VERSION ""

NS_ :

BS_:

BU_: ADAS ADASBUS_Virtual_ECU FCM GW PKC

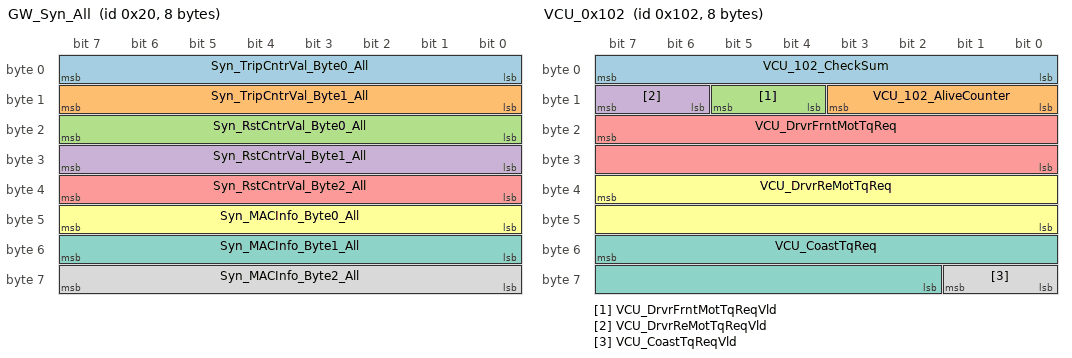
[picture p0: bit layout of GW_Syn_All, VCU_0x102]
BO_ 32 GW_Syn_All: 8 GW
 SG_ Syn_TripCntrVal_Byte0_All : 7|8@0+ (1,0) [0|255] ""  ADAS,PKC
 SG_ Syn_TripCntrVal_Byte1_All : 15|8@0+ (1,0) [0|255] ""  ADAS,PKC
 SG_ Syn_RstCntrVal_Byte0_All : 23|8@0+ (1,0) [0|255] ""  ADAS,PKC
 SG_ Syn_RstCntrVal_Byte1_All : 31|8@0+ (1,0) [0|255] ""  ADAS,PKC
 SG_ Syn_RstCntrVal_Byte2_All : 39|8@0+ (1,0) [0|255] ""  ADAS,PKC
 SG_ Syn_MACInfo_Byte0_All : 47|8@0+ (1,0) [0|255] ""  ADAS,PKC
 SG_ Syn_MACInfo_Byte1_All : 55|8@0+ (1,0) [0|255] ""  ADAS,PKC
 SG_ Syn_MACInfo_Byte2_All : 63|8@0+ (1,0) [0|255] ""  ADAS,PKC

BO_ 258 VCU_0x102: 8 GW
 SG_ VCU_102_CheckSum : 7|8@0+ (1,0) [0|255] ""  FCM
 SG_ VCU_102_AliveCounter : 11|4@0+ (1,0) [0|14] ""  FCM
 SG_ VCU_DrvrFrntMotTqReqVld : 13|2@0+ (1,0) [0|3] ""  ADASBUS_Virtual_ECU
 SG_ VCU_DrvrReMotTqReqVld : 15|2@0+ (1,0) [0|3] ""  ADASBUS_Virtual_ECU
 SG_ VCU_DrvrFrntMotTqReq : 23|16@0+ (1,-32768) [-32768|32767] "Nm"  ADASBUS_Virtual_ECU
 SG_ VCU_DrvrReMotTqReq : 39|16@0+ (1,-32768) [-32768|32767] "Nm"  ADASBUS_Virtual_ECU
 SG_ VCU_CoastTqReq : 55|14@0+ (1,-16383) [-16383|0] "Nm"  FCM
 SG_ VCU_CoastTqReqVld : 57|2@0+ (1,0) [0|3] ""  FCM

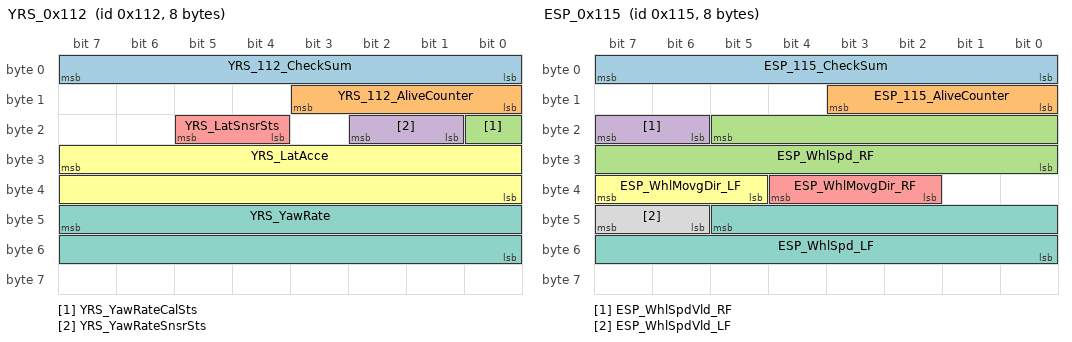
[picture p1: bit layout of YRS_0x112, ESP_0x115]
BO_ 274 YRS_0x112: 8 GW
 SG_ YRS_112_CheckSum : 7|8@0+ (1,0) [0|255] ""  ADAS,FCM
 SG_ YRS_112_AliveCounter : 11|4@0+ (1,0) [0|14] ""  ADAS,FCM
 SG_ YRS_YawRateCalSts : 16|1@0+ (1,0) [0|1] ""  ADAS,FCM
 SG_ YRS_YawRateSnsrSts : 18|2@0+ (1,0) [0|3] ""  ADAS,FCM
 SG_ YRS_LatSnsrSts : 21|2@0+ (1,0) [0|3] ""  ADAS,FCM
 SG_ YRS_LatAcce : 31|16@0+ (0.001,-2) [-2|2] "g"  ADAS,FCM
 SG_ YRS_YawRate : 47|16@0+ (0.01,-180) [-180|180] "deg/s"  ADAS,FCM

BO_ 275 YRS_0x113: 8 GW
 SG_ YRS_113_CheckSum : 7|8@0+ (1,0) [0|255] ""  ADAS,FCM
 SG_ YRS_113_AliveCounter : 11|4@0+ (1,0) [0|14] ""  ADAS,FCM
 SG_ YRS_LgtSnsrSts : 17|2@0+ (1,0) [0|3] ""  ADAS,FCM
 SG_ YRS_LgtAcce : 31|16@0+ (0.001,-2) [-2|2] "g"  ADAS,FCM

BO_ 276 ESP_0x114: 8 GW
 SG_ ESP_114_CheckSum : 7|8@0+ (1,0) [0|255] ""  ADAS,FCM
 SG_ ESP_114_AliveCounter : 11|4@0+ (1,0) [0|14] ""  ADAS,FCM
 SG_ ESP_OTARdy_Fb : 13|2@0+ (1,0) [0|3] ""  ADASBUS_Virtual_ECU
 SG_ ESP_FltIndcn_DTC : 15|1@0+ (1,0) [0|1] ""  ADAS
 SG_ ESP_ActvSig_VDC : 16|1@0+ (1,0) [0|1] ""  ADAS,FCM
 SG_ ESP_ActvSig_TCS : 17|1@0+ (1,0) [0|1] ""  ADAS
 SG_ ESP_ActvSig_EBD : 19|1@0+ (1,0) [0|1] ""  ADAS
 SG_ ESP_ActvSig_DTC : 20|1@0+ (1,0) [0|1] ""  ADAS
 SG_ ESP_WarningOn : 22|2@0+ (1,0) [0|3] ""  ADAS
 SG_ ESP_Actvndcn_CDD : 24|1@0+ (1,0) [0|1] ""  ADAS
 SG_ ESP_FltIndcn_CDD : 25|1@0+ (1,0) [0|1] ""  ADAS
 SG_ ESP_ActvIndcn_ABA : 26|1@0+ (1,0) [0|1] ""  ADAS
 SG_ ESP_FltIndcn_ABA : 27|1@0+ (1,0) [0|1] ""  ADAS
 SG_ ESP_ActvIndcn_ABP : 28|1@0+ (1,0) [0|1] ""  ADAS
 SG_ ESP_FltIndcn_ABP : 29|1@0+ (1,0) [0|1] ""  ADAS
 SG_ ESP_ActvIndcn_AEB : 30|1@0+ (1,0) [0|1] ""  ADAS,FCM
 SG_ ESP_FltIndcn_AEB : 31|1@0+ (1,0) [0|1] ""  ADAS,FCM
 SG_ ESP_ActvIndcn_AWB : 32|1@0+ (1,0) [0|1] ""  ADAS
 SG_ ESP_FltIndcn_AWB : 33|1@0+ (1,0) [0|1] ""  ADAS
 SG_ ESP_VehStandstillIndcn : 35|2@0+ (1,0) [0|3] ""  ADAS,FCM
 SG_ ESP_BrkOverTIndcn : 36|1@0+ (1,0) [0|1] ""  ADAS
 SG_ ESP_FltIndcn_VDC : 37|1@0+ (1,0) [0|1] ""  ADAS
 SG_ ESP_ActvIndcn_CDD_AP : 42|1@0+ (1,0) [0|1] ""  ADAS
 SG_ ESP_FltIndcn_CDD_AP : 43|1@0+ (1,0) [0|1] ""  ADAS

BO_ 277 ESP_0x115: 8 GW
 SG_ ESP_115_CheckSum : 7|8@0+ (1,0) [0|255] ""  ADAS,FCM,PKC
 SG_ ESP_115_AliveCounter : 11|4@0+ (1,0) [0|14] ""  ADAS,FCM,PKC
 SG_ ESP_WhlSpd_RF : 21|14@0+ (0.0625,0) [0|300] "km/h"  ADAS,FCM,PKC
 SG_ ESP_WhlSpdVld_RF : 23|2@0+ (1,0) [0|3] ""  ADAS,FCM,PKC
 SG_ ESP_WhlMovgDir_RF : 36|3@0+ (1,0) [0|7] ""  ADAS,FCM
 SG_ ESP_WhlMovgDir_LF : 39|3@0+ (1,0) [0|7] ""  ADAS,FCM
 SG_ ESP_WhlSpd_LF : 45|14@0+ (0.0625,0) [0|300] "km/h"  ADAS,FCM,PKC
 SG_ ESP_WhlSpdVld_LF : 47|2@0+ (1,0) [0|3] ""  ADAS,FCM,PKC

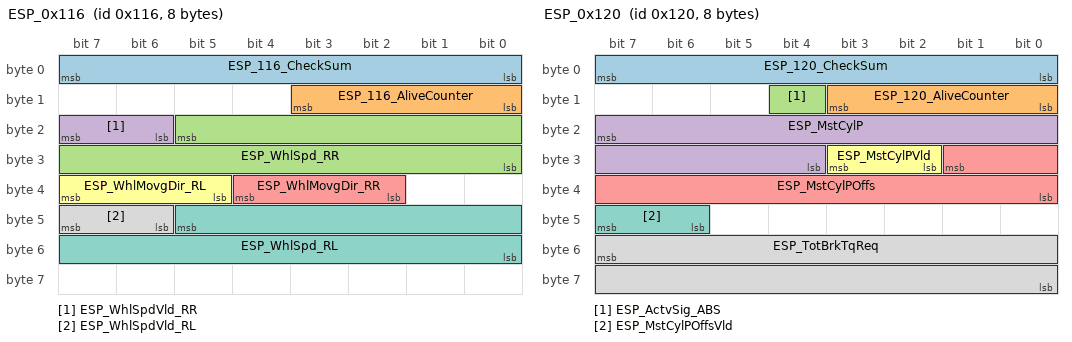
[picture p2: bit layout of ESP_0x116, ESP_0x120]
BO_ 278 ESP_0x116: 8 GW
 SG_ ESP_116_CheckSum : 7|8@0+ (1,0) [0|255] ""  ADAS,FCM,PKC
 SG_ ESP_116_AliveCounter : 11|4@0+ (1,0) [0|14] ""  ADAS,FCM,PKC
 SG_ ESP_WhlSpd_RR : 21|14@0+ (0.0625,0) [0|300] "km/h"  ADAS,FCM,PKC
 SG_ ESP_WhlSpdVld_RR : 23|2@0+ (1,0) [0|3] ""  ADAS,FCM,PKC
 SG_ ESP_WhlMovgDir_RR : 36|3@0+ (1,0) [0|7] ""  ADAS,FCM
 SG_ ESP_WhlMovgDir_RL : 39|3@0+ (1,0) [0|7] ""  ADAS,FCM
 SG_ ESP_WhlSpd_RL : 45|14@0+ (0.0625,0) [0|300] "km/h"  ADAS,FCM,PKC
 SG_ ESP_WhlSpdVld_RL : 47|2@0+ (1,0) [0|3] ""  ADAS,FCM,PKC

BO_ 279 ADAS_0x117: 8 ADAS
 SG_ ADAS_117_CheckSum : 7|8@0+ (1,0) [0|255] ""  GW
 SG_ ADAS_117_AliveCounter : 11|4@0+ (1,0) [0|14] ""  GW
 SG_ ADAS_OTARdy_Fb : 13|2@0+ (1,0) [0|3] ""  GW
 SG_ ADAS_OTAInhbRdy : 15|2@0+ (1,0) [0|3] ""  GW
 SG_ ADAS_LgtCtrl_Sts : 18|3@0+ (1,0) [0|7] ""  GW
 SG_ ADAS_LgtCtrl_StsVld : 20|2@0+ (1,0) [0|3] ""  GW
 SG_ ADAS_LgtCtrl_DrvrOvrdSts : 21|1@0+ (1,0) [0|1] ""  GW
 SG_ ADAS_LgtCtrl_DrvrOvrdVld : 23|2@0+ (1,0) [0|3] ""  GW
 SG_ ADAS_HAP_EmgyStandstillVld : 25|2@0+ (1,0) [0|3] ""  GW
 SG_ ADAS_HAP_EmgyEPBVld : 27|2@0+ (1,0) [0|3] ""  GW
 SG_ ADAS_HAP_EmgyStandstillReq : 28|1@0+ (1,0) [0|1] ""  GW
 SG_ ADAS_ParkStandstillReq : 29|1@0+ (1,0) [0|1] ""  GW
 SG_ ADAS_ParkStandstillVld : 31|2@0+ (1,0) [0|3] ""  GW
 SG_ ADAS_ParkGearReq : 35|4@0+ (1,0) [0|15] ""  GW
 SG_ ADAS_ParkGearReqVld : 37|2@0+ (1,0) [0|3] ""  GW
 SG_ ADAS_ISA_CutOffReqVld : 39|2@0+ (1,0) [0|3] ""  GW
 SG_ ADAS_LgtCtrl_Typ : 43|4@0+ (1,0) [0|15] ""  GW
 SG_ ADAS_HAP_EmgyEPBReq : 44|1@0+ (1,0) [0|1] ""  GW
 SG_ ADAS_ISA_CutOffReq : 46|1@0+ (1,0) [0|1] ""  GW
 SG_ ADAS_ISA_SpdLmt_VCU : 63|8@0+ (1,0) [0|255] "kph"  GW

BO_ 280 ADAS_0x118: 8 ADAS
 SG_ ADAS_118_CheckSum : 7|8@0+ (1,0) [0|255] ""  GW
 SG_ ADAS_118_AliveCounter : 11|4@0+ (1,0) [0|14] ""  GW
 SG_ ADAS_LgtCtrl_ESP_Sts : 18|3@0+ (1,0) [0|7] ""  GW
 SG_ ADAS_LgtCtrl_ESP_Vld : 20|2@0+ (1,0) [0|3] ""  GW
 SG_ ADAS_ESP_DrvrOvrdSts : 21|1@0+ (1,0) [0|1] ""  GW
 SG_ ADAS_ESP_DrvrOvrdVld : 23|2@0+ (1,0) [0|3] ""  GW
 SG_ ADAS_HBAReq : 26|3@0+ (1,0) [0|7] ""  GW
 SG_ ADAS_HBAVld : 28|2@0+ (1,0) [0|3] ""  GW
 SG_ ADAS_ESP_StandstillReq : 29|1@0+ (1,0) [0|1] ""  GW
 SG_ ADAS_ESP_StandstillVld : 31|2@0+ (1,0) [0|3] ""  GW
 SG_ ADAS_JerkReq : 33|2@0+ (1,0) [0|3] ""  GW
 SG_ ADAS_JerkReqVld : 35|2@0+ (1,0) [0|3] ""  GW
 SG_ ADAS_BrkPrefillReq : 37|2@0+ (1,0) [0|3] ""  GW
 SG_ ADAS_BrkPrefillVld : 39|2@0+ (1,0) [0|3] ""  GW
 SG_ ADAS_AEB_ActvTyp : 43|4@0+ (1,0) [0|15] ""  GW
 SG_ ADAS_AEB_DecelVld : 45|2@0+ (1,0) [0|3] ""  GW
 SG_ ADAS_AEB_DecelReq : 55|16@0+ (0.0004882,-16) [-16|15.994187] "m/s2"  GW

BO_ 288 ESP_0x120: 8 GW
 SG_ ESP_120_CheckSum : 7|8@0+ (1,0) [0|255] ""  ADAS,FCM
 SG_ ESP_120_AliveCounter : 11|4@0+ (1,0) [0|14] ""  ADAS,FCM
 SG_ ESP_ActvSig_ABS : 12|1@0+ (1,0) [0|1] ""  ADAS,FCM
 SG_ ESP_MstCylP : 23|12@0+ (0.1,-30) [-30|276.6] "bar"  ADAS,FCM
 SG_ ESP_MstCylPOffs : 25|10@0+ (0.1,-15) [-15|15] "bar"  ADAS,FCM
 SG_ ESP_MstCylPVld : 27|2@0+ (1,0) [0|3] ""  ADAS,FCM
 SG_ ESP_MstCylPOffsVld : 47|2@0+ (1,0) [0|3] ""  ADAS,FCM
 SG_ ESP_TotBrkTqReq : 55|16@0+ (1,-30000) [-30000|30000] "Nm"  ADAS

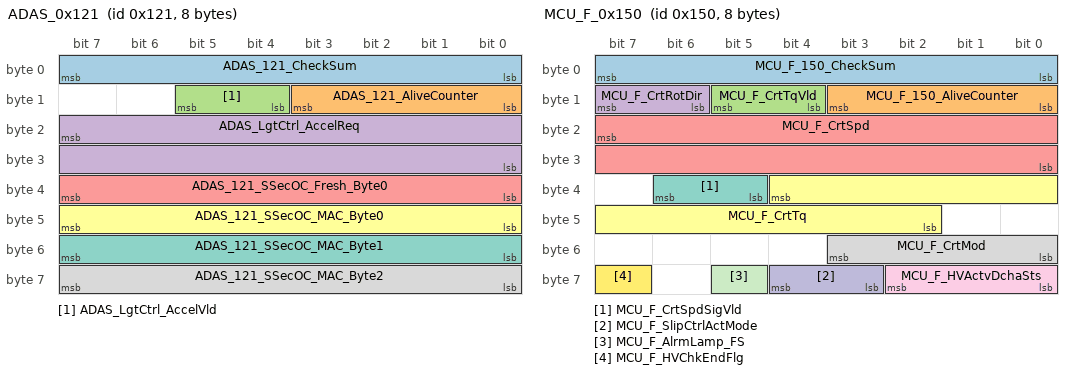
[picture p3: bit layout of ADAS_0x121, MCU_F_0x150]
BO_ 289 ADAS_0x121: 8 ADAS
 SG_ ADAS_121_CheckSum : 7|8@0+ (1,0) [0|255] ""  GW
 SG_ ADAS_121_AliveCounter : 11|4@0+ (1,0) [0|14] ""  GW
 SG_ ADAS_LgtCtrl_AccelVld : 13|2@0+ (1,0) [0|3] ""  GW
 SG_ ADAS_LgtCtrl_AccelReq : 23|16@0+ (0.0004882,-16) [-16|15.994187] "m/s2"  GW
 SG_ ADAS_121_SSecOC_Fresh_Byte0 : 39|8@0+ (1,0) [0|255] ""  GW
 SG_ ADAS_121_SSecOC_MAC_Byte0 : 47|8@0+ (1,0) [0|255] ""  GW
 SG_ ADAS_121_SSecOC_MAC_Byte1 : 55|8@0+ (1,0) [0|255] ""  GW
 SG_ ADAS_121_SSecOC_MAC_Byte2 : 63|8@0+ (1,0) [0|255] ""  GW

BO_ 336 MCU_F_0x150: 8 GW
 SG_ MCU_F_150_CheckSum : 7|8@0+ (1,0) [0|255] ""  ADAS
 SG_ MCU_F_150_AliveCounter : 11|4@0+ (1,0) [0|14] ""  ADAS
 SG_ MCU_F_CrtTqVld : 13|2@0+ (1,0) [0|3] ""  ADAS
 SG_ MCU_F_CrtRotDir : 15|2@0+ (1,0) [0|3] ""  ADAS
 SG_ MCU_F_CrtSpd : 23|16@0+ (1,-32768) [-32768|32767] "rpm"  ADAS,FCM,PKC
 SG_ MCU_F_CrtTq : 36|11@0+ (0.5,-511) [-511|512] "Nm"  ADAS
 SG_ MCU_F_CrtSpdSigVld : 38|2@0+ (1,0) [0|3] ""  ADAS,FCM,PKC
 SG_ MCU_F_CrtMod : 51|4@0+ (1,0) [0|15] ""  ADASBUS_Virtual_ECU
 SG_ MCU_F_HVActvDchaSts : 58|3@0+ (1,0) [0|7] ""  ADASBUS_Virtual_ECU
 SG_ MCU_F_SlipCtrlActMode : 60|2@0+ (1,0) [0|3] ""  ADAS
 SG_ MCU_F_AlrmLamp_FS : 61|1@0+ (1,0) [0|1] ""  ADASBUS_Virtual_ECU
 SG_ MCU_F_HVChkEndFlg : 63|1@0+ (1,0) [0|1] ""  ADASBUS_Virtual_ECU

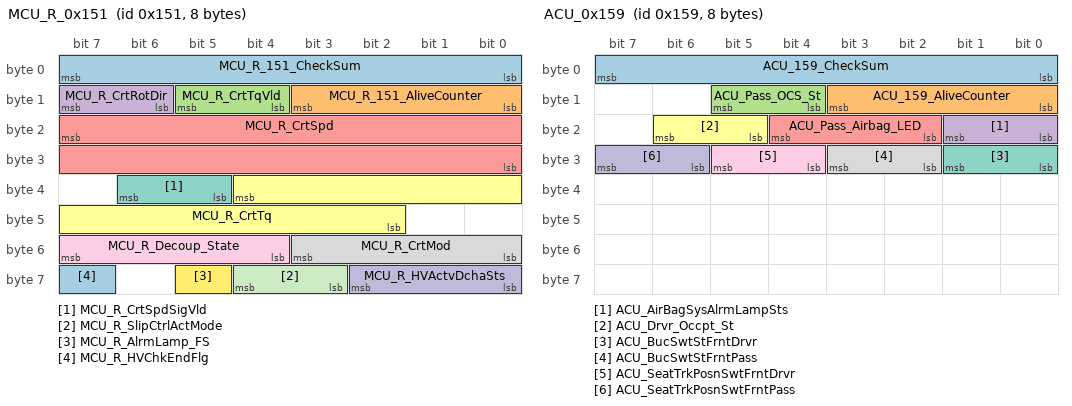
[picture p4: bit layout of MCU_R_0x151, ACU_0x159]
BO_ 337 MCU_R_0x151: 8 GW
 SG_ MCU_R_151_CheckSum : 7|8@0+ (1,0) [0|255] ""  ADAS,ADASBUS_Virtual_ECU
 SG_ MCU_R_151_AliveCounter : 11|4@0+ (1,0) [0|14] ""  ADAS,ADASBUS_Virtual_ECU
 SG_ MCU_R_CrtTqVld : 13|2@0+ (1,0) [0|3] ""  ADAS
 SG_ MCU_R_CrtRotDir : 15|2@0+ (1,0) [0|3] ""  ADAS
 SG_ MCU_R_CrtSpd : 23|16@0+ (1,-32768) [-32768|32767] "rpm"  ADAS,FCM,PKC
 SG_ MCU_R_CrtTq : 36|11@0+ (0.5,-511) [-511|512] "Nm"  ADAS
 SG_ MCU_R_CrtSpdSigVld : 38|2@0+ (1,0) [0|3] ""  ADAS,FCM,PKC
 SG_ MCU_R_CrtMod : 51|4@0+ (1,0) [0|15] ""  ADASBUS_Virtual_ECU
 SG_ MCU_R_Decoup_State : 55|4@0+ (1,0) [0|15] ""  ADASBUS_Virtual_ECU
 SG_ MCU_R_HVActvDchaSts : 58|3@0+ (1,0) [0|7] ""  ADASBUS_Virtual_ECU
 SG_ MCU_R_SlipCtrlActMode : 60|2@0+ (1,0) [0|3] ""  ADAS
 SG_ MCU_R_AlrmLamp_FS : 61|1@0+ (1,0) [0|1] ""  ADASBUS_Virtual_ECU
 SG_ MCU_R_HVChkEndFlg : 63|1@0+ (1,0) [0|1] ""  ADASBUS_Virtual_ECU

BO_ 345 ACU_0x159: 8 GW
 SG_ ACU_159_CheckSum : 7|8@0+ (1,0) [0|255] ""  ADAS,FCM
 SG_ ACU_159_AliveCounter : 11|4@0+ (1,0) [0|14] ""  ADAS,FCM
 SG_ ACU_Pass_OCS_St : 13|2@0+ (1,0) [0|3] ""  PKC
 SG_ ACU_AirBagSysAlrmLampSts : 17|2@0+ (1,0) [0|3] ""  ADAS
 SG_ ACU_Pass_Airbag_LED : 20|3@0+ (1,0) [0|7] ""  ADAS
 SG_ ACU_Drvr_Occpt_St : 22|2@0+ (1,0) [0|3] ""  ADAS,FCM,PKC
 SG_ ACU_BucSwtStFrntDrvr : 25|2@0+ (1,0) [0|3] ""  ADAS,FCM
 SG_ ACU_BucSwtStFrntPass : 27|2@0+ (1,0) [0|3] ""  ADAS
 SG_ ACU_SeatTrkPosnSwtFrntDrvr : 29|2@0+ (1,0) [0|3] ""  ADASBUS_Virtual_ECU
 SG_ ACU_SeatTrkPosnSwtFrntPass : 31|2@0+ (1,0) [0|3] ""  ADASBUS_Virtual_ECU

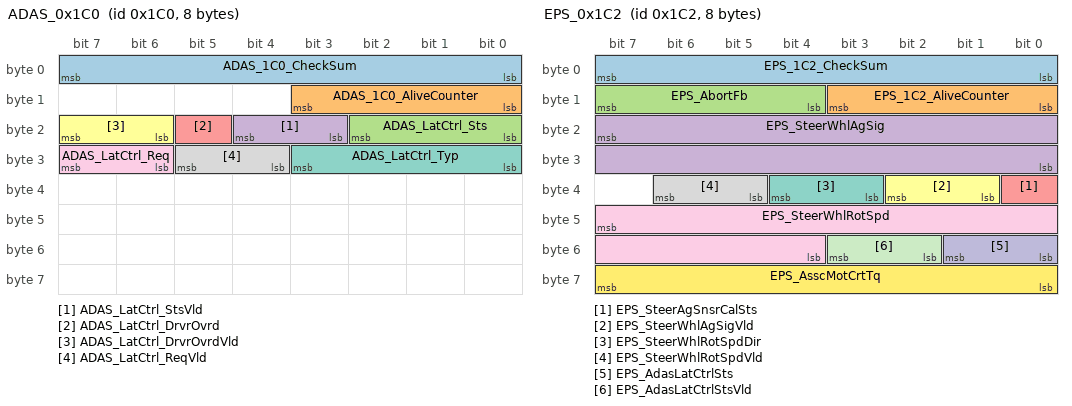
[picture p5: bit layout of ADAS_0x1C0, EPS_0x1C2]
BO_ 448 ADAS_0x1C0: 8 ADAS
 SG_ ADAS_1C0_CheckSum : 7|8@0+ (1,0) [0|255] ""  GW
 SG_ ADAS_1C0_AliveCounter : 11|4@0+ (1,0) [0|14] ""  GW
 SG_ ADAS_LatCtrl_Sts : 18|3@0+ (1,0) [0|7] ""  GW
 SG_ ADAS_LatCtrl_StsVld : 20|2@0+ (1,0) [0|3] ""  GW
 SG_ ADAS_LatCtrl_DrvrOvrd : 21|1@0+ (1,0) [0|1] ""  GW
 SG_ ADAS_LatCtrl_DrvrOvrdVld : 23|2@0+ (1,0) [0|3] ""  GW
 SG_ ADAS_LatCtrl_Typ : 27|4@0+ (1,0) [0|15] ""  GW
 SG_ ADAS_LatCtrl_ReqVld : 29|2@0+ (1,0) [0|3] ""  GW
 SG_ ADAS_LatCtrl_Req : 31|2@0+ (1,0) [0|3] ""  GW

BO_ 450 EPS_0x1C2: 8 GW
 SG_ EPS_1C2_CheckSum : 7|8@0+ (1,0) [0|255] ""  ADAS,FCM,PKC
 SG_ EPS_1C2_AliveCounter : 11|4@0+ (1,0) [0|14] ""  ADAS,FCM,PKC
 SG_ EPS_AbortFb : 15|4@0+ (1,0) [0|15] ""  ADAS
 SG_ EPS_SteerWhlAgSig : 23|16@0+ (0.0625,-780) [-780|780] "deg"  ADAS,FCM,PKC
 SG_ EPS_SteerAgSnsrCalSts : 32|1@0+ (1,0) [0|1] ""  ADAS,FCM
 SG_ EPS_SteerWhlAgSigVld : 34|2@0+ (1,0) [0|3] ""  ADAS,FCM
 SG_ EPS_SteerWhlRotSpdDir : 36|2@0+ (1,0) [0|3] ""  ADAS
 SG_ EPS_SteerWhlRotSpdVld : 38|2@0+ (1,0) [0|3] ""  ADAS,FCM
 SG_ EPS_SteerWhlRotSpd : 47|12@0+ (0.5,-1016) [-1016|1016] "deg/s"  ADAS,FCM
 SG_ EPS_AdasLatCtrlSts : 49|2@0+ (1,0) [0|3] ""  ADAS
 SG_ EPS_AdasLatCtrlStsVld : 51|2@0+ (1,0) [0|3] ""  ADAS
 SG_ EPS_AsscMotCrtTq : 63|8@0+ (0.1,0) [0|10] "Nm"  ADASBUS_Virtual_ECU

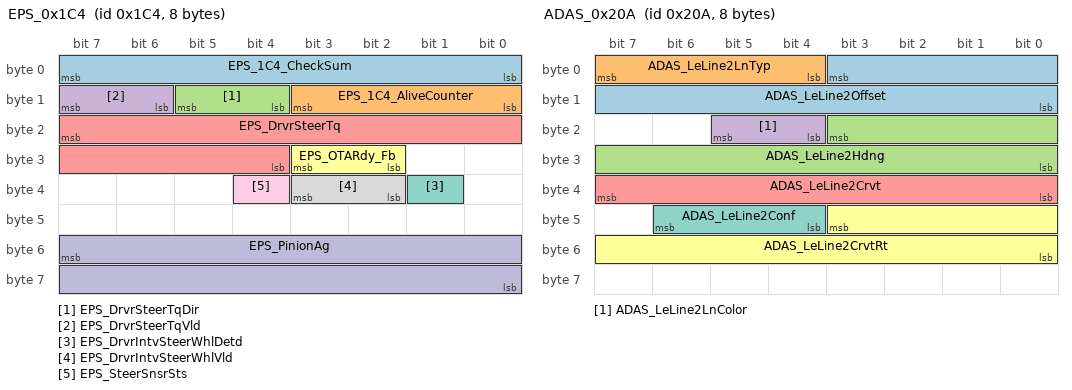
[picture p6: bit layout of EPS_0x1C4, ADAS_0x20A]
BO_ 452 EPS_0x1C4: 8 GW
 SG_ EPS_1C4_CheckSum : 7|8@0+ (1,0) [0|255] ""  ADAS,FCM
 SG_ EPS_1C4_AliveCounter : 11|4@0+ (1,0) [0|14] ""  ADAS,FCM
 SG_ EPS_DrvrSteerTqDir : 13|2@0+ (1,0) [0|3] ""  ADAS
 SG_ EPS_DrvrSteerTqVld : 15|2@0+ (1,0) [0|3] ""  ADAS
 SG_ EPS_DrvrSteerTq : 23|12@0+ (0.01,0) [0|8] "Nm"  ADAS
 SG_ EPS_OTARdy_Fb : 27|2@0+ (1,0) [0|3] ""  ADASBUS_Virtual_ECU
 SG_ EPS_DrvrIntvSteerWhlDetd : 33|1@0+ (1,0) [0|1] ""  ADAS
 SG_ EPS_DrvrIntvSteerWhlVld : 35|2@0+ (1,0) [0|3] ""  ADAS
 SG_ EPS_SteerSnsrSts : 36|1@0+ (1,0) [0|1] ""  ADAS,FCM
 SG_ EPS_PinionAg : 55|16@0+ (0.0625,-780) [-780|780] "deg"  ADAS

BO_ 464 ADAS_0x1D0: 8 ADAS
 SG_ ADAS_1D0_CheckSum : 7|8@0+ (1,0) [0|255] ""  GW
 SG_ ADAS_1D0_AliveCounter : 11|4@0+ (1,0) [0|14] ""  GW
 SG_ ADAS_LatCtrl_SteerAnReq : 23|16@0+ (0.0625,-780) [-780|780] "deg"  GW
 SG_ ADAS_1D0_SSecOC_Fresh_Byte0 : 39|8@0+ (1,0) [0|255] ""  GW
 SG_ ADAS_1D0_SSecOC_MAC_Byte0 : 47|8@0+ (1,0) [0|255] ""  GW
 SG_ ADAS_1D0_SSecOC_MAC_Byte1 : 55|8@0+ (1,0) [0|255] ""  GW
 SG_ ADAS_1D0_SSecOC_MAC_Byte2 : 63|8@0+ (1,0) [0|255] ""  GW

BO_ 522 ADAS_0x20A: 8 ADAS
 SG_ ADAS_LeLine2Offset : 3|12@0+ (0.0125,0) [0|50] "m"  GW
 SG_ ADAS_LeLine2LnTyp : 7|4@0+ (1,0) [0|15] ""  GW
 SG_ ADAS_LeLine2Hdng : 19|12@0+ (0.05,0) [0|180] "deg"  GW
 SG_ ADAS_LeLine2LnColor : 21|2@0+ (1,0) [0|3] ""  GW
 SG_ ADAS_LeLine2Crvt : 39|8@0+ (50,-3150) [-3150|3200] "m"  GW
 SG_ ADAS_LeLine2CrvtRt : 43|12@0+ (0.05,0) [0|180] "xx"  GW
 SG_ ADAS_LeLine2Conf : 46|3@0+ (1,0) [0|7] ""  GW

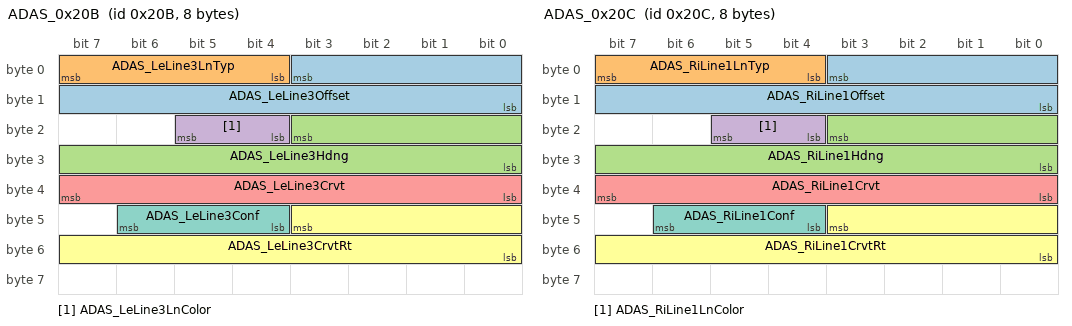
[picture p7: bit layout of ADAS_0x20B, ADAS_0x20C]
BO_ 523 ADAS_0x20B: 8 ADAS
 SG_ ADAS_LeLine3Offset : 3|12@0+ (0.0125,0) [0|50] "m"  GW
 SG_ ADAS_LeLine3LnTyp : 7|4@0+ (1,0) [0|15] ""  GW
 SG_ ADAS_LeLine3Hdng : 19|12@0+ (0.05,0) [0|180] "deg"  GW
 SG_ ADAS_LeLine3LnColor : 21|2@0+ (1,0) [0|3] ""  GW
 SG_ ADAS_LeLine3Crvt : 39|8@0+ (50,-3150) [-3150|3200] "m"  GW
 SG_ ADAS_LeLine3CrvtRt : 43|12@0+ (0.0125,0) [0|50] "xx"  GW
 SG_ ADAS_LeLine3Conf : 46|3@0+ (1,0) [0|7] ""  GW

BO_ 524 ADAS_0x20C: 8 ADAS
 SG_ ADAS_RiLine1Offset : 3|12@0+ (0.0125,0) [0|50] "m"  GW
 SG_ ADAS_RiLine1LnTyp : 7|4@0+ (1,0) [0|15] ""  GW
 SG_ ADAS_RiLine1Hdng : 19|12@0+ (0.05,0) [0|180] "deg"  GW
 SG_ ADAS_RiLine1LnColor : 21|2@0+ (1,0) [0|3] ""  GW
 SG_ ADAS_RiLine1Crvt : 39|8@0+ (50,-3150) [-3150|3200] "m"  GW
 SG_ ADAS_RiLine1CrvtRt : 43|12@0+ (0.0125,0) [0|50] "xx"  GW
 SG_ ADAS_RiLine1Conf : 46|3@0+ (1,0) [0|7] ""  GW

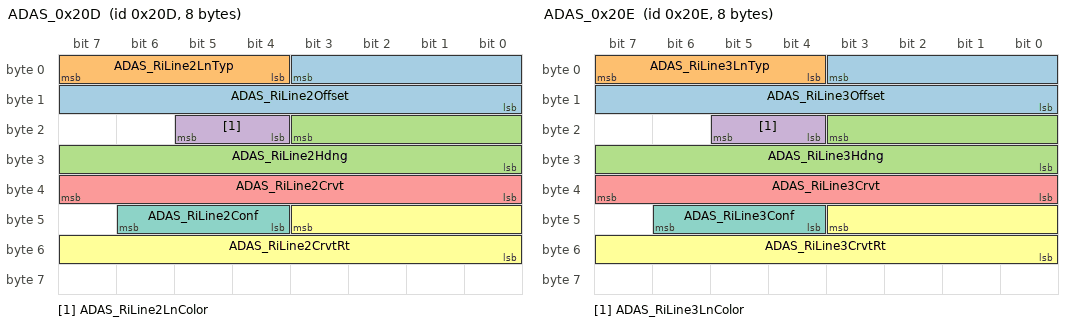
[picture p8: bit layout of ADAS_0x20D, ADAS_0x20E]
BO_ 525 ADAS_0x20D: 8 ADAS
 SG_ ADAS_RiLine2Offset : 3|12@0+ (0.0125,0) [0|50] "m"  GW
 SG_ ADAS_RiLine2LnTyp : 7|4@0+ (1,0) [0|15] ""  GW
 SG_ ADAS_RiLine2Hdng : 19|12@0+ (0.05,0) [0|180] "deg"  GW
 SG_ ADAS_RiLine2LnColor : 21|2@0+ (1,0) [0|3] ""  GW
 SG_ ADAS_RiLine2Crvt : 39|8@0+ (50,-3150) [-3150|3200] "m"  GW
 SG_ ADAS_RiLine2CrvtRt : 43|12@0+ (0.0125,0) [0|50] "xx"  GW
 SG_ ADAS_RiLine2Conf : 46|3@0+ (1,0) [0|7] ""  GW

BO_ 526 ADAS_0x20E: 8 ADAS
 SG_ ADAS_RiLine3Offset : 3|12@0+ (0.0125,0) [0|50] "m"  GW
 SG_ ADAS_RiLine3LnTyp : 7|4@0+ (1,0) [0|15] ""  GW
 SG_ ADAS_RiLine3Hdng : 19|12@0+ (0.05,0) [0|180] "deg"  GW
 SG_ ADAS_RiLine3LnColor : 21|2@0+ (1,0) [0|3] ""  GW
 SG_ ADAS_RiLine3Crvt : 39|8@0+ (50,-3150) [-3150|3200] "m"  GW
 SG_ ADAS_RiLine3CrvtRt : 43|12@0+ (0.0125,0) [0|50] "xx"  GW
 SG_ ADAS_RiLine3Conf : 46|3@0+ (1,0) [0|7] ""  GW

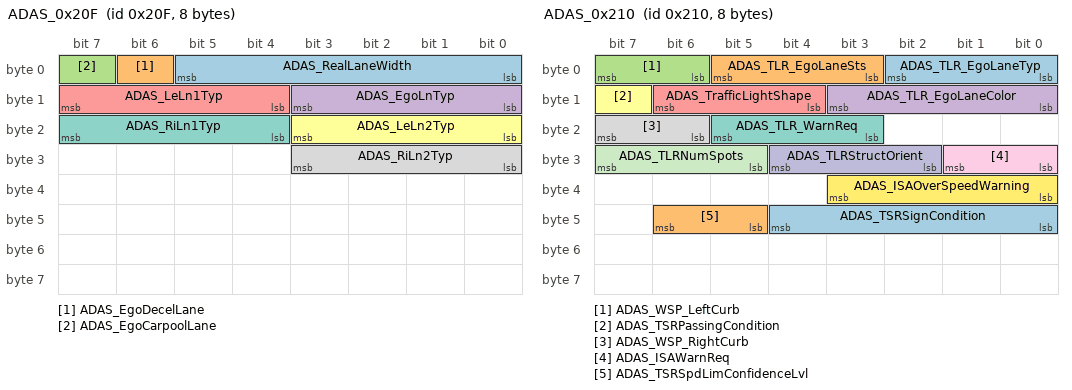
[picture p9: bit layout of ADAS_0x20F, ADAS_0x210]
BO_ 527 ADAS_0x20F: 8 ADAS
 SG_ ADAS_RealLaneWidth : 5|6@0+ (0.1,0) [0|6.3] "m"  GW
 SG_ ADAS_EgoDecelLane : 6|1@0+ (1,0) [0|1] ""  GW
 SG_ ADAS_EgoCarpoolLane : 7|1@0+ (1,0) [0|1] ""  GW
 SG_ ADAS_EgoLnTyp : 11|4@0+ (1,0) [0|15] ""  GW
 SG_ ADAS_LeLn1Typ : 15|4@0+ (1,0) [0|15] ""  GW
 SG_ ADAS_LeLn2Typ : 19|4@0+ (1,0) [0|15] ""  GW
 SG_ ADAS_RiLn1Typ : 23|4@0+ (1,0) [0|15] ""  GW
 SG_ ADAS_RiLn2Typ : 27|4@0+ (1,0) [0|15] ""  GW

BO_ 528 ADAS_0x210: 8 ADAS
 SG_ ADAS_TLR_EgoLaneTyp : 2|3@0+ (1,0) [0|7] ""  GW
 SG_ ADAS_TLR_EgoLaneSts : 5|3@0+ (1,0) [0|7] ""  GW
 SG_ ADAS_WSP_LeftCurb : 7|2@0+ (1,0) [0|3] ""  GW
 SG_ ADAS_TLR_EgoLaneColor : 11|4@0+ (1,0) [0|15] ""  GW
 SG_ ADAS_TrafficLightShape : 14|3@0+ (1,0) [0|7] ""  GW
 SG_ ADAS_TSRPassingCondition : 15|1@0+ (1,0) [0|1] ""  GW
 SG_ ADAS_TLR_WarnReq : 21|3@0+ (1,0) [0|7] ""  GW
 SG_ ADAS_WSP_RightCurb : 23|2@0+ (1,0) [0|3] ""  GW
 SG_ ADAS_ISAWarnReq : 25|2@0+ (1,0) [0|3] ""  GW
 SG_ ADAS_TLRStructOrient : 28|3@0+ (1,0) [0|7] ""  GW
 SG_ ADAS_TLRNumSpots : 31|3@0+ (1,0) [0|7] ""  GW
 SG_ ADAS_ISAOverSpeedWarning : 35|4@0+ (1,0) [0|15] ""  GW
 SG_ ADAS_TSRSignCondition : 44|5@0+ (1,0) [0|31] ""  GW
 SG_ ADAS_TSRSpdLimConfidenceLvl : 46|2@0+ (1,0) [0|3] ""  GW

BO_ 532 VCU_0x214: 16 GW
 SG_ VCU_214_234_CheckSum : 7|8@0+ (1,0) [0|255] ""  ADAS,FCM,PKC
 SG_ VCU_214_234_AliveCounter : 11|4@0+ (1,0) [0|14] ""  ADAS,FCM,PKC
 SG_ VCU_RdyLamp : 12|1@0+ (1,0) [0|1] ""  ADAS,PKC
 SG_ VCU_BrkLampCtrlSts : 14|1@0+ (1,0) [0|1] ""  ADASBUS_Virtual_ECU
 SG_ VCU_RemWakeUpEndFlg : 15|1@0+ (1,0) [0|1] ""  ADASBUS_Virtual_ECU
 SG_ VCU_StgyGearSig : 19|4@0+ (1,0) [0|15] ""  ADAS
 SG_ VCU_ShiftMisoper : 21|1@0+ (1,0) [0|1] ""  ADAS
 SG_ VCU_GearSigVld : 23|2@0+ (1,0) [0|3] ""  ADAS,FCM,PKC
 SG_ VCU_GearSig : 27|4@0+ (1,0) [0|15] ""  ADAS,FCM,PKC
 SG_ VCU_ACCRdy : 28|1@0+ (1,0) [0|1] ""  ADAS
 SG_ VCU_ParkRdy : 29|1@0+ (1,0) [0|1] ""  ADAS
 SG_ VCU_APSPercVld : 31|2@0+ (1,0) [0|3] ""  ADAS,FCM
 SG_ VCU_VehSt : 39|16@0+ (1,0) [0|65535] ""  ADAS
 SG_ VCU_APSPerc : 55|8@0+ (0.4,0) [0|100] "%"  ADAS,FCM
 SG_ VCU_BrkSig : 56|1@0+ (1,0) [0|1] ""  ADAS,FCM,PKC
 SG_ VCU_BrkSigVld : 58|2@0+ (1,0) [0|3] ""  ADAS,FCM,PKC
 SG_ VCU_DrvModSigFb : 61|3@0+ (1,0) [0|7] ""  ADAS
 SG_ VCU_DrvModShiftMisoper : 62|1@0+ (1,0) [0|1] ""  ADASBUS_Virtual_ECU
 SG_ VCU_SpclTerrainModEnaSig : 63|1@0+ (1,0) [0|1] ""  ADASBUS_Virtual_ECU
 SG_ VCU_214_SSecOC_Fresh_Byte0 : 71|8@0+ (1,0) [0|255] ""  ADASBUS_Virtual_ECU
 SG_ VCU_214_SSecOC_MAC_Byte0 : 79|8@0+ (1,0) [0|255] ""  ADASBUS_Virtual_ECU
 SG_ VCU_214_SSecOC_MAC_Byte1 : 87|8@0+ (1,0) [0|255] ""  ADASBUS_Virtual_ECU
 SG_ VCU_214_SSecOC_MAC_Byte2 : 95|8@0+ (1,0) [0|255] ""  ADASBUS_Virtual_ECU

BO_ 537 VCU_0x219: 8 GW
 SG_ VCU_219_CheckSum : 7|8@0+ (1,0) [0|255] ""  ADAS,PKC
 SG_ VCU_219_AliveCounter : 11|4@0+ (1,0) [0|14] ""  ADAS,PKC
 SG_ VCU_PreCdtFB : 13|2@0+ (1,0) [0|3] ""  ADASBUS_Virtual_ECU
 SG_ VCU_IMMO_Sts : 15|2@0+ (1,0) [0|3] ""  PKC
 SG_ VCU_RemCtrlDrvgSts : 23|3@0+ (1,0) [0|7] ""  PKC
 SG_ VCU_TioutPwrOffReq : 24|1@0+ (1,0) [0|1] ""  PKC
 SG_ VCU_RemCtrlDrvgEnaFlg : 25|1@0+ (1,0) [0|1] ""  ADAS,PKC
 SG_ VCU_RemCtrlDrvgEnaFlgVld : 27|2@0+ (1,0) [0|3] ""  ADAS
 SG_ VCU_RemCtrlDrvgPwrOnReq : 29|2@0+ (1,0) [0|3] ""  ADASBUS_Virtual_ECU
 SG_ VCU_RemCtrlDrvgExitFlg : 34|1@0+ (1,0) [0|1] ""  ADASBUS_Virtual_ECU
 SG_ VCU_RemCtrlDrvgRelsReq : 35|1@0+ (1,0) [0|1] ""  ADASBUS_Virtual_ECU
 SG_ VCU_RemCtrlDrvgExitDisp : 39|4@0+ (1,0) [0|15] ""  PKC
 SG_ VCU_RemCtrlDrvgBrkReq : 40|1@0+ (1,0) [0|1] ""  ADASBUS_Virtual_ECU
 SG_ VCU_RemCtrlDrvgEmgyBrkReq : 41|1@0+ (1,0) [0|1] ""  ADASBUS_Virtual_ECU
 SG_ VCU_RemCtrlDrvgModClsReq_VLC : 43|2@0+ (1,0) [0|3] ""  ADASBUS_Virtual_ECU
 SG_ VCU_DrvrIntvGearSigVld : 47|2@0+ (1,0) [0|3] ""  ADAS
 SG_ VCU_DrvrIntvGearSig : 48|1@0+ (1,0) [0|1] ""  ADAS
 SG_ VCU_GearUnderCtrlSts : 54|3@0+ (1,0) [0|7] ""  ADAS
 SG_ VCU_PrefillReq : 55|1@0+ (1,0) [0|1] ""  ADASBUS_Virtual_ECU
 SG_ VCU_VehSecureHold : 56|1@0+ (1,0) [0|1] ""  ADASBUS_Virtual_ECU
 SG_ VCU_VehSecureRels : 57|1@0+ (1,0) [0|1] ""  ADASBUS_Virtual_ECU
 SG_ VCU_AxReqActv : 59|2@0+ (1,0) [0|3] ""  ADAS
 SG_ VCU_SpclTerrainModReq : 62|3@0+ (1,0) [0|7] ""  ADASBUS_Virtual_ECU

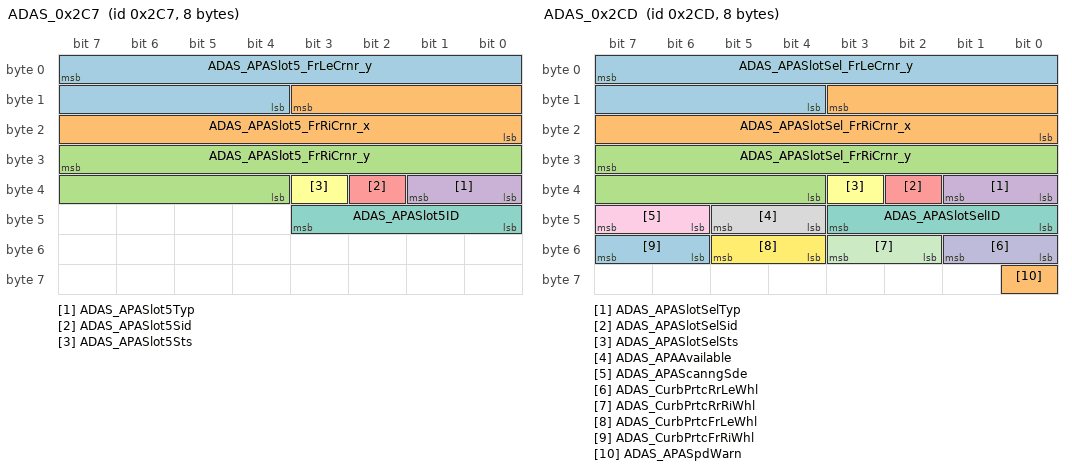
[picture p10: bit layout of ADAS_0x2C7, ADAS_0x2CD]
BO_ 711 ADAS_0x2C7: 8 ADAS
 SG_ ADAS_APASlot5_FrLeCrnr_y : 7|12@0+ (0.05,-100) [-100|100] "m"  GW
 SG_ ADAS_APASlot5_FrRiCrnr_x : 11|12@0+ (0.05,-100) [-100|100] "m"  GW
 SG_ ADAS_APASlot5_FrRiCrnr_y : 31|12@0+ (0.05,-100) [-100|100] "m"  GW
 SG_ ADAS_APASlot5Typ : 33|2@0+ (1,0) [0|3] ""  GW
 SG_ ADAS_APASlot5Sid : 34|1@0+ (1,0) [0|1] ""  GW
 SG_ ADAS_APASlot5Sts : 35|1@0+ (1,0) [0|1] ""  GW
 SG_ ADAS_APASlot5ID : 43|4@0+ (1,0) [0|15] ""  GW

BO_ 714 ADAS_0x2CA: 8 ADAS
 SG_ ADAS_APASlotSel_ReLeCrnr_x : 7|12@0+ (0.05,-100) [-100|100] "m"  GW
 SG_ ADAS_APASlotSel_ReLeCrnr_y : 11|12@0+ (0.05,-100) [-100|100] "m"  GW
 SG_ ADAS_APASlotSel_ReRiCrnr_x : 31|12@0+ (0.05,-100) [-100|100] "m"  GW
 SG_ ADAS_APASlotSel_ReRiCrnr_y : 35|12@0+ (0.05,-100) [-100|100] "m"  GW
 SG_ ADAS_APASlotSel_FrLeCrnr_x : 55|12@0+ (0.05,-100) [-100|100] "m"  GW

BO_ 717 ADAS_0x2CD: 8 ADAS
 SG_ ADAS_APASlotSel_FrLeCrnr_y : 7|12@0+ (0.05,-100) [-100|100] "m"  GW
 SG_ ADAS_APASlotSel_FrRiCrnr_x : 11|12@0+ (0.05,-100) [-100|100] "m"  GW
 SG_ ADAS_APASlotSel_FrRiCrnr_y : 31|12@0+ (0.05,-100) [-100|100] "m"  GW
 SG_ ADAS_APASlotSelTyp : 33|2@0+ (1,0) [0|3] ""  GW
 SG_ ADAS_APASlotSelSid : 34|1@0+ (1,0) [0|1] ""  GW
 SG_ ADAS_APASlotSelSts : 35|1@0+ (1,0) [0|1] ""  GW
 SG_ ADAS_APASlotSelID : 43|4@0+ (1,0) [0|15] ""  GW
 SG_ ADAS_APAAvailable : 45|2@0+ (1,0) [0|3] ""  GW
 SG_ ADAS_APAScanngSde : 47|2@0+ (1,0) [0|3] ""  GW
 SG_ ADAS_CurbPrtcRrLeWhl : 49|2@0+ (1,0) [0|3] ""  GW
 SG_ ADAS_CurbPrtcRrRiWhl : 51|2@0+ (1,0) [0|3] ""  GW
 SG_ ADAS_CurbPrtcFrLeWhl : 53|2@0+ (1,0) [0|3] ""  GW
 SG_ ADAS_CurbPrtcFrRiWhl : 55|2@0+ (1,0) [0|3] ""  GW
 SG_ ADAS_APASpdWarn : 56|1@0+ (1,0) [0|1] ""  GW

BO_ 720 ADAS_0x2D0: 8 ADAS
 SG_ ADAS_APASlot1_ReLeCrnr_x : 7|12@0+ (0.05,-100) [-100|100] "m"  GW
 SG_ ADAS_APASlot1_ReLeCrnr_y : 11|12@0+ (0.05,-100) [-100|100] "m"  GW
 SG_ ADAS_APASlot1_ReRiCrnr_x : 31|12@0+ (0.05,-100) [-100|100] "m"  GW
 SG_ ADAS_APASlot1_ReRiCrnr_y : 35|12@0+ (0.05,-100) [-100|100] "m"  GW
 SG_ ADAS_APASlot1_FrLeCrnr_x : 55|12@0+ (0.05,-100) [-100|100] "m"  GW

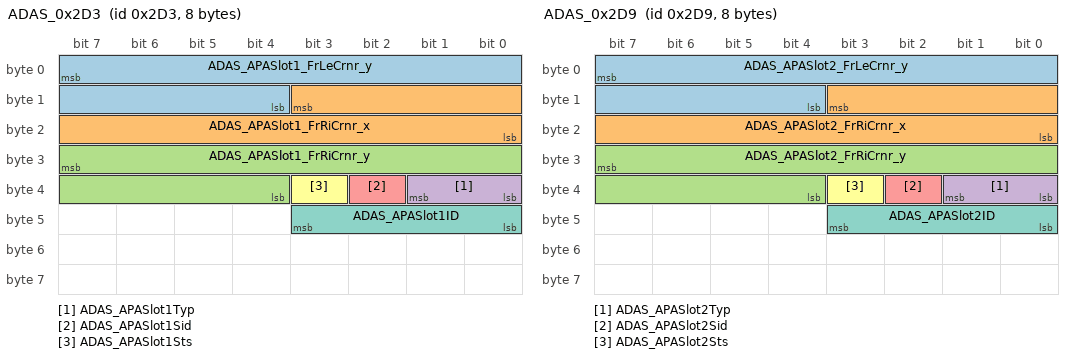
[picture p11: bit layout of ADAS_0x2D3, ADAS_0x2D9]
BO_ 723 ADAS_0x2D3: 8 ADAS
 SG_ ADAS_APASlot1_FrLeCrnr_y : 7|12@0+ (0.05,-100) [-100|100] "m"  GW
 SG_ ADAS_APASlot1_FrRiCrnr_x : 11|12@0+ (0.05,-100) [-100|100] "m"  GW
 SG_ ADAS_APASlot1_FrRiCrnr_y : 31|12@0+ (0.05,-100) [-100|100] "m"  GW
 SG_ ADAS_APASlot1Typ : 33|2@0+ (1,0) [0|3] ""  GW
 SG_ ADAS_APASlot1Sid : 34|1@0+ (1,0) [0|1] ""  GW
 SG_ ADAS_APASlot1Sts : 35|1@0+ (1,0) [0|1] ""  GW
 SG_ ADAS_APASlot1ID : 43|4@0+ (1,0) [0|15] ""  GW

BO_ 726 ADAS_0x2D6: 8 ADAS
 SG_ ADAS_APASlot2_ReLeCrnr_x : 7|12@0+ (0.05,-100) [-100|100] "m"  GW
 SG_ ADAS_APASlot2_ReLeCrnr_y : 11|12@0+ (0.05,-100) [-100|100] "m"  GW
 SG_ ADAS_APASlot2_ReRiCrnr_x : 31|12@0+ (0.05,-100) [-100|100] "m"  GW
 SG_ ADAS_APASlot2_ReRiCrnr_y : 35|12@0+ (0.05,-100) [-100|100] "m"  GW
 SG_ ADAS_APASlot2_FrLeCrnr_x : 55|12@0+ (0.05,-100) [-100|100] "m"  GW

BO_ 729 ADAS_0x2D9: 8 ADAS
 SG_ ADAS_APASlot2_FrLeCrnr_y : 7|12@0+ (0.05,-100) [-100|100] "m"  GW
 SG_ ADAS_APASlot2_FrRiCrnr_x : 11|12@0+ (0.05,-100) [-100|100] "m"  GW
 SG_ ADAS_APASlot2_FrRiCrnr_y : 31|12@0+ (0.05,-100) [-100|100] "m"  GW
 SG_ ADAS_APASlot2Typ : 33|2@0+ (1,0) [0|3] ""  GW
 SG_ ADAS_APASlot2Sid : 34|1@0+ (1,0) [0|1] ""  GW
 SG_ ADAS_APASlot2Sts : 35|1@0+ (1,0) [0|1] ""  GW
 SG_ ADAS_APASlot2ID : 43|4@0+ (1,0) [0|15] ""  GW

BO_ 732 ADAS_0x2DC: 8 ADAS
 SG_ ADAS_APASlot3_ReLeCrnr_x : 7|12@0+ (0.05,-100) [-100|100] "m"  GW
 SG_ ADAS_APASlot3_ReLeCrnr_y : 11|12@0+ (0.05,-100) [-100|100] "m"  GW
 SG_ ADAS_APASlot3_ReRiCrnr_x : 31|12@0+ (0.05,-100) [-100|100] "m"  GW
 SG_ ADAS_APASlot3_ReRiCrnr_y : 35|12@0+ (0.05,-100) [-100|100] "m"  GW
 SG_ ADAS_APASlot3_FrLeCrnr_x : 55|12@0+ (0.05,-100) [-100|100] "m"  GW

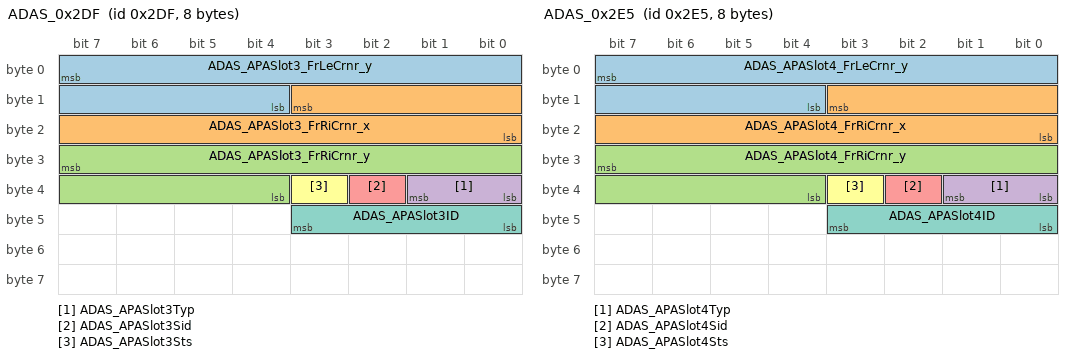
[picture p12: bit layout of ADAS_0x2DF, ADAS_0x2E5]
BO_ 735 ADAS_0x2DF: 8 ADAS
 SG_ ADAS_APASlot3_FrLeCrnr_y : 7|12@0+ (0.05,-100) [-100|100] "m"  GW
 SG_ ADAS_APASlot3_FrRiCrnr_x : 11|12@0+ (0.05,-100) [-100|100] "m"  GW
 SG_ ADAS_APASlot3_FrRiCrnr_y : 31|12@0+ (0.05,-100) [-100|100] "m"  GW
 SG_ ADAS_APASlot3Typ : 33|2@0+ (1,0) [0|3] ""  GW
 SG_ ADAS_APASlot3Sid : 34|1@0+ (1,0) [0|1] ""  GW
 SG_ ADAS_APASlot3Sts : 35|1@0+ (1,0) [0|1] ""  GW
 SG_ ADAS_APASlot3ID : 43|4@0+ (1,0) [0|15] ""  GW

BO_ 738 ADAS_0x2E2: 8 ADAS
 SG_ ADAS_APASlot4_ReLeCrnr_x : 7|12@0+ (0.05,-100) [-100|100] "m"  GW
 SG_ ADAS_APASlot4_ReLeCrnr_y : 11|12@0+ (0.05,-100) [-100|100] "m"  GW
 SG_ ADAS_APASlot4_ReRiCrnr_x : 31|12@0+ (0.05,-100) [-100|100] "m"  GW
 SG_ ADAS_APASlot4_ReRiCrnr_y : 35|12@0+ (0.05,-100) [-100|100] "m"  GW
 SG_ ADAS_APASlot4_FrLeCrnr_x : 55|12@0+ (0.05,-100) [-100|100] "m"  GW

BO_ 741 ADAS_0x2E5: 8 ADAS
 SG_ ADAS_APASlot4_FrLeCrnr_y : 7|12@0+ (0.05,-100) [-100|100] "m"  GW
 SG_ ADAS_APASlot4_FrRiCrnr_x : 11|12@0+ (0.05,-100) [-100|100] "m"  GW
 SG_ ADAS_APASlot4_FrRiCrnr_y : 31|12@0+ (0.05,-100) [-100|100] "m"  GW
 SG_ ADAS_APASlot4Typ : 33|2@0+ (1,0) [0|3] ""  GW
 SG_ ADAS_APASlot4Sid : 34|1@0+ (1,0) [0|1] ""  GW
 SG_ ADAS_APASlot4Sts : 35|1@0+ (1,0) [0|1] ""  GW
 SG_ ADAS_APASlot4ID : 43|4@0+ (1,0) [0|15] ""  GW

BO_ 744 ADAS_0x2E8: 8 ADAS
 SG_ ADAS_APASlot5_ReLeCrnr_x : 7|12@0+ (0.05,-100) [-100|100] "m"  GW
 SG_ ADAS_APASlot5_ReLeCrnr_y : 11|12@0+ (0.05,-100) [-100|100] "m"  GW
 SG_ ADAS_APASlot5_ReRiCrnr_x : 31|12@0+ (0.05,-100) [-100|100] "m"  GW
 SG_ ADAS_APASlot5_ReRiCrnr_y : 35|12@0+ (0.05,-100) [-100|100] "m"  GW
 SG_ ADAS_APASlot5_FrLeCrnr_x : 55|12@0+ (0.05,-100) [-100|100] "m"  GW

BO_ 745 ADAS_0x2E9: 8 ADAS
 SG_ ADAS_APASlot6_ReLeCrnr_x : 7|12@0+ (0.05,-100) [-100|100] "m"  GW
 SG_ ADAS_APASlot6_ReLeCrnr_y : 11|12@0+ (0.05,-100) [-100|100] "m"  GW
 SG_ ADAS_APASlot6_ReRiCrnr_x : 31|12@0+ (0.05,-100) [-100|100] "m"  GW
 SG_ ADAS_APASlot6_ReRiCrnr_y : 35|12@0+ (0.05,-100) [-100|100] "m"  GW
 SG_ ADAS_APASlot6_FrLeCrnr_x : 55|12@0+ (0.05,-100) [-100|100] "m"  GW

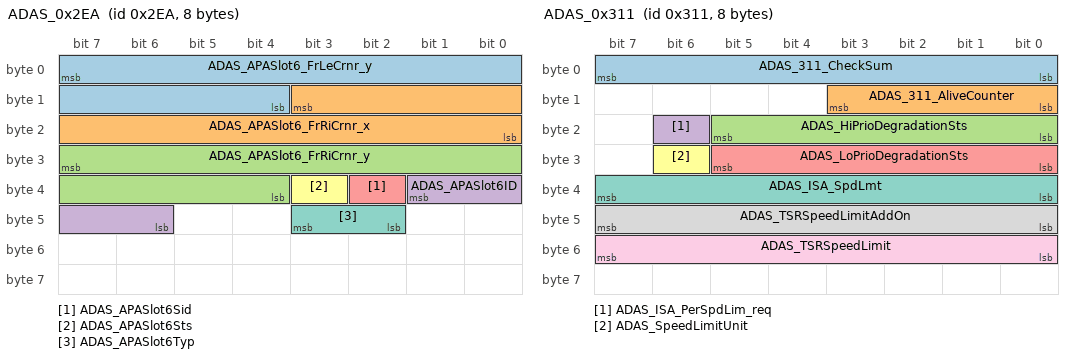
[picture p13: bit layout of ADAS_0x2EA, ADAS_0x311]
BO_ 746 ADAS_0x2EA: 8 ADAS
 SG_ ADAS_APASlot6_FrLeCrnr_y : 7|12@0+ (0.05,-100) [-100|100] "m"  GW
 SG_ ADAS_APASlot6_FrRiCrnr_x : 11|12@0+ (0.05,-100) [-100|100] "m"  GW
 SG_ ADAS_APASlot6_FrRiCrnr_y : 31|12@0+ (0.05,-100) [-100|100] "m"  GW
 SG_ ADAS_APASlot6ID : 33|4@0+ (1,0) [0|15] ""  GW
 SG_ ADAS_APASlot6Sid : 34|1@0+ (1,0) [0|1] ""  GW
 SG_ ADAS_APASlot6Sts : 35|1@0+ (1,0) [0|1] ""  GW
 SG_ ADAS_APASlot6Typ : 43|2@0+ (1,0) [0|3] ""  GW

BO_ 785 ADAS_0x311: 8 ADAS
 SG_ ADAS_311_CheckSum : 7|8@0+ (1,0) [0|255] ""  GW
 SG_ ADAS_311_AliveCounter : 11|4@0+ (1,0) [0|14] ""  GW
 SG_ ADAS_HiPrioDegradationSts : 21|6@0+ (1,0) [0|63] ""  GW
 SG_ ADAS_ISA_PerSpdLim_req : 22|1@0+ (1,0) [0|1] ""  GW
 SG_ ADAS_LoPrioDegradationSts : 29|6@0+ (1,0) [0|63] ""  GW
 SG_ ADAS_SpeedLimitUnit : 30|1@0+ (1,0) [0|1] ""  GW
 SG_ ADAS_ISA_SpdLmt : 39|8@0+ (1,0) [0|255] "kph"  GW
 SG_ ADAS_TSRSpeedLimitAddOn : 47|8@0+ (1,0) [0|255] ""  GW
 SG_ ADAS_TSRSpeedLimit : 55|8@0+ (1,0) [0|255] ""  GW

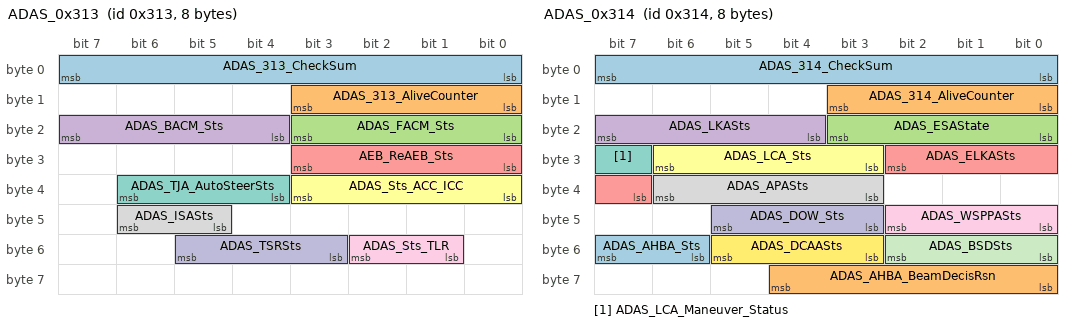
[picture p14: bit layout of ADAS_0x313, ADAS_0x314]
BO_ 787 ADAS_0x313: 8 ADAS
 SG_ ADAS_313_CheckSum : 7|8@0+ (1,0) [0|255] ""  FCM,GW
 SG_ ADAS_313_AliveCounter : 11|4@0+ (1,0) [0|14] ""  FCM,GW
 SG_ ADAS_FACM_Sts : 19|4@0+ (1,0) [0|15] ""  GW
 SG_ ADAS_BACM_Sts : 23|4@0+ (1,0) [0|15] ""  GW
 SG_ AEB_ReAEB_Sts : 27|4@0+ (1,0) [0|15] ""  GW
 SG_ ADAS_Sts_ACC_ICC : 35|4@0+ (1,0) [0|15] ""  FCM,GW
 SG_ ADAS_TJA_AutoSteerSts : 38|3@0+ (1,0) [0|7] ""  GW
 SG_ ADAS_ISASts : 46|2@0+ (1,0) [0|3] ""  GW
 SG_ ADAS_Sts_TLR : 50|2@0+ (1,0) [0|3] ""  GW
 SG_ ADAS_TSRSts : 53|3@0+ (1,0) [0|7] ""  GW

BO_ 788 ADAS_0x314: 8 ADAS
 SG_ ADAS_314_CheckSum : 7|8@0+ (1,0) [0|255] ""  FCM,GW
 SG_ ADAS_314_AliveCounter : 11|4@0+ (1,0) [0|14] ""  FCM,GW
 SG_ ADAS_ESAState : 19|4@0+ (1,0) [0|15] ""  GW
 SG_ ADAS_LKASts : 23|4@0+ (1,0) [0|15] ""  GW
 SG_ ADAS_ELKASts : 26|4@0+ (1,0) [0|7] ""  GW
 SG_ ADAS_LCA_Sts : 30|4@0+ (1,0) [0|15] ""  GW
 SG_ ADAS_LCA_Maneuver_Status : 31|1@0+ (1,0) [0|1] ""  GW
 SG_ ADAS_APASts : 38|4@0+ (1,0) [0|15] ""  GW
 SG_ ADAS_WSPPASts : 42|3@0+ (1,0) [0|7] ""  GW
 SG_ ADAS_DOW_Sts : 45|3@0+ (1,0) [0|7] ""  GW
 SG_ ADAS_BSDSts : 50|3@0+ (1,0) [0|7] ""  GW
 SG_ ADAS_DCAASts : 53|3@0+ (1,0) [0|7] ""  FCM,GW
 SG_ ADAS_AHBA_Sts : 55|2@0+ (1,0) [0|3] ""  GW
 SG_ ADAS_AHBA_BeamDecisRsn : 60|5@0+ (1,0) [0|15] ""  GW

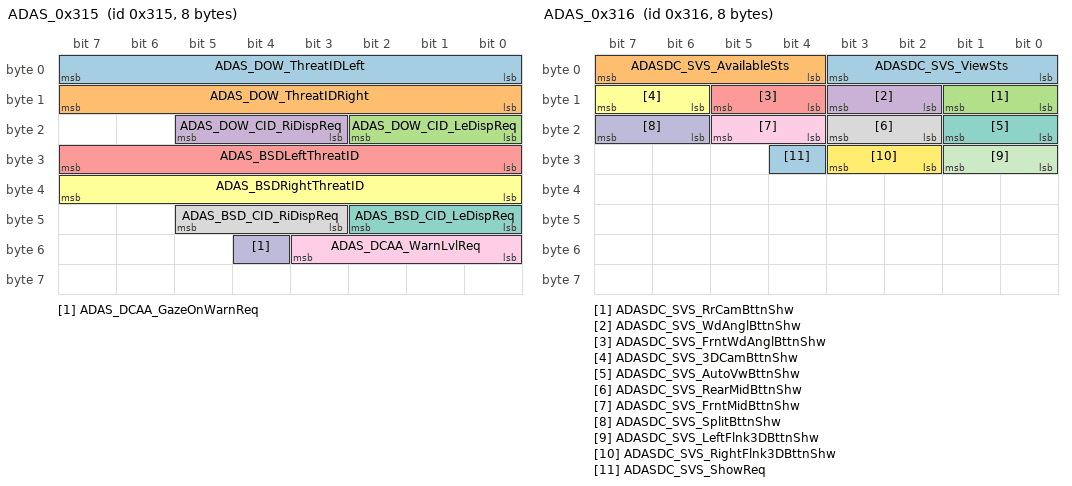
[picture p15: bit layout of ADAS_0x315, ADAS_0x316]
BO_ 789 ADAS_0x315: 8 ADAS
 SG_ ADAS_DOW_ThreatIDLeft : 7|8@0+ (1,0) [0|255] ""  GW
 SG_ ADAS_DOW_ThreatIDRight : 15|8@0+ (1,0) [0|255] ""  GW
 SG_ ADAS_DOW_CID_LeDispReq : 18|3@0+ (1,0) [0|7] ""  GW
 SG_ ADAS_DOW_CID_RiDispReq : 21|3@0+ (1,0) [0|7] ""  GW
 SG_ ADAS_BSDLeftThreatID : 31|8@0+ (1,0) [0|255] ""  GW
 SG_ ADAS_BSDRightThreatID : 39|8@0+ (1,0) [0|255] ""  GW
 SG_ ADAS_BSD_CID_LeDispReq : 42|3@0+ (1,0) [0|7] ""  GW
 SG_ ADAS_BSD_CID_RiDispReq : 45|3@0+ (1,0) [0|7] ""  GW
 SG_ ADAS_DCAA_WarnLvlReq : 51|4@0+ (1,0) [0|15] ""  GW
 SG_ ADAS_DCAA_GazeOnWarnReq : 52|1@0+ (1,0) [0|1] ""  GW

BO_ 790 ADAS_0x316: 8 ADAS
 SG_ ADASDC_SVS_ViewSts : 3|4@0+ (1,0) [0|15] ""  GW
 SG_ ADASDC_SVS_AvailableSts : 7|4@0+ (1,0) [0|15] ""  GW
 SG_ ADASDC_SVS_RrCamBttnShw : 9|2@0+ (1,0) [0|1] ""  GW
 SG_ ADASDC_SVS_WdAnglBttnShw : 11|2@0+ (1,0) [0|1] ""  GW
 SG_ ADASDC_SVS_FrntWdAnglBttnShw : 13|2@0+ (1,0) [0|1] ""  GW
 SG_ ADASDC_SVS_3DCamBttnShw : 15|2@0+ (1,0) [0|1] ""  GW
 SG_ ADASDC_SVS_AutoVwBttnShw : 17|2@0+ (1,0) [0|1] ""  GW
 SG_ ADASDC_SVS_RearMidBttnShw : 19|2@0+ (1,0) [0|1] ""  GW
 SG_ ADASDC_SVS_FrntMidBttnShw : 21|2@0+ (1,0) [0|1] ""  GW
 SG_ ADASDC_SVS_SplitBttnShw : 23|2@0+ (1,0) [0|1] ""  GW
 SG_ ADASDC_SVS_LeftFlnk3DBttnShw : 25|2@0+ (1,0) [0|1] ""  GW
 SG_ ADASDC_SVS_RightFlnk3DBttnShw : 27|2@0+ (1,0) [0|1] ""  GW
 SG_ ADASDC_SVS_ShowReq : 28|1@0+ (1,0) [0|1] ""  GW

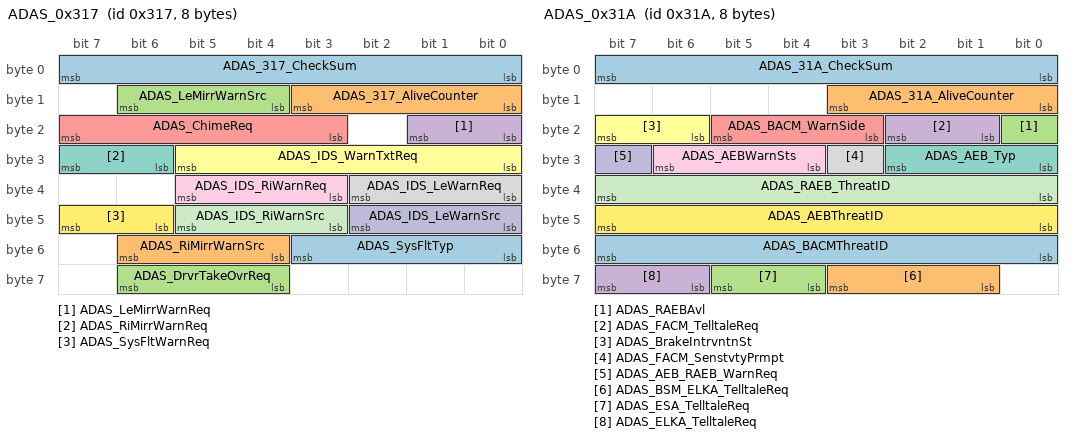
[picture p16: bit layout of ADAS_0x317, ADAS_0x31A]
BO_ 791 ADAS_0x317: 8 ADAS
 SG_ ADAS_317_CheckSum : 7|8@0+ (1,0) [0|255] ""  GW
 SG_ ADAS_317_AliveCounter : 11|4@0+ (1,0) [0|14] ""  GW
 SG_ ADAS_LeMirrWarnSrc : 14|3@0+ (1,0) [0|7] ""  GW
 SG_ ADAS_LeMirrWarnReq : 17|2@0+ (1,0) [0|3] ""  GW
 SG_ ADAS_ChimeReq : 23|5@0+ (1,0) [0|15] ""  GW
 SG_ ADAS_IDS_WarnTxtReq : 29|6@0+ (1,0) [0|63] ""  GW
 SG_ ADAS_RiMirrWarnReq : 31|2@0+ (1,0) [0|3] ""  GW
 SG_ ADAS_IDS_LeWarnReq : 34|3@0+ (1,0) [0|7] ""  GW
 SG_ ADAS_IDS_RiWarnReq : 37|3@0+ (1,0) [0|7] ""  GW
 SG_ ADAS_IDS_LeWarnSrc : 42|3@0+ (1,0) [0|7] ""  GW
 SG_ ADAS_IDS_RiWarnSrc : 45|3@0+ (1,0) [0|7] ""  GW
 SG_ ADAS_SysFltWarnReq : 47|2@0+ (1,0) [0|3] ""  GW
 SG_ ADAS_SysFltTyp : 51|4@0+ (1,0) [0|15] ""  GW
 SG_ ADAS_RiMirrWarnSrc : 54|3@0+ (1,0) [0|7] ""  GW
 SG_ ADAS_DrvrTakeOvrReq : 62|3@0+ (1,0) [0|7] ""  GW

BO_ 792 ESP_0x318: 8 GW
 SG_ ESP_318_CheckSum : 7|8@0+ (1,0) [0|255] ""  ADAS,FCM,PKC
 SG_ ESP_318_AliveCounter : 11|4@0+ (1,0) [0|14] ""  ADAS,FCM,PKC
 SG_ ESP_BrkPedlStsVld : 13|2@0+ (1,0) [0|3] ""  ADAS,FCM
 SG_ ESP_BrkPedlSts : 14|1@0+ (1,0) [0|1] ""  ADAS,FCM
 SG_ ESP_VehSpdVld : 17|2@0+ (1,0) [0|3] ""  ADAS,FCM,PKC
 SG_ ESP_SysActv : 20|1@0+ (1,0) [0|1] ""  ADAS
 SG_ ESP_LampSwtOffIndcn : 21|1@0+ (1,0) [0|1] ""  ADAS
 SG_ ESP_FltIndcn_EBD : 22|1@0+ (1,0) [0|1] ""  ADAS
 SG_ ESP_FltIndcn_ABS : 23|1@0+ (1,0) [0|1] ""  ADAS,FCM
 SG_ ESP_MilgRollgCntr_ODO : 31|16@0+ (1,0) [0|65535] "pulses"  ADAS
 SG_ ESP_VehSpd : 47|16@0+ (0.1,0) [0|300] "km/h"  ADAS,FCM,PKC
 SG_ ESP_IninModSigIndcn : 56|1@0+ (1,0) [0|1] ""  ADAS
 SG_ ESP_FltIndcn_TCS : 57|1@0+ (1,0) [0|1] ""  ADAS,FCM
 SG_ ESP_CtrlSts_HDC : 59|2@0+ (1,0) [0|3] ""  ADAS
 SG_ ESP_AvlIndcn_HDC : 60|1@0+ (1,0) [0|1] ""  ADAS
 SG_ ESP_NoBrkP : 61|1@0+ (1,0) [0|1] ""  ADAS
 SG_ ESP_RDAEnaFlg : 62|1@0+ (1,0) [0|1] ""  ADAS

BO_ 794 ADAS_0x31A: 8 ADAS
 SG_ ADAS_31A_CheckSum : 7|8@0+ (1,0) [0|255] ""  GW
 SG_ ADAS_31A_AliveCounter : 11|4@0+ (1,0) [0|14] ""  GW
 SG_ ADAS_RAEBAvl : 16|1@0+ (1,0) [0|1] ""  GW
 SG_ ADAS_FACM_TelltaleReq : 18|2@0+ (1,0) [0|3] ""  GW
 SG_ ADAS_BACM_WarnSide : 21|3@0+ (1,0) [0|7] ""  GW
 SG_ ADAS_BrakeIntrvntnSt : 23|2@0+ (1,0) [0|3] ""  GW
 SG_ ADAS_AEB_Typ : 26|3@0+ (1,0) [0|7] ""  GW
 SG_ ADAS_FACM_SenstvtyPrmpt : 27|1@0+ (1,0) [0|1] ""  GW
 SG_ ADAS_AEBWarnSts : 30|3@0+ (1,0) [0|7] ""  GW
 SG_ ADAS_AEB_RAEB_WarnReq : 31|1@0+ (1,0) [0|1] ""  GW
 SG_ ADAS_RAEB_ThreatID : 39|8@0+ (1,0) [0|255] ""  GW
 SG_ ADAS_AEBThreatID : 47|8@0+ (1,0) [0|255] ""  GW
 SG_ ADAS_BACMThreatID : 55|8@0+ (1,0) [0|255] ""  GW
 SG_ ADAS_BSM_ELKA_TelltaleReq : 59|3@0+ (1,0) [0|4] ""  GW
 SG_ ADAS_ESA_TelltaleReq : 61|2@0+ (1,0) [0|3] ""  GW
 SG_ ADAS_ELKA_TelltaleReq : 63|2@0+ (1,0) [0|3] ""  GW

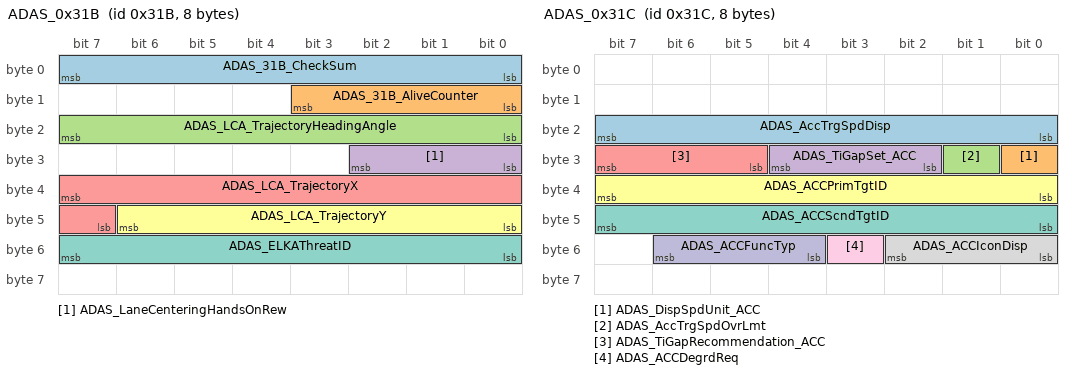
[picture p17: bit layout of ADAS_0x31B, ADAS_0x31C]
BO_ 795 ADAS_0x31B: 8 ADAS
 SG_ ADAS_31B_CheckSum : 7|8@0+ (1,0) [0|255] ""  GW
 SG_ ADAS_31B_AliveCounter : 11|4@0+ (1,0) [0|14] ""  GW
 SG_ ADAS_LCA_TrajectoryHeadingAngle : 23|8@0+ (1,-127) [-127|128] ""  GW
 SG_ ADAS_LaneCenteringHandsOnRew : 26|3@0+ (1,0) [0|7] ""  GW
 SG_ ADAS_LCA_TrajectoryX : 39|9@0+ (1,0) [0|511] ""  GW
 SG_ ADAS_LCA_TrajectoryY : 46|7@0+ (0.25,-63) [-63|-31.25] ""  GW
 SG_ ADAS_ELKAThreatID : 55|8@0+ (1,0) [0|255] ""  GW

BO_ 796 ADAS_0x31C: 8 ADAS
 SG_ ADAS_AccTrgSpdDisp : 23|8@0+ (1,0) [0|255] ""  GW
 SG_ ADAS_DispSpdUnit_ACC : 24|1@0+ (1,0) [0|1] ""  GW
 SG_ ADAS_AccTrgSpdOvrLmt : 25|1@0+ (1,0) [0|1] ""  GW
 SG_ ADAS_TiGapSet_ACC : 28|3@0+ (1,0) [0|7] ""  GW
 SG_ ADAS_TiGapRecommendation_ACC : 31|3@0+ (1,0) [0|7] ""  GW
 SG_ ADAS_ACCPrimTgtID : 39|8@0+ (1,0) [0|255] ""  GW
 SG_ ADAS_ACCScndTgtID : 47|8@0+ (1,0) [0|255] ""  GW
 SG_ ADAS_ACCIconDisp : 50|3@0+ (1,0) [0|7] ""  GW
 SG_ ADAS_ACCDegrdReq : 51|1@0+ (1,0) [0|1] ""  GW
 SG_ ADAS_ACCFuncTyp : 54|3@0+ (1,0) [0|7] ""  GW

BO_ 801 BCM_0x321: 8 GW
 SG_ BCM_AP_FL_LeFrntWinPosnInfo : 23|8@0+ (0.5,0) [0|100] "%"  FCM,PKC
 SG_ BCM_AP_FL_RiFrntWinPosnInfo : 31|8@0+ (0.5,0) [0|100] "%"  FCM,PKC
 SG_ BCM_AP_FL_LeReWinPosnInfo : 39|8@0+ (0.5,0) [0|100] "%"  FCM,PKC
 SG_ BCM_AP_FL_RiReWinPosnInfo : 47|8@0+ (0.5,0) [0|100] "%"  FCM,PKC
 SG_ BCM_ValueLightFrnt_RLS : 55|8@0+ (50,0) [0|12700] "w/m2"  FCM
 SG_ BCM_LightReqReason_RLS : 60|5@0+ (1,0) [0|31] ""  ADASBUS_Virtual_ECU

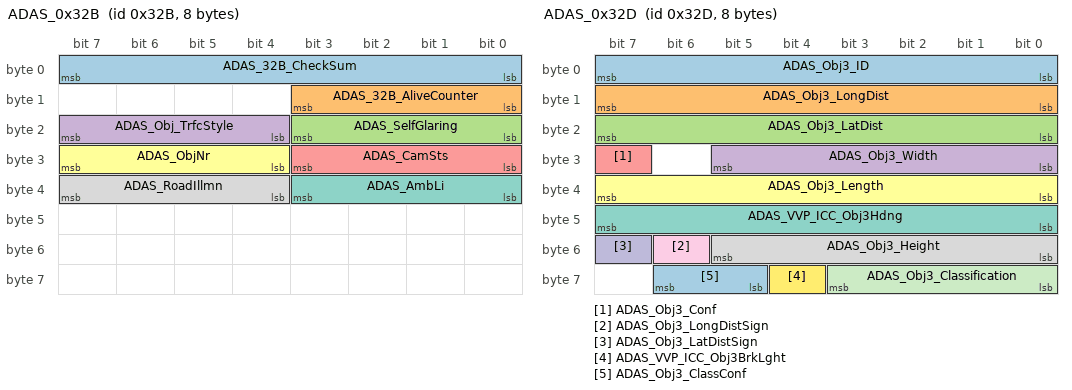
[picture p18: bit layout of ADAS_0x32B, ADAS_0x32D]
BO_ 811 ADAS_0x32B: 8 ADAS
 SG_ ADAS_32B_CheckSum : 7|8@0+ (1,0) [0|255] ""  GW
 SG_ ADAS_32B_AliveCounter : 11|4@0+ (1,0) [0|14] ""  GW
 SG_ ADAS_SelfGlaring : 19|4@0+ (1,0) [0|15] ""  GW
 SG_ ADAS_Obj_TrfcStyle : 23|4@0+ (1,0) [0|15] ""  GW
 SG_ ADAS_CamSts : 27|4@0+ (1,0) [0|15] ""  GW
 SG_ ADAS_ObjNr : 31|4@0+ (1,0) [0|15] ""  GW
 SG_ ADAS_AmbLi : 35|4@0+ (1,0) [0|15] ""  GW
 SG_ ADAS_RoadIllmn : 39|4@0+ (1,0) [0|15] ""  GW

BO_ 813 ADAS_0x32D: 8 ADAS
 SG_ ADAS_Obj3_ID : 7|8@0+ (1,0) [0|255] ""  GW
 SG_ ADAS_Obj3_LongDist : 15|8@0+ (0.2,0) [0|51] "m"  GW
 SG_ ADAS_Obj3_LatDist : 23|8@0+ (0.2,0) [0|51] "m"  GW
 SG_ ADAS_Obj3_Width : 29|6@0+ (0.1,0) [0|6.3] "m"  GW
 SG_ ADAS_Obj3_Conf : 31|1@0+ (1,0) [0|1] ""  GW
 SG_ ADAS_Obj3_Length : 39|8@0+ (0.2,0) [0|50] "m"  GW
 SG_ ADAS_VVP_ICC_Obj3Hdng : 47|8@0+ (1.5,0) [0|360] "deg"  GW
 SG_ ADAS_Obj3_Height : 53|6@0+ (0.1,0) [0|6.3] "m"  GW
 SG_ ADAS_Obj3_LongDistSign : 54|1@0+ (1,0) [0|1] ""  GW
 SG_ ADAS_Obj3_LatDistSign : 55|1@0+ (1,0) [0|1] ""  GW
 SG_ ADAS_Obj3_Classification : 59|4@0+ (1,0) [0|15] ""  GW
 SG_ ADAS_VVP_ICC_Obj3BrkLght : 60|1@0+ (1,0) [0|1] ""  GW
 SG_ ADAS_Obj3_ClassConf : 62|2@0+ (1,0) [0|3] ""  GW

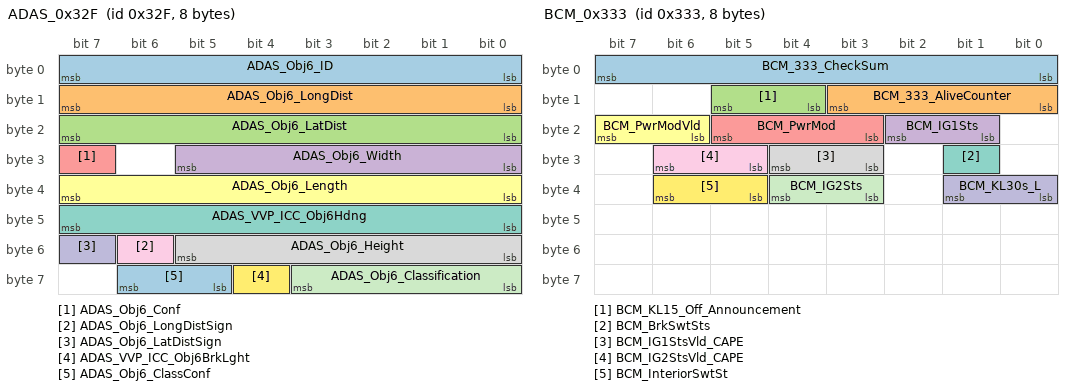
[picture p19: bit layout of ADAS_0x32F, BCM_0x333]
BO_ 815 ADAS_0x32F: 8 ADAS
 SG_ ADAS_Obj6_ID : 7|8@0+ (1,0) [0|255] ""  GW
 SG_ ADAS_Obj6_LongDist : 15|8@0+ (0.2,0) [0|51] "m"  GW
 SG_ ADAS_Obj6_LatDist : 23|8@0+ (0.2,0) [0|51] "m"  GW
 SG_ ADAS_Obj6_Width : 29|6@0+ (0.1,0) [0|6.3] "m"  GW
 SG_ ADAS_Obj6_Conf : 31|1@0+ (1,0) [0|1] ""  GW
 SG_ ADAS_Obj6_Length : 39|8@0+ (0.2,0) [0|50] "m"  GW
 SG_ ADAS_VVP_ICC_Obj6Hdng : 47|8@0+ (1.5,0) [0|360] "deg"  GW
 SG_ ADAS_Obj6_Height : 53|6@0+ (0.1,0) [0|6.3] "m"  GW
 SG_ ADAS_Obj6_LongDistSign : 54|1@0+ (1,0) [0|1] ""  GW
 SG_ ADAS_Obj6_LatDistSign : 55|1@0+ (1,0) [0|1] ""  GW
 SG_ ADAS_Obj6_Classification : 59|4@0+ (1,0) [0|15] ""  GW
 SG_ ADAS_VVP_ICC_Obj6BrkLght : 60|1@0+ (1,0) [0|1] ""  GW
 SG_ ADAS_Obj6_ClassConf : 62|2@0+ (1,0) [0|3] ""  GW

BO_ 819 BCM_0x333: 8 GW
 SG_ BCM_333_CheckSum : 7|8@0+ (1,0) [0|255] ""  ADAS,FCM,PKC
 SG_ BCM_333_AliveCounter : 11|4@0+ (1,0) [0|14] ""  ADAS,FCM,PKC
 SG_ BCM_KL15_Off_Announcement : 13|2@0+ (1,0) [0|3] ""  ADAS
 SG_ BCM_IG1Sts : 18|2@0+ (1,0) [0|3] ""  ADAS,FCM
 SG_ BCM_PwrMod : 21|3@0+ (1,0) [0|7] ""  ADAS,FCM,PKC
 SG_ BCM_PwrModVld : 23|2@0+ (1,0) [0|3] ""  ADAS,FCM,PKC
 SG_ BCM_BrkSwtSts : 25|1@0+ (1,0) [0|1] ""  ADAS
 SG_ BCM_IG1StsVld_CAPE : 28|2@0+ (1,0) [0|3] ""  ADAS
 SG_ BCM_IG2StsVld_CAPE : 30|2@0+ (1,0) [0|3] ""  ADAS
 SG_ BCM_KL30s_L : 33|2@0+ (1,0) [0|3] ""  ADASBUS_Virtual_ECU
 SG_ BCM_IG2Sts : 36|2@0+ (1,0) [0|3] ""  ADAS
 SG_ BCM_InteriorSwtSt : 38|2@0+ (1,0) [0|3] ""  ADASBUS_Virtual_ECU

BA_DEF_  "NmAsrWaitBusSleepTime" INT 0 65535;
BA_DEF_  "NmAsrTimeoutTime" INT 0 65535;
BA_DEF_  "NmAsrRepeatMessageTime" INT 0 65535;
BA_DEF_  "E2EP01ProfileName" STRING ;
BA_DEF_  "NmAsrMessageCount" INT 1 256;
BA_DEF_  "E2EP01ProfileBehavior" ENUM  "PRE_R4_2","R4_2";
BA_DEF_ BU_  "NmAsrCanMsgReducedTime" INT 320 640;
BA_DEF_  "NmAsrBaseAddress" HEX 0 2047;
BA_DEF_  "NmAsrCanMsgCycleTime" INT 0 0;
BA_DEF_  "BusBaudateData" INT 0 10000;
BA_DEF_  "E2EP01DataIdMode" ENUM  "all16Bit","alternating8Bit","lower8Bit","lower12Bit";
BA_DEF_ BO_  "GenMsgSendType" ENUM  "Cyclic","NotUsed","NotUsed","NotUsed","NotUsed","NotUsed","NotUsed","IfActive","NoMsgSendType";
BA_DEF_  "BusBaudateOther" INT 0 10000;
BA_DEF_ BO_  "GenMsgCycleTime" INT 0 0;
BA_DEF_ SG_  "GenSigSendType" ENUM  "Cyclic","OnWrite","OnWriteWithRepetition","OnChange","OnChangeWithRepetition","IfActive","IfActiveWithRepetition","NoSigSendType";
BA_DEF_  "BusBaudrate" INT 0 10000;
BA_DEF_ BU_  "NodeLayerModules" STRING ;
BA_DEF_ BU_  "ILUsed" ENUM  "No","Yes";
BA_DEF_  "NmType" STRING ;
BA_DEF_  "NmBaseAddress" HEX 1024 2047;
BA_DEF_  "NmMessageCount" INT 0 255;
BA_DEF_ BO_  "CANFD_BRS" ENUM  "0","1";
BA_DEF_ BO_  "VFrameFormat" ENUM  "StandardCAN","ExtendedCAN","reserved","reserved","reserved","reserved","reserved","reserved","reserved","reserved","reserved","reserved","reserved","reserved","StandardCAN_FD","ExtendedCAN_FD";
BA_DEF_ BO_  "GenMsgILSupport" ENUM  "No","Yes";
BA_DEF_  "BusType" STRING ;
BA_DEF_DEF_  "NmAsrWaitBusSleepTime" 1500;
BA_DEF_DEF_  "NmAsrTimeoutTime" 2000;
BA_DEF_DEF_  "NmAsrRepeatMessageTime" 3200;
BA_DEF_DEF_  "E2EP01ProfileName" "PROFILE_01";
BA_DEF_DEF_  "NmAsrMessageCount" 128;
BA_DEF_DEF_  "E2EP01ProfileBehavior" "R4_2";
BA_DEF_DEF_  "NmAsrCanMsgReducedTime" 320;
BA_DEF_DEF_  "NmAsrBaseAddress" 1024;
BA_DEF_DEF_  "NmAsrCanMsgCycleTime" 640;
BA_DEF_DEF_  "BusBaudateData" 2;
BA_DEF_DEF_  "E2EP01DataIdMode" "lower8Bit";
BA_DEF_DEF_  "GenMsgSendType" "Cyclic";
BA_DEF_DEF_  "BusBaudateOther" 500;
BA_DEF_DEF_  "GenMsgCycleTime" 0;
BA_DEF_DEF_  "GenSigSendType" "Cyclic";
BA_DEF_DEF_  "BusBaudrate" 500;
BA_DEF_DEF_  "NodeLayerModules" "CANoeILNLVector.dll";
BA_DEF_DEF_  "ILUsed" "Yes";
BA_DEF_DEF_  "NmType" "NmAsr";
BA_DEF_DEF_  "NmBaseAddress" 1024;
BA_DEF_DEF_  "NmMessageCount" 128;
BA_DEF_DEF_  "CANFD_BRS" "1";
BA_DEF_DEF_  "VFrameFormat" "StandardCAN";
BA_DEF_DEF_  "GenMsgILSupport" "Yes";
BA_DEF_DEF_  "BusType" "CAN";

CM_ BO_ 787 "Messages for ICC (IBUS 2) and Event Data Recorder (Chassis Bus)";
CM_ BO_ 788 "Messages for ICC (IBUS 2) and Event Data Recorder (Chassis Bus)";
CM_ SG_ 32 Syn_TripCntrVal_Byte0_All "Trip Counter Value";
CM_ SG_ 32 Syn_TripCntrVal_Byte1_All "Trip Counter Value";
CM_ SG_ 32 Syn_RstCntrVal_Byte0_All "Reset Counter Value";
CM_ SG_ 32 Syn_RstCntrVal_Byte1_All "Reset Counter Value";
CM_ SG_ 32 Syn_RstCntrVal_Byte2_All "Reset Counter Value";
CM_ SG_ 32 Syn_MACInfo_Byte0_All "Synchronization message Mac Info";
CM_ SG_ 32 Syn_MACInfo_Byte1_All "Synchronization message Mac Info";
CM_ SG_ 32 Syn_MACInfo_Byte2_All "Synchronization message Mac Info";
CM_ SG_ 258 VCU_102_CheckSum "VCU_102_message checksum ( E2E data ID: 0xBE )";
CM_ SG_ 258 VCU_102_AliveCounter "VCU_102 _Message counterVCU_102_AliveCounter";
CM_ SG_ 258 VCU_DrvrFrntMotTqReqVld "Effective position of driver's torque request for front drive motor (wheel end torque)";
CM_ SG_ 258 VCU_DrvrReMotTqReqVld "Effective position of the driver's torque request for the rear drive motor (wheel end torque)";
CM_ SG_ 258 VCU_DrvrFrntMotTqReq "Driver torque request for front drive motor (wheel end torque)";
CM_ SG_ 258 VCU_DrvrReMotTqReq "Driver torque request for rear drive motor (wheel end torque)";
CM_ SG_ 258 VCU_CoastTqReq "Coasting torque request";
CM_ SG_ 258 VCU_CoastTqReqVld "Coasting torque request validity";
CM_ SG_ 274 YRS_112_CheckSum "YRS_112_Message Checksum (E2E data ID: 0xA1)";
CM_ SG_ 274 YRS_112_AliveCounter "YRS_112_ AliveCounter";
CM_ SG_ 274 YRS_YawRateCalSts "Yaw rate sensor calibration state Indicates Yaw Rate Sensor Calibration State.";
CM_ SG_ 274 YRS_YawRateSnsrSts "Status of yaw rate sensor Indicates Yaw Rate Sensor State.";
CM_ SG_ 274 YRS_LatSnsrSts "Status of lateral sensor Indicates Lateral Sensor State.";
CM_ SG_ 274 YRS_LatAcce "Lateral acceleration (left positive, right negative, Real Value = raw value-offset)Indicates Lateral Acceleration.";
CM_ SG_ 274 YRS_YawRate "Indicates the yaw rate (counterclockwise positive, clockwise negative, Real Value = raw value-offset)Indicates Yaw Rate.";
CM_ SG_ 275 YRS_113_CheckSum "YRS_113_Message Checksum (E2E data ID: 0xB8)";
CM_ SG_ 275 YRS_113_AliveCounter "YRS_113_AliveCounter";
CM_ SG_ 275 YRS_LgtSnsrSts "Status of lateral sensorIndicates Lateral Sensor State.";
CM_ SG_ 275 YRS_LgtAcce "Longitudinal acceleration (Forward positive, Backward negative, Real Value = raw value-offset)Indicates Longitudinal Acceleration";
CM_ SG_ 276 ESP_114_CheckSum "ESP_114_Message checksum (E2E data ID: 0x72)";
CM_ SG_ 276 ESP_114_AliveCounter "EP_114 _Message counter";
CM_ SG_ 276 ESP_OTARdy_Fb "ESP OTA ready status feedback";
CM_ SG_ 276 ESP_FltIndcn_DTC "ESP/TCS fault indication Signal indicates failure monitoring of ESP function. Not used for ABS";
CM_ SG_ 276 ESP_ActvSig_VDC "ESP activation signal VDC operating When ESP is active shall the system send out a bus signal. Not used for ABS.";
CM_ SG_ 276 ESP_ActvSig_TCS "TCS activation signal TCS operating(including DTC operating)When TCS is active shall the system send out a bus signal. Not used for ABS.";
CM_ SG_ 276 ESP_ActvSig_EBD "EBD activation signal indicating EBD in active control or not.";
CM_ SG_ 276 ESP_ActvSig_DTC "DTC activation signal indicate DTC in active control or not.";
CM_ SG_ 276 ESP_WarningOn "ESP brake fault turning on request With this signal ESP requests the warning in the dashboard.";
CM_ SG_ 276 ESP_Actvndcn_CDD "CDD operation indication indicating CDD is working or not.";
CM_ SG_ 276 ESP_FltIndcn_CDD "CDD fault indication indicating CDD is available or not.";
CM_ SG_ 276 ESP_ActvIndcn_ABA "ABA working indication ABA is active.";
CM_ SG_ 276 ESP_FltIndcn_ABA "ABA fault indication the ABA function is available.";
CM_ SG_ 276 ESP_ActvIndcn_ABP "ABP operation indication Prefill (ABP) is active.";
CM_ SG_ 276 ESP_FltIndcn_ABP "ABP fault indication Prefill (ABP) is available.";
CM_ SG_ 276 ESP_ActvIndcn_AEB "AEB operation indication ESP is excuting AEB braking function.";
CM_ SG_ 276 ESP_FltIndcn_AEB "AEB fault indication AEB is available.";
CM_ SG_ 276 ESP_ActvIndcn_AWB "AWB operation indication AWB is active(brake jerk).";
CM_ SG_ 276 ESP_FltIndcn_AWB "AWB fault indication AWB is available. Feedback of AWB activation for ACC.";
CM_ SG_ 276 ESP_VehStandstillIndcn "Vehicle stop indication indicating whether the vehicle is standstill or not; must not be set until standstill is surely reached.";
CM_ SG_ 276 ESP_BrkOverTIndcn "Brake disc high temperature indication , set 1 to exit ACC function indicating brake temperature too high or not.";
CM_ SG_ 276 ESP_FltIndcn_VDC "ESP/TCS fault indication Signal indicates failure monitoring of ESP function. Not used for ABS";
CM_ SG_ 276 ESP_ActvIndcn_CDD_AP "ECS Active indication_CDD_APWhen VLC AP is active shall the system send out a bus signal.";
CM_ SG_ 276 ESP_FltIndcn_CDD_AP "Signal from ESC indicates whether CDD_AP is activated When VLC AP is active shall the system send out a bus signal.";
CM_ SG_ 277 ESP_115_CheckSum "ESP_115_Message checksum (E2E data ID: 0x8A)";
CM_ SG_ 277 ESP_115_AliveCounter "EP_115 _Message counter";
CM_ SG_ 277 ESP_WhlSpd_RF "Right front wheel speed Wheel speed of the front right wheel.";
CM_ SG_ 277 ESP_WhlSpdVld_RF "Effective right front wheel speed Validty of signal 'WHEEL_SPEED_FRONT_RIGHT_ACC '";
CM_ SG_ 277 ESP_WhlMovgDir_RF "Front right wheel movement direction (positive forward and negative backward)Front Right wheel Moving direction.";
CM_ SG_ 277 ESP_WhlMovgDir_LF "Front left wheel movement direction (positive forward and negative backward)Front left wheel Moving direction.";
CM_ SG_ 277 ESP_WhlSpd_LF "Left front wheel speed Wheel speed of the front left wheel.";
CM_ SG_ 277 ESP_WhlSpdVld_LF "Effective position of left front wheel speed Validty of signal 'WHEEL_SPEED_FRONT_LEFT_ACC'";
CM_ SG_ 278 ESP_116_CheckSum "ESP_116_Message checksum (E2E data ID: 0x9F)";
CM_ SG_ 278 ESP_116_AliveCounter "EP_116 _Message counter";
CM_ SG_ 278 ESP_WhlSpd_RR "Right rear wheel speed Wheel speed of the rear right wheel.";
CM_ SG_ 278 ESP_WhlSpdVld_RR "Right rear wheel speed effective position Validty of signal 'WHEEL_SPEED_REAR_RIGHT_ACC'.";
CM_ SG_ 278 ESP_WhlMovgDir_RR "Movement direction of right rear wheel (positive forward and negative backward)Rear Right wheel Moving direction.";
CM_ SG_ 278 ESP_WhlMovgDir_RL "Movement direction of left rear wheel (positive forward and negative backward)Rear left wheel Moving direction.";
CM_ SG_ 278 ESP_WhlSpd_RL "Left rear wheel speed Wheel speed of the rear left wheel.";
CM_ SG_ 278 ESP_WhlSpdVld_RL "Effective left rear wheel speed Validty of signal 'WHEEL_SPEED_REAR_LEFT_ACC'.";
CM_ SG_ 279 ADAS_117_CheckSum "ADAS_117_CheckSum (0x48)";
CM_ SG_ 279 ADAS_117_AliveCounter "ADAS_117_AliveCounter";
CM_ SG_ 279 ADAS_OTARdy_Fb "ADAS OTA ready status feedback";
CM_ SG_ 279 ADAS_LgtCtrl_Sts "Longitudinal controler status";
CM_ SG_ 279 ADAS_LgtCtrl_StsVld "Longitudinal controller validity (for initialization)";
CM_ SG_ 279 ADAS_LgtCtrl_DrvrOvrdSts "Longitudinal controler driver override status";
CM_ SG_ 279 ADAS_LgtCtrl_DrvrOvrdVld "Longitudinal controler driver roverride validity.";
CM_ SG_ 279 ADAS_HAP_EmgyStandstillVld "ADAS Highly Automated Parking Emergency Standstill request validity";
CM_ SG_ 279 ADAS_HAP_EmgyEPBVld "ADAS Highly Automated Parking Emergency EPB request validity";
CM_ SG_ 279 ADAS_HAP_EmgyStandstillReq "ADAS Highly Automated Parking Emergency Standstill request";
CM_ SG_ 279 ADAS_ParkStandstillReq "Longitudinal controler Standstill request";
CM_ SG_ 279 ADAS_ParkStandstillVld "Longitudinal controler Standstill request validity";
CM_ SG_ 279 ADAS_ParkGearReq "Park gear request";
CM_ SG_ 279 ADAS_ParkGearReqVld "Park gear request validity";
CM_ SG_ 279 ADAS_LgtCtrl_Typ "Longitudinal controler type of request";
CM_ SG_ 279 ADAS_HAP_EmgyEPBReq "ADAS Highly Automated Parking Emergency EPB request";
CM_ SG_ 279 ADAS_ISA_CutOffReq "ISA cutoff request ";
CM_ SG_ 279 ADAS_ISA_SpdLmt_VCU "ISA detected speed limit + user selected offset. Signal used for VCU";
CM_ SG_ 280 ADAS_118_CheckSum "ADAS_118_CheckSum (0x51)";
CM_ SG_ 280 ADAS_118_AliveCounter "ADAS_118_AliveCounter";
CM_ SG_ 280 ADAS_LgtCtrl_ESP_Sts "Longitudinal controler ADAS-ESP status";
CM_ SG_ 280 ADAS_LgtCtrl_ESP_Vld "Longitudinal controler ADAS-ESP validity";
CM_ SG_ 280 ADAS_ESP_DrvrOvrdSts "Driver override status to ESP?";
CM_ SG_ 280 ADAS_ESP_DrvrOvrdVld "Driver override validity to ESP";
CM_ SG_ 280 ADAS_HBAReq "Hydraulic Brake Assist (HBA) request";
CM_ SG_ 280 ADAS_HBAVld "Hydraulic brake assist (HBA) validity";
CM_ SG_ 280 ADAS_ESP_StandstillReq "Standstill request to ESP";
CM_ SG_ 280 ADAS_ESP_StandstillVld "Standstill request to ESP validity";
CM_ SG_ 280 ADAS_JerkReq "AEB jerk request";
CM_ SG_ 280 ADAS_JerkReqVld "Jerk validity. Do not use, keep as reserved";
CM_ SG_ 280 ADAS_BrkPrefillReq "Brake prefill request";
CM_ SG_ 280 ADAS_BrkPrefillVld "Brake prefill request validity";
CM_ SG_ 280 ADAS_AEB_ActvTyp "AEB type of request";
CM_ SG_ 280 ADAS_AEB_DecelVld "AEB deceleration request valid";
CM_ SG_ 280 ADAS_AEB_DecelReq "AEB deceleration request value";
CM_ SG_ 288 ESP_120_CheckSum "ESP_120_Message checksum (E2E data ID: 0xB1)";
CM_ SG_ 288 ESP_120_AliveCounter "EP_120_Message CounterESP_120_AliveCounter";
CM_ SG_ 288 ESP_ActvSig_ABS "ABS activation signal ABS operating When ABS is active shall the system send out a bus signal.";
CM_ SG_ 288 ESP_MstCylP "Master cylinder pressure (Real value = raw value-offset)Current pressure of the master cylinder pressure sensor in the ESP. Raw value without offset compensation.";
CM_ SG_ 288 ESP_MstCylPOffs "Master cylinder pressure offset Master cylinder pressure offset.(Real value = raw value ï¿½C offset)";
CM_ SG_ 288 ESP_MstCylPVld "Effective pressure of master cylinder Information about signal quality of pMC1.";
CM_ SG_ 288 ESP_MstCylPOffsVld "Effective position of master cylinder pressure offset Valid Information of the signal.";
CM_ SG_ 288 ESP_TotBrkTqReq "(Total driver braking torque requirement)This signal with driver general brake torque request.";
CM_ SG_ 289 ADAS_121_CheckSum "ADAS_121_CheckSum (0x17)Calculate from byte1~3";
CM_ SG_ 289 ADAS_121_AliveCounter "ADAS_121_AliveCounter";
CM_ SG_ 289 ADAS_LgtCtrl_AccelVld "Longitudinal controler acceleration request valid";
CM_ SG_ 289 ADAS_LgtCtrl_AccelReq "Longitudinal acceleration request value (Positive value acceleration, negative value deceleration) ";
CM_ SG_ 289 ADAS_121_SSecOC_Fresh_Byte0 "Short SecOC Fresh signal byte 0 on CAN";
CM_ SG_ 289 ADAS_121_SSecOC_MAC_Byte0 "Short SecOC MAC signal byte 0 on CAN";
CM_ SG_ 289 ADAS_121_SSecOC_MAC_Byte1 "Short SecOC MAC signal byte 1 on CAN";
CM_ SG_ 289 ADAS_121_SSecOC_MAC_Byte2 "Short SecOC MAC signal byte 2 on CAN";
CM_ SG_ 336 MCU_F_150_CheckSum "Front MCU_150_Message checksum(E2E data ID: 0x29)";
CM_ SG_ 336 MCU_F_150_AliveCounter "MCU_150_Message Counter FrontMCU_F_150_AliveCounter";
CM_ SG_ 336 MCU_F_CrtTqVld "Effective torque of front drive motorMotorFTorquevalidflag";
CM_ SG_ 336 MCU_F_CrtRotDir "Current rotation direction of front drive motorMotorFRotingdirection";
CM_ SG_ 336 MCU_F_CrtSpd "Current speed of front drive motorMotorFSpeed";
CM_ SG_ 336 MCU_F_CrtTq "Current torque of front drive motorMotorFTorque";
CM_ SG_ 336 MCU_F_CrtSpdSigVld "Effective position of front drive motor current speed signalMotorFSpeedsignalvalidflag";
CM_ SG_ 336 MCU_F_CrtMod "Current operating mode of front drive motorMotorFworkingmode";
CM_ SG_ 336 MCU_F_HVActvDchaSts "High-voltage active discharge state of front MCUHVActiveDischargeState";
CM_ SG_ 336 MCU_F_SlipCtrlActMode "the Anti-Slip Control (ASC or ASR on german) state";
CM_ SG_ 336 MCU_F_AlrmLamp_FS "Warning lamp_front drive motor (functional safety)";
CM_ SG_ 336 MCU_F_HVChkEndFlg "High voltage detection completion flag of front MCUMCUFHVCheckStates";
CM_ SG_ 337 MCU_R_151_CheckSum "Rear MCU_151_Message checksum (E2E data ID: 0x34)";
CM_ SG_ 337 MCU_R_151_AliveCounter "Rear MCU_151_Message counterMCU_R_151_AliveCounter";
CM_ SG_ 337 MCU_R_CrtTqVld "Effective torque of rear drive motorMotorRTorquevalidflag";
CM_ SG_ 337 MCU_R_CrtRotDir "Current rotation direction of rear drive motorMotorRRotingdirection";
CM_ SG_ 337 MCU_R_CrtSpd "Current speed of rear drive motorMotorRSpeed";
CM_ SG_ 337 MCU_R_CrtTq "Current torque of rear drive motorMotorRTorque";
CM_ SG_ 337 MCU_R_CrtSpdSigVld "Effective position of current speed signal of rear drive motorMotorRSpeedsignalvalidflag";
CM_ SG_ 337 MCU_R_CrtMod "Current working mode of rear drive motorMotorRworkingmode";
CM_ SG_ 337 MCU_R_Decoup_State "Disconnect status";
CM_ SG_ 337 MCU_R_HVActvDchaSts "High-voltage active discharge state of rear MCUHVActiveDischargeState";
CM_ SG_ 337 MCU_R_SlipCtrlActMode "the Anti-Slip Control (ASC or ASR on german) state";
CM_ SG_ 337 MCU_R_AlrmLamp_FS "Warning lamp_rear drive motor (functional safety)";
CM_ SG_ 337 MCU_R_HVChkEndFlg "High voltage detection completion flag of rear drive motor controllerMCURHVCheckStates";
CM_ SG_ 345 ACU_159_CheckSum "ACU_0x159_Message Checksum ( E2E data ID: 0x97)";
CM_ SG_ 345 ACU_159_AliveCounter "ACU_0x159_Message counterACU_159_AliveCounter";
CM_ SG_ 345 ACU_Pass_OCS_St "Passenger Occupant Status OCS (not for China)";
CM_ SG_ 345 ACU_AirBagSysAlrmLampSts "State of warning lamp of airbag system";
CM_ SG_ 345 ACU_Pass_Airbag_LED "Passenger LED Status";
CM_ SG_ 345 ACU_Drvr_Occpt_St "Driver Occupant Status";
CM_ SG_ 345 ACU_BucSwtStFrntDrvr "Buckle switch state front driver";
CM_ SG_ 345 ACU_BucSwtStFrntPass "Buckle switch state front passenger";
CM_ SG_ 345 ACU_SeatTrkPosnSwtFrntDrvr "Seat Track Position Sensor Front Driver";
CM_ SG_ 345 ACU_SeatTrkPosnSwtFrntPass "Seat Track Position Sensor Front Passenger";
CM_ SG_ 448 ADAS_1C0_CheckSum "ADAS_1C0_CheckSum (E2E data ID: 0xC3); Calculation E2E from byte 1~3";
CM_ SG_ 448 ADAS_1C0_AliveCounter "ADAS_1C0_AliveCounter";
CM_ SG_ 448 ADAS_LatCtrl_Sts "Lateral control function status";
CM_ SG_ 448 ADAS_LatCtrl_StsVld "Lateral control function status validity";
CM_ SG_ 448 ADAS_LatCtrl_DrvrOvrd "Lateral control driver overide";
CM_ SG_ 448 ADAS_LatCtrl_DrvrOvrdVld "Lateral control driver overide validity";
CM_ SG_ 448 ADAS_LatCtrl_Typ "Lateral control type of request";
CM_ SG_ 448 ADAS_LatCtrl_ReqVld "Lateral control request validity";
CM_ SG_ 448 ADAS_LatCtrl_Req "Lateral control command for activation of the request";
CM_ SG_ 450 EPS_1C2_CheckSum "EPS_1C2_Message check ( E2E data ID: 0x90)";
CM_ SG_ 450 EPS_1C2_AliveCounter "EP_1C2 _Message counterEPS_1C2_AliveCounter";
CM_ SG_ 450 EPS_AbortFb "EPS control interruption reason";
CM_ SG_ 450 EPS_SteerWhlAgSig "Steering wheel angle signal (counterclockwise as positive, clockwise as negative)Steering wheel angle left is positive, right is negative.";
CM_ SG_ 450 EPS_SteerAgSnsrCalSts "Calibration state of rotation angle sensor SAS Calibration status.";
CM_ SG_ 450 EPS_SteerWhlAgSigVld "Effective bit of steering wheel angle signal indicate Steer Wheel Angle signal valid or not.";
CM_ SG_ 450 EPS_SteerWhlRotSpdDir "Steering wheel speed direction Rotation speed direction of the steering wheel.";
CM_ SG_ 450 EPS_SteerWhlRotSpdVld "Effective Position of Steering Wheel Speed";
CM_ SG_ 450 EPS_SteerWhlRotSpd "Steering wheel speed (counterclockwise is positive, clockwise is negative)Rotation speed of the steering wheel.";
CM_ SG_ 450 EPS_AdasLatCtrlSts "EPS system available state Electrical Power Steering Available Status.";
CM_ SG_ 450 EPS_AdasLatCtrlStsVld "EPS system available state Electrical Power Steering Available valid Status.";
CM_ SG_ 450 EPS_AsscMotCrtTq "Current torque of EPS booster motor";
CM_ SG_ 452 EPS_1C4_CheckSum "EPS_1C4_Message check ( E2E data ID: 0x9C)";
CM_ SG_ 452 EPS_1C4_AliveCounter "EP_1C4EPS_1C4_AliveCounter";
CM_ SG_ 452 EPS_DrvrSteerTqDir "Driver steering torque direction (0 in counterclockwise and 1 in clockwise)";
CM_ SG_ 452 EPS_DrvrSteerTqVld "Effective Position of Driver Steering Torque";
CM_ SG_ 452 EPS_DrvrSteerTq "Driver steering torque";
CM_ SG_ 452 EPS_OTARdy_Fb "EPS OTA ready status feedback";
CM_ SG_ 452 EPS_DrvrIntvSteerWhlDetd "Detect driver intervention on steering wheel Driver Steering Interference Detected.";
CM_ SG_ 452 EPS_DrvrIntvSteerWhlVld "Effective position of driver intervention on steering wheel Driver Steering Interference Detected Validity.";
CM_ SG_ 452 EPS_SteerSnsrSts "Rotation angle sensor status SAS_Failure_Status.";
CM_ SG_ 452 EPS_PinionAg "Pinion rotation angle (positive counterclockwise, negative clockwise)";
CM_ SG_ 464 ADAS_1D0_CheckSum "ADAS_1D0_CheckSum (E2E data ID: 0x10),Calculate from byte1~3.";
CM_ SG_ 464 ADAS_1D0_AliveCounter "ADAS_1D0_AliveCounter";
CM_ SG_ 464 ADAS_LatCtrl_SteerAnReq "Lateral control steering angle request value";
CM_ SG_ 464 ADAS_1D0_SSecOC_Fresh_Byte0 "Short SecOC Fresh signal byte 0 on CAN";
CM_ SG_ 464 ADAS_1D0_SSecOC_MAC_Byte0 "Short SecOC MAC signal byte 0 on CAN";
CM_ SG_ 464 ADAS_1D0_SSecOC_MAC_Byte1 "Short SecOC MAC signal byte 1 on CAN";
CM_ SG_ 464 ADAS_1D0_SSecOC_MAC_Byte2 "Short SecOC MAC signal byte 2 on CAN";
CM_ SG_ 522 ADAS_LeLine2Offset "offset of the left lane line 2";
CM_ SG_ 522 ADAS_LeLine2LnTyp "True left lane line 2 type (observed)";
CM_ SG_ 522 ADAS_LeLine2Hdng "Heading of the left lane line 2";
CM_ SG_ 522 ADAS_LeLine2LnColor "Real right lane line 2 color (observation)";
CM_ SG_ 522 ADAS_LeLine2Crvt "Real left lane 2 curvature (observed)";
CM_ SG_ 522 ADAS_LeLine2CrvtRt "Rate of curvature of the left lane line 2";
CM_ SG_ 522 ADAS_LeLine2Conf "Left lane line 2 confidence";
CM_ SG_ 523 ADAS_LeLine3Offset "offset of the left lane line 3";
CM_ SG_ 523 ADAS_LeLine3LnTyp "True left lane line 3 type (observed)";
CM_ SG_ 523 ADAS_LeLine3Hdng "Heading of the left lane line 3";
CM_ SG_ 523 ADAS_LeLine3LnColor "Real right lane line 3 color (observation)";
CM_ SG_ 523 ADAS_LeLine3Crvt "Real left lane 3 curvature (observed)";
CM_ SG_ 523 ADAS_LeLine3CrvtRt "Rate of curvature of the left lane line 3";
CM_ SG_ 523 ADAS_LeLine3Conf "Left lane line 3 confidence";
CM_ SG_ 524 ADAS_RiLine1Offset "offset of the Right lane line 1";
CM_ SG_ 524 ADAS_RiLine1LnTyp "True right lane line 1 type (observation)";
CM_ SG_ 524 ADAS_RiLine1Hdng "Heading of the Right lane line 1";
CM_ SG_ 524 ADAS_RiLine1LnColor "Real right lane line 1 color (observation)";
CM_ SG_ 524 ADAS_RiLine1Crvt "Real Right lane 1 curvature (observed)";
CM_ SG_ 524 ADAS_RiLine1CrvtRt "Rate of curvature of the Right lane line 1";
CM_ SG_ 524 ADAS_RiLine1Conf "Right lane line 1 confidence";
CM_ SG_ 525 ADAS_RiLine2Offset "offset of the Right lane line 2";
CM_ SG_ 525 ADAS_RiLine2LnTyp "True right lane line 2 type (observation)";
CM_ SG_ 525 ADAS_RiLine2Hdng "Heading of the Right lane line 2";
CM_ SG_ 525 ADAS_RiLine2LnColor "Real right lane line 2 color (observation)";
CM_ SG_ 525 ADAS_RiLine2Crvt "Real Right lane 2 curvature (observed)";
CM_ SG_ 525 ADAS_RiLine2CrvtRt "Rate of curvature of the Right lane line 2";
CM_ SG_ 525 ADAS_RiLine2Conf "Right lane line 2 confidence";
CM_ SG_ 526 ADAS_RiLine3Offset "offset of the Right lane line 3";
CM_ SG_ 526 ADAS_RiLine3LnTyp "True right lane line 3 type (observation)";
CM_ SG_ 526 ADAS_RiLine3Hdng "Heading of the Right lane line 3";
CM_ SG_ 526 ADAS_RiLine3LnColor "Real right lane line 3 color (observation)";
CM_ SG_ 526 ADAS_RiLine3Crvt "Real Right lane 3 curvature (observed)";
CM_ SG_ 526 ADAS_RiLine3CrvtRt "Rate of curvature of the Right lane line 3";
CM_ SG_ 526 ADAS_RiLine3Conf "Right lane line 3 confidence";
CM_ SG_ 527 ADAS_RealLaneWidth "Real lane width (observed)";
CM_ SG_ 527 ADAS_EgoDecelLane "Ego deceleration lane";
CM_ SG_ 527 ADAS_EgoCarpoolLane "Ego carpool Lane";
CM_ SG_ 528 ADAS_TLR_EgoLaneTyp "ADAS TLR object 1";
CM_ SG_ 528 ADAS_TLR_EgoLaneSts "ADAS TLR object 1 status";
CM_ SG_ 528 ADAS_WSP_LeftCurb "Left Curb Detection";
CM_ SG_ 528 ADAS_TLR_EgoLaneColor "TLR Ego lane color";
CM_ SG_ 528 ADAS_TrafficLightShape "Status of the Detected Traffic light shpe ( Circle / Arrorw / Square) ";
CM_ SG_ 528 ADAS_TSRPassingCondition "Dispaly Overtaking Available or Not";
CM_ SG_ 528 ADAS_TLR_WarnReq "TLR warning request";
CM_ SG_ 528 ADAS_WSP_RightCurb "Right Curb Detection";
CM_ SG_ 528 ADAS_ISAOverSpeedWarning "ISA overspeed warning request";
CM_ SG_ 528 ADAS_TSRSignCondition "Stop, No Entry, School Zone, Caution, Construction Zone";
CM_ SG_ 528 ADAS_TSRSpdLimConfidenceLvl "signal shall be added to provide the Confidence of SLIF Percieved Speed Limit for ISA.";
CM_ SG_ 532 VCU_214_234_CheckSum "VCU_214_Message checksum (E2E data ID: 0x12)";
CM_ SG_ 532 VCU_214_234_AliveCounter "VCU_214_Packet counterVCU_214_AliveCounter";
CM_ SG_ 532 VCU_RdyLamp "READY lamp";
CM_ SG_ 532 VCU_BrkLampCtrlSts "Stop lamp control state";
CM_ SG_ 532 VCU_RemWakeUpEndFlg "Terminal wake-up end flag bit";
CM_ SG_ 532 VCU_StgyGearSig "Strategy gear signal";
CM_ SG_ 532 VCU_ShiftMisoper "Gear misoperation";
CM_ SG_ 532 VCU_GearSigVld "Effective bit of gear signal";
CM_ SG_ 532 VCU_GearSig "Gear signal";
CM_ SG_ 532 VCU_ACCRdy "ACC ready signal from VCU";
CM_ SG_ 532 VCU_ParkRdy "Park ready signal from VCU";
CM_ SG_ 532 VCU_APSPercVld "Effective position of accelerator pedal opening";
CM_ SG_ 532 VCU_VehSt "State of complete vehicle";
CM_ SG_ 532 VCU_APSPerc "Accelerator pedal opening";
CM_ SG_ 532 VCU_BrkSig "Brake signal";
CM_ SG_ 532 VCU_BrkSigVld "Effective bit of brake signal";
CM_ SG_ 532 VCU_DrvModSigFb "Driving mode signal feedback to ICC";
CM_ SG_ 532 VCU_DrvModShiftMisoper "Driving mode switching error operation";
CM_ SG_ 532 VCU_SpclTerrainModEnaSig "All-terrain driving mode enable signal";
CM_ SG_ 532 VCU_214_SSecOC_Fresh_Byte0 "Short SecOC Fresh signal byte 0 on CAN";
CM_ SG_ 532 VCU_214_SSecOC_MAC_Byte0 "Short SecOC MAC signal byte 0 on CAN";
CM_ SG_ 532 VCU_214_SSecOC_MAC_Byte1 "Short SecOC MAC signal byte 1 on CAN";
CM_ SG_ 532 VCU_214_SSecOC_MAC_Byte2 "Short SecOC MAC signal byte 2 on CAN";
CM_ SG_ 537 VCU_219_CheckSum "VCU_219_message checksum ( E2E data ID: 0xB9)";
CM_ SG_ 537 VCU_219_AliveCounter "VCU_219_Message counterVCU_219_AliveCounter";
CM_ SG_ 537 VCU_PreCdtFB "Communication between VCU-TBOX regarding feedback signal for pre-conditioning.";
CM_ SG_ 537 VCU_RemCtrlDrvgSts "Remote driving driving state";
CM_ SG_ 537 VCU_TioutPwrOffReq "timeout power-off request";
CM_ SG_ 537 VCU_RemCtrlDrvgEnaFlg "Remote driving enable flag position";
CM_ SG_ 537 VCU_RemCtrlDrvgEnaFlgVld "Effective bit of remote driving enable flag";
CM_ SG_ 537 VCU_RemCtrlDrvgPwrOnReq "Power-on demand of remote driving";
CM_ SG_ 537 VCU_RemCtrlDrvgExitFlg "Remote driving exit flag position";
CM_ SG_ 537 VCU_RemCtrlDrvgRelsReq "Remote driving release request";
CM_ SG_ 537 VCU_RemCtrlDrvgExitDisp "Remote driving exit display";
CM_ SG_ 537 VCU_RemCtrlDrvgBrkReq "Remote Driving Brake Request";
CM_ SG_ 537 VCU_RemCtrlDrvgEmgyBrkReq "Remote Driving Emergency Braking Request";
CM_ SG_ 537 VCU_RemCtrlDrvgModClsReq_VLC "Remote driving VLC off mode request";
CM_ SG_ 537 VCU_DrvrIntvGearSigVld "Effective bit of driver intervention gear signal";
CM_ SG_ 537 VCU_DrvrIntvGearSig "Driver intervention gear signal";
CM_ SG_ 537 VCU_GearUnderCtrlSts "Gear control state";
CM_ SG_ 537 VCU_PrefillReq "Pre-charge requestPrefill request for braking.";
CM_ SG_ 537 VCU_VehSecureHold "Safety condition requestVehicle secure condition.";
CM_ SG_ 537 VCU_VehSecureRels "Safety condition release requestVehicle secure condition released request.";
CM_ SG_ 537 VCU_AxReqActv "VCU longitudinal acceleration request activationAxrequest flag.";
CM_ SG_ 537 VCU_SpclTerrainModReq "VCU all terrain driving mode request";
CM_ SG_ 711 ADAS_APASlot5_FrLeCrnr_y "Front left corner y in body frame - slot 5";
CM_ SG_ 711 ADAS_APASlot5_FrRiCrnr_x "Front right corner x in body frame - slot 5";
CM_ SG_ 711 ADAS_APASlot5_FrRiCrnr_y "Front right corner y in body frame - slot 5";
CM_ SG_ 711 ADAS_APASlot5Typ "Slot 5 type";
CM_ SG_ 711 ADAS_APASlot5Sid "Slot 5 side";
CM_ SG_ 711 ADAS_APASlot5Sts "Slot 5 status";
CM_ SG_ 711 ADAS_APASlot5ID "Slot ID (1 - 15). Only tracks 6 parking slots. IDs shall rotate back to 1 after 6";
CM_ SG_ 714 ADAS_APASlotSel_ReLeCrnr_x "Rear left corner x in body frame - Selected slot";
CM_ SG_ 714 ADAS_APASlotSel_ReLeCrnr_y "Rear left corner y in body frame - Selected slot";
CM_ SG_ 714 ADAS_APASlotSel_ReRiCrnr_x "Rear right corner x in body frame - Selected slot";
CM_ SG_ 714 ADAS_APASlotSel_ReRiCrnr_y "Rear right corner y in body frame - Selected slot";
CM_ SG_ 714 ADAS_APASlotSel_FrLeCrnr_x "Front left corner x in body frame - Selected slot";
CM_ SG_ 717 ADAS_APASlotSel_FrLeCrnr_y "Front left corner y in body frame - Selected slot";
CM_ SG_ 717 ADAS_APASlotSel_FrRiCrnr_x "Front right corner x in body frame - Selected slot";
CM_ SG_ 717 ADAS_APASlotSel_FrRiCrnr_y "Front right corner y in body frame - Selected slot";
CM_ SG_ 717 ADAS_APASlotSelTyp "Selected slot type";
CM_ SG_ 717 ADAS_APASlotSelSid "Selected slot side";
CM_ SG_ 717 ADAS_APASlotSelSts "Selected slot status";
CM_ SG_ 717 ADAS_APASlotSelID "Slot ID (1 - 15). Only tracks 6 parking slots. IDs shall rotate back to 1 after 6";
CM_ SG_ 717 ADAS_APAAvailable "Status flag to indicate park in or out is available to HMI";
CM_ SG_ 717 ADAS_APAScanngSde "Scanning direction to HMI";
CM_ SG_ 717 ADAS_CurbPrtcRrLeWhl "Curb warning side - rear left";
CM_ SG_ 717 ADAS_CurbPrtcRrRiWhl "Curb warning side - rear right";
CM_ SG_ 717 ADAS_CurbPrtcFrLeWhl "Curb warning side - front left";
CM_ SG_ 717 ADAS_CurbPrtcFrRiWhl "Curb warning side - front right";
CM_ SG_ 717 ADAS_APASpdWarn "Warning seek speed exceed status to HMI";
CM_ SG_ 720 ADAS_APASlot1_ReLeCrnr_x "Rear left corner x in body frame - slot 1";
CM_ SG_ 720 ADAS_APASlot1_ReLeCrnr_y "Rear left corner y in body frame - slot 1";
CM_ SG_ 720 ADAS_APASlot1_ReRiCrnr_x "Rear right corner x in body frame - slot 1";
CM_ SG_ 720 ADAS_APASlot1_ReRiCrnr_y "Rear right corner y in body frame - slot 1";
CM_ SG_ 720 ADAS_APASlot1_FrLeCrnr_x "Front left corner x in body frame - slot 1";
CM_ SG_ 723 ADAS_APASlot1_FrLeCrnr_y "Front left corner y in body frame - slot 1";
CM_ SG_ 723 ADAS_APASlot1_FrRiCrnr_x "Front right corner x in body frame - slot 1";
CM_ SG_ 723 ADAS_APASlot1_FrRiCrnr_y "Front right corner y in body frame - slot 1";
CM_ SG_ 723 ADAS_APASlot1Typ "Slot 1 type";
CM_ SG_ 723 ADAS_APASlot1Sid "Slot 1 side";
CM_ SG_ 723 ADAS_APASlot1Sts "Slot 1 status";
CM_ SG_ 723 ADAS_APASlot1ID "Slot ID (1 - 15). Only tracks 6 parking slots. IDs shall rotate back to 1 after 6";
CM_ SG_ 726 ADAS_APASlot2_ReLeCrnr_x "Rear left corner x in body frame - slot 2";
CM_ SG_ 726 ADAS_APASlot2_ReLeCrnr_y "Rear left corner y in body frame - slot 2";
CM_ SG_ 726 ADAS_APASlot2_ReRiCrnr_x "Rear right corner x in body frame - slot 2";
CM_ SG_ 726 ADAS_APASlot2_ReRiCrnr_y "Rear right corner y in body frame - slot 2";
CM_ SG_ 726 ADAS_APASlot2_FrLeCrnr_x "Front left corner x in body frame - slot 2";
CM_ SG_ 729 ADAS_APASlot2_FrLeCrnr_y "Front left corner y in body frame - slot 2";
CM_ SG_ 729 ADAS_APASlot2_FrRiCrnr_x "Front right corner x in body frame - slot 2";
CM_ SG_ 729 ADAS_APASlot2_FrRiCrnr_y "Front right corner y in body frame - slot 2";
CM_ SG_ 729 ADAS_APASlot2Typ "Slot 2 type";
CM_ SG_ 729 ADAS_APASlot2Sid "Slot 2 side";
CM_ SG_ 729 ADAS_APASlot2Sts "Slot 2 status";
CM_ SG_ 729 ADAS_APASlot2ID "Slot ID (1 - 15). Only tracks 6 parking slots. IDs shall rotate back to 1 after 6";
CM_ SG_ 732 ADAS_APASlot3_ReLeCrnr_x "Rear left corner x in body frame - slot 3";
CM_ SG_ 732 ADAS_APASlot3_ReLeCrnr_y "Rear left corner y in body frame - slot 3";
CM_ SG_ 732 ADAS_APASlot3_ReRiCrnr_x "Rear right corner x in body frame - slot 3";
CM_ SG_ 732 ADAS_APASlot3_ReRiCrnr_y "Rear right corner y in body frame - slot 3";
CM_ SG_ 732 ADAS_APASlot3_FrLeCrnr_x "Front left corner x in body frame - slot 3";
CM_ SG_ 735 ADAS_APASlot3_FrLeCrnr_y "Front left corner y in body frame - slot 3";
CM_ SG_ 735 ADAS_APASlot3_FrRiCrnr_x "Front right corner x in body frame - slot 3";
CM_ SG_ 735 ADAS_APASlot3_FrRiCrnr_y "Front right corner y in body frame - slot 3";
CM_ SG_ 735 ADAS_APASlot3Typ "Slot 3 type";
CM_ SG_ 735 ADAS_APASlot3Sid "Slot 3 side";
CM_ SG_ 735 ADAS_APASlot3Sts "Slot 3 status";
CM_ SG_ 735 ADAS_APASlot3ID "Slot ID (1 - 15). Only tracks 6 parking slots. IDs shall rotate back to 1 after 6";
CM_ SG_ 738 ADAS_APASlot4_ReLeCrnr_x "Rear left corner x in body frame - slot 4";
CM_ SG_ 738 ADAS_APASlot4_ReLeCrnr_y "Rear left corner y in body frame - slot 4";
CM_ SG_ 738 ADAS_APASlot4_ReRiCrnr_x "Rear right corner x in body frame - slot 4";
CM_ SG_ 738 ADAS_APASlot4_ReRiCrnr_y "Rear right corner y in body frame - slot 4";
CM_ SG_ 738 ADAS_APASlot4_FrLeCrnr_x "Front left corner x in body frame - slot 4";
CM_ SG_ 741 ADAS_APASlot4_FrLeCrnr_y "Front left corner y in body frame - slot 4";
CM_ SG_ 741 ADAS_APASlot4_FrRiCrnr_x "Front right corner x in body frame - slot 4";
CM_ SG_ 741 ADAS_APASlot4_FrRiCrnr_y "Front right corner y in body frame - slot 4";
CM_ SG_ 741 ADAS_APASlot4Typ "Slot 4 type";
CM_ SG_ 741 ADAS_APASlot4Sid "Slot 4 side";
CM_ SG_ 741 ADAS_APASlot4Sts "Slot 4 status";
CM_ SG_ 741 ADAS_APASlot4ID "Slot ID (1 - 15). Only tracks 6 parking slots. IDs shall rotate back to 1 after 6";
CM_ SG_ 744 ADAS_APASlot5_ReLeCrnr_x "Rear left corner x in body frame - slot 5";
CM_ SG_ 744 ADAS_APASlot5_ReLeCrnr_y "Rear left corner y in body frame - slot 5";
CM_ SG_ 744 ADAS_APASlot5_ReRiCrnr_x "Rear right corner x in body frame - slot 5";
CM_ SG_ 744 ADAS_APASlot5_ReRiCrnr_y "Rear right corner y in body frame - slot 5";
CM_ SG_ 744 ADAS_APASlot5_FrLeCrnr_x "Front left corner x in body frame - slot 5";
CM_ SG_ 745 ADAS_APASlot6_ReLeCrnr_x "Rear left corner x in body frame - slot 6";
CM_ SG_ 745 ADAS_APASlot6_ReLeCrnr_y "Rear left corner y in body frame - slot 6";
CM_ SG_ 745 ADAS_APASlot6_ReRiCrnr_x "Rear right corner x in body frame - slot 6";
CM_ SG_ 745 ADAS_APASlot6_ReRiCrnr_y "Rear right corner y in body frame - slot 6";
CM_ SG_ 745 ADAS_APASlot6_FrLeCrnr_x "Front left corner x in body frame - slot 6";
CM_ SG_ 746 ADAS_APASlot6_FrLeCrnr_y "Front left corner y in body frame - slot 6";
CM_ SG_ 746 ADAS_APASlot6_FrRiCrnr_x "Front right corner x in body frame - slot 6";
CM_ SG_ 746 ADAS_APASlot6_FrRiCrnr_y "Front right corner y in body frame - slot 6";
CM_ SG_ 746 ADAS_APASlot6ID "Slot ID (1 - 15). Only tracks 6 parking slots. IDs shall rotate back to 1 after 6";
CM_ SG_ 746 ADAS_APASlot6Sid "Slot 6 side";
CM_ SG_ 746 ADAS_APASlot6Sts "Slot 6 status";
CM_ SG_ 746 ADAS_APASlot6Typ "Slot 6 type";
CM_ SG_ 785 ADAS_311_CheckSum "ADAS_0x311_message checksum (E2E data ID: 0x4F)";
CM_ SG_ 785 ADAS_311_AliveCounter "ADAS_311_Message counter";
CM_ SG_ 785 ADAS_HiPrioDegradationSts "ADAS high priority feature degradation status, used to popup a window on central display when the feature reaches the safe state";
CM_ SG_ 785 ADAS_ISA_PerSpdLim_req "Signal to notify the driver for the speed limit change between SLIF percieved speed limit and Speedometer speed.";
CM_ SG_ 785 ADAS_LoPrioDegradationSts "ADAS low priority feature degradation status, used to popup a window on central display when the feature reaches the safe state";
CM_ SG_ 785 ADAS_SpeedLimitUnit "Change speed Unit (kmh /Mph)";
CM_ SG_ 785 ADAS_ISA_SpdLmt "ISA detected speed limit + user selected offset";
CM_ SG_ 785 ADAS_TSRSpeedLimitAddOn "TSR speed limit add on";
CM_ SG_ 785 ADAS_TSRSpeedLimit "TSR speed limit";
CM_ SG_ 787 ADAS_313_CheckSum "ADAS_313_Message checksum ( E2E data ID: 0x4B)";
CM_ SG_ 787 ADAS_313_AliveCounter "ADAS_313_Message counter";
CM_ SG_ 787 ADAS_FACM_Sts "FACM status";
CM_ SG_ 787 ADAS_BACM_Sts "BACM status";
CM_ SG_ 787 AEB_ReAEB_Sts "Status of Rear AEB function";
CM_ SG_ 787 ADAS_Sts_ACC_ICC "Automatic Cruise Control (ACC) status";
CM_ SG_ 787 ADAS_TJA_AutoSteerSts "Traffic Jam Assist (TJA) autosteer status";
CM_ SG_ 787 ADAS_ISASts "ISA status_for ICC use to display either fault and confirm on_off";
CM_ SG_ 787 ADAS_Sts_TLR "TLR status";
CM_ SG_ 787 ADAS_TSRSts "TSR Information receive status ( Camera / Navi / fusion ) ";
CM_ SG_ 788 ADAS_314_CheckSum "ADAS_314_Message checksum ( E2E data ID:0x4E)";
CM_ SG_ 788 ADAS_314_AliveCounter "ADAS_314_Message counter";
CM_ SG_ 788 ADAS_LKASts "This signal indicates the lane keeping system state. It is used to illuminate the lane line ego vehicle is about to cross.";
CM_ SG_ 788 ADAS_ELKASts "This signal indicates the emergency lane keeping system state. It is used to illuminate the lane line ego vehicle is about to cross.";
CM_ SG_ 788 ADAS_LCA_Sts "Lane Change Assist status";
CM_ SG_ 788 ADAS_LCA_Maneuver_Status "Indication to the driver when LCA maneuver is suppressed";
CM_ SG_ 788 ADAS_APASts "Advanced Park Assist (APA) status";
CM_ SG_ 788 ADAS_WSPPASts "Wheel Scratch Prevention feature State";
CM_ SG_ 788 ADAS_DOW_Sts "Door Open Warning (DOW) status";
CM_ SG_ 788 ADAS_BSDSts "Blind Spot Detection (BSD) feature status";
CM_ SG_ 788 ADAS_DCAASts "Driver Condition and Attention Assist (DCAA) status";
CM_ SG_ 788 ADAS_AHBA_Sts "Auto high beam status";
CM_ SG_ 788 ADAS_AHBA_BeamDecisRsn "Beam Decision Reason to request low beam or high beam. For Development use only";
CM_ SG_ 789 ADAS_DOW_ThreatIDLeft "Object ID of the left threat";
CM_ SG_ 789 ADAS_DOW_ThreatIDRight "Object ID of the right threat";
CM_ SG_ 789 ADAS_DOW_CID_LeDispReq "Door Open Warning (DOW) display request on CID left side (central screen)";
CM_ SG_ 789 ADAS_DOW_CID_RiDispReq "Door Open Warning (DOW) display request on CID right side (central screen)";
CM_ SG_ 789 ADAS_BSDLeftThreatID "BSD Threat Object ID Left side";
CM_ SG_ 789 ADAS_BSDRightThreatID "BSD Threat Object ID Right Side";
CM_ SG_ 789 ADAS_BSD_CID_LeDispReq "Blind Spot Detection (BSD) display request on CID left side (central screen)";
CM_ SG_ 789 ADAS_BSD_CID_RiDispReq "Blind Spot Detection (BSD) display request on CID right side (central screen)";
CM_ SG_ 789 ADAS_DCAA_WarnLvlReq "Driver Condition and Attention Assist (DCAA) warning level request";
CM_ SG_ 789 ADAS_DCAA_GazeOnWarnReq "Driver Condition and Attention Assist (DCAA) gaze on warning request. Reserved for future development, could be the additional requirement to launch the vehicle after long ACC stop (> 3 sec) ";
CM_ SG_ 790 ADASDC_SVS_ViewSts "Signal from ADAS transmitting current Surround View display view";
CM_ SG_ 790 ADASDC_SVS_AvailableSts "Reasons for SVS not available";
CM_ SG_ 790 ADASDC_SVS_RrCamBttnShw "This signal controls when the rear view camera button will be drawn on the CID.";
CM_ SG_ 790 ADASDC_SVS_WdAnglBttnShw "This signal controls when the wide angle camera view toggle button will be drawn on the CID.";
CM_ SG_ 790 ADASDC_SVS_FrntWdAnglBttnShw "This signal controls when the front wide angle camera view button will be drawn on the CID.";
CM_ SG_ 790 ADASDC_SVS_3DCamBttnShw "This signal controls when the 3D camera view button will be drawn on the CID.";
CM_ SG_ 790 ADASDC_SVS_AutoVwBttnShw "This signal controls when the automatic camera view button will be drawn on the CID.";
CM_ SG_ 790 ADASDC_SVS_RearMidBttnShw "Propose this CAN signal to enable the rear button on birdseye view";
CM_ SG_ 790 ADASDC_SVS_FrntMidBttnShw "Propose this CAN signal to enable the Front button on birdseye view";
CM_ SG_ 790 ADASDC_SVS_SplitBttnShw "Propose this CAN signal to enable the split curb button on birdseye view";
CM_ SG_ 790 ADASDC_SVS_LeftFlnk3DBttnShw "Propose this CAN signal to enable the Left Flank button on birdseye view";
CM_ SG_ 790 ADASDC_SVS_RightFlnk3DBttnShw "Propose this CAN signal to enable the right Flank button on birdseye view";
CM_ SG_ 790 ADASDC_SVS_ShowReq "Request from ADAS to show SVS on screen";
CM_ SG_ 791 ADAS_317_CheckSum "ADAS_0x317_message checksum ( E2E data ID:0xCD)";
CM_ SG_ 791 ADAS_317_AliveCounter "ADAS_317_Message counter";
CM_ SG_ 791 ADAS_LeMirrWarnSrc "Left mirror warning source (or reason). Signal used as information only";
CM_ SG_ 791 ADAS_LeMirrWarnReq "Left Mirror warning request";
CM_ SG_ 791 ADAS_ChimeReq "This signal controls the chime type for ADAS features.";
CM_ SG_ 791 ADAS_IDS_WarnTxtReq "ADAS warning text on IDS ";
CM_ SG_ 791 ADAS_RiMirrWarnReq "Right mirror warning request";
CM_ SG_ 791 ADAS_IDS_LeWarnReq "Left warning on IDS (instrument cluster) request";
CM_ SG_ 791 ADAS_IDS_RiWarnReq "Right warning on IDS (instrument cluster) request";
CM_ SG_ 791 ADAS_IDS_LeWarnSrc "Left warning on IDS (instrument cluster) source. Signal used as information only";
CM_ SG_ 791 ADAS_IDS_RiWarnSrc "Right warning on IDS (instrument cluster) source. Signal used as information only";
CM_ SG_ 791 ADAS_SysFltWarnReq "ADAS fault telltale icon (on the cluster) warning request.";
CM_ SG_ 791 ADAS_SysFltTyp "This signal indicates ADAS fault types to be displayed on CID or cluster or both.";
CM_ SG_ 791 ADAS_RiMirrWarnSrc "Right mirror warning source (or reason). Signal used as information only";
CM_ SG_ 791 ADAS_DrvrTakeOvrReq "This signal indicates to the driver that takepover is necessary. Different stage are used.";
CM_ SG_ 792 ESP_318_CheckSum "ESP318_Message Checksum ( E2E data ID: 0x79)";
CM_ SG_ 792 ESP_318_AliveCounter "ESP 3318_Message counterESP_318_AliveCounter";
CM_ SG_ 792 ESP_BrkPedlStsVld "Effective position of brake pedal state validity of BRAKE_STATUS_ESP.";
CM_ SG_ 792 ESP_BrkPedlSts "Brake pedal state indicating brake pedal activated by driver or not.";
CM_ SG_ 792 ESP_VehSpdVld "ABS_ESC signal indicates whether the vehicle speed is valid When the diagnostic have set the failure code on this signal the value wil be 2.";
CM_ SG_ 792 ESP_SysActv "ESP works effectively Is used to indicate to the driver that the system is currently active. Not used for ABS.";
CM_ SG_ 792 ESP_LampSwtOffIndcn "ESP OFF indication Signal indicates to light up 'TCS/ESP off' lamp.-manual switch off of ESP function (on/off switch).Not used for ABS.";
CM_ SG_ 792 ESP_FltIndcn_EBD "EBD fault indication Signal indicates to light up EBD lamp.";
CM_ SG_ 792 ESP_FltIndcn_ABS "ABS fault indication Signal indicates to light up ABS lamp.";
CM_ SG_ 792 ESP_MilgRollgCntr_ODO "Mileage statistical pulse Odometer rolling count 1 pulse/bit. The value shall be set to zero at every ignition off and if the counter reach max value it starts from zero again.";
CM_ SG_ 792 ESP_VehSpd "Speed signal";
CM_ SG_ 792 ESP_IninModSigIndcn "The signal needs to cover the time of ESP and ABS fault signals caused by self-inspection. Signal indicates if ESP or ABS is in initialization mode or not.";
CM_ SG_ 792 ESP_FltIndcn_TCS "ESP/TCS fault indication Signal indicates failure monitoring of ESP function. Not used for ABS";
CM_ SG_ 792 ESP_CtrlSts_HDC "Indicate that the HDC is on/off or working, and the ADAS receives this signal to determine whether the ACC is off. HDC control(Off/On, not active braking/On, active braking).";
CM_ SG_ 792 ESP_AvlIndcn_HDC "Effective bit of HDC indicating HDC is available or not.";
CM_ SG_ 792 ESP_NoBrkP "When the vehicle is stationary, whether the function has braking force or not, whether it is braking.no brake pressure applied; generally it regards wheel cylinder presure.";
CM_ SG_ 792 ESP_RDAEnaFlg "ESP remote driving function enable flag position";
CM_ SG_ 794 ADAS_31A_CheckSum "ADAS_31A_Message Verification (E2E data ID: 0x37)";
CM_ SG_ 794 ADAS_31A_AliveCounter "ESP 31A_Message counterESP_31A_AliveCounter";
CM_ SG_ 794 ADAS_RAEBAvl "Indicates tha the Rear AEB is ready (available)";
CM_ SG_ 794 ADAS_FACM_TelltaleReq "FACM telltale request";
CM_ SG_ 794 ADAS_BACM_WarnSide "BACM warning side";
CM_ SG_ 794 ADAS_BrakeIntrvntnSt "Brake Assist status ADAS_BrkAssistSts";
CM_ SG_ 794 ADAS_AEB_Typ "AEB type for ICC";
CM_ SG_ 794 ADAS_AEBWarnSts "AEB warning status";
CM_ SG_ 794 ADAS_AEB_RAEB_WarnReq "Rear AEB warning request ";
CM_ SG_ 794 ADAS_RAEB_ThreatID "Rear AEB Object ID of the threat";
CM_ SG_ 794 ADAS_AEBThreatID "AEB Threat ID";
CM_ SG_ 794 ADAS_BACMThreatID "BACM threat identifier";
CM_ SG_ 794 ADAS_BSM_ELKA_TelltaleReq " BSM-telltale on the cluster";
CM_ SG_ 794 ADAS_ESA_TelltaleReq "ESA IDS(Instrument Cluster) Telltale request";
CM_ SG_ 794 ADAS_ELKA_TelltaleReq "ELKA LKA IDS(Instrument Cluster) Telltale request";
CM_ SG_ 795 ADAS_31B_CheckSum "ADAS_31B_Message Verification ( E2E data ID: 0x5A)";
CM_ SG_ 795 ADAS_31B_AliveCounter "ESP 31A_Message counterESP_31B_AliveCounter";
CM_ SG_ 795 ADAS_LCA_TrajectoryHeadingAngle "Lane change Trajectory end point Heading";
CM_ SG_ 795 ADAS_LaneCenteringHandsOnRew "Lane Centering Hands on request";
CM_ SG_ 795 ADAS_LCA_TrajectoryX "Lane Change Trajectory of the ego vehicle";
CM_ SG_ 795 ADAS_LCA_TrajectoryY "Lane change Trajectory end point Y, negative is m to the left, positive is m to the right";
CM_ SG_ 795 ADAS_ELKAThreatID "ELKA threat identifier";
CM_ SG_ 796 ADAS_AccTrgSpdDisp "Automatic Cruise Control (ACC) target speed display";
CM_ SG_ 796 ADAS_DispSpdUnit_ACC "Automatic Cruise Control (ACC) display unit";
CM_ SG_ 796 ADAS_AccTrgSpdOvrLmt "Automatic Cruise Control (ACC) target speed over limit";
CM_ SG_ 796 ADAS_TiGapSet_ACC "Automatic Cruise Control (ACC) time gap setting";
CM_ SG_ 796 ADAS_TiGapRecommendation_ACC "Automatic Cruise Control (ACC) recommendation for driver to change time gap at hight speed for safer following distance";
CM_ SG_ 796 ADAS_ACCPrimTgtID "Automatic Cruise Control (ACC) primary target identifier";
CM_ SG_ 796 ADAS_ACCScndTgtID "Automatic Cruise Control (ACC) secondary target identifier";
CM_ SG_ 796 ADAS_ACCIconDisp "ACC icon color";
CM_ SG_ 796 ADAS_ACCDegrdReq "Automatic Cruise Control (ACC) degradation to Cruise Control (CC) request";
CM_ SG_ 796 ADAS_ACCFuncTyp "Automatic Cruise Control (ACC) function type";
CM_ SG_ 801 BCM_AP_FL_LeFrntWinPosnInfo "Information about left front window opening";
CM_ SG_ 801 BCM_AP_FL_RiFrntWinPosnInfo "Right front window opening information";
CM_ SG_ 801 BCM_AP_FL_LeReWinPosnInfo "Left rear window opening information";
CM_ SG_ 801 BCM_AP_FL_RiReWinPosnInfo "Right rear window opening information";
CM_ SG_ 801 BCM_ValueLightFrnt_RLS "Front sensor measurement valueOutput value of forward light detection value";
CM_ SG_ 801 BCM_LightReqReason_RLS "Rain light sensor turn on light request reasonLight switch reason";
CM_ SG_ 811 ADAS_32B_CheckSum "ADAS_32B_CheckSum (E2E data ID: 0x5B)";
CM_ SG_ 811 ADAS_32B_AliveCounter "ADAS_32B_AliveCounter";
CM_ SG_ 811 ADAS_SelfGlaring "Self-glaring probability";
CM_ SG_ 811 ADAS_Obj_TrfcStyle "Traffic type";
CM_ SG_ 811 ADAS_CamSts "Camera state";
CM_ SG_ 811 ADAS_ObjNr "Detection target number";
CM_ SG_ 811 ADAS_AmbLi "Ambient brightness";
CM_ SG_ 811 ADAS_RoadIllmn "Street lamp detection";
CM_ SG_ 813 ADAS_Obj3_ID "Object identifier. If ID is 0x0 no object is detected";
CM_ SG_ 813 ADAS_Obj3_LongDist "Object Longitudinal distance (0.2 m/bit measured on the car; the matrix says 0.5)";
CM_ SG_ 813 ADAS_Obj3_LatDist "Object Latitudinal distance (0.2 m/bit measured on the car; the matrix says 0.5)";
CM_ SG_ 813 ADAS_Obj3_Width "Object Width";
CM_ SG_ 813 ADAS_Obj3_Conf "Object Confidence level";
CM_ SG_ 813 ADAS_Obj3_Length "Object length";
CM_ SG_ 813 ADAS_VVP_ICC_Obj3Hdng "Object 3 Heading Angle";
CM_ SG_ 813 ADAS_Obj3_Height "Object height";
CM_ SG_ 813 ADAS_Obj3_LongDistSign "Object longitudinal Distance Signal";
CM_ SG_ 813 ADAS_Obj3_LatDistSign "Object Latitudinal Distance Signal";
CM_ SG_ 813 ADAS_Obj3_Classification "Object Calssification";
CM_ SG_ 813 ADAS_VVP_ICC_Obj3BrkLght "Object 3 brake light on / off";
CM_ SG_ 813 ADAS_Obj3_ClassConf "Object Classification Confidence";
CM_ SG_ 815 ADAS_Obj6_ID "Object identifier. If ID is 0x0 no object is detected";
CM_ SG_ 815 ADAS_Obj6_LongDist "Object Longitudinal distance (0.2 m/bit measured on the car; the matrix says 0.5)";
CM_ SG_ 815 ADAS_Obj6_LatDist "Object Latitudinal distance (0.2 m/bit measured on the car; the matrix says 0.5)";
CM_ SG_ 815 ADAS_Obj6_Width "Object Width";
CM_ SG_ 815 ADAS_Obj6_Conf "Object Confidence level";
CM_ SG_ 815 ADAS_Obj6_Length "Object length";
CM_ SG_ 815 ADAS_VVP_ICC_Obj6Hdng "Object 6 Heading Angle";
CM_ SG_ 815 ADAS_Obj6_Height "Object height";
CM_ SG_ 815 ADAS_Obj6_LongDistSign "Object longitudinal Distance Signal";
CM_ SG_ 815 ADAS_Obj6_LatDistSign "Object Latitudinal Distance Signal";
CM_ SG_ 815 ADAS_Obj6_Classification "Object Calssification";
CM_ SG_ 815 ADAS_VVP_ICC_Obj6BrkLght "Object 6 brake light on / off";
CM_ SG_ 815 ADAS_Obj6_ClassConf "Object Classification Confidence";
CM_ SG_ 819 BCM_333_CheckSum "BCM333_message checksum ( 0xCB)BCM_333_CheckSum";
CM_ SG_ 819 BCM_333_AliveCounter "BCM333_Packet counterBCM_333_AliveCounter";
CM_ SG_ 819 BCM_KL15_Off_Announcement "Before switching off the KL15 (5s), this signal gets active to inform other ECUs that the KL15 will be disabled in 5seconds if there are still no triggers to keep it active";
CM_ SG_ 819 BCM_IG1Sts "IG1 state";
CM_ SG_ 819 BCM_PwrMod "Power mode";
CM_ SG_ 819 BCM_PwrModVld "Effective value of power mode";
CM_ SG_ 819 BCM_BrkSwtSts "Brake switch status";
CM_ SG_ 819 BCM_IG1StsVld_CAPE "Effective value of IG1 state";
CM_ SG_ 819 BCM_IG2StsVld_CAPE "Effective value of IG2 state";
CM_ SG_ 819 BCM_KL30s_L "Logical State of KL30";
CM_ SG_ 819 BCM_IG2Sts "IG2 state";
CM_ SG_ 819 BCM_InteriorSwtSt "Interior switch status from LIN1";
BA_ "GenMsgCycleTime" BO_ 258 10;
BA_ "GenMsgCycleTime" BO_ 274 10;
BA_ "GenMsgCycleTime" BO_ 275 10;
BA_ "GenMsgCycleTime" BO_ 276 20;
BA_ "GenMsgCycleTime" BO_ 277 10;
BA_ "GenMsgCycleTime" BO_ 278 10;
BA_ "GenMsgCycleTime" BO_ 279 10;
BA_ "GenMsgCycleTime" BO_ 280 10;
BA_ "GenMsgCycleTime" BO_ 288 10;
BA_ "GenMsgCycleTime" BO_ 289 10;
BA_ "GenMsgCycleTime" BO_ 336 10;
BA_ "GenMsgCycleTime" BO_ 337 10;
BA_ "GenMsgCycleTime" BO_ 345 100;
BA_ "GenMsgCycleTime" BO_ 448 10;
BA_ "GenMsgCycleTime" BO_ 450 10;
BA_ "GenMsgCycleTime" BO_ 452 10;
BA_ "GenMsgCycleTime" BO_ 464 10;
BA_ "GenMsgCycleTime" BO_ 522 50;
BA_ "GenMsgCycleTime" BO_ 523 50;
BA_ "GenMsgCycleTime" BO_ 524 50;
BA_ "GenMsgCycleTime" BO_ 525 50;
BA_ "GenMsgCycleTime" BO_ 526 50;
BA_ "GenMsgCycleTime" BO_ 527 50;
BA_ "GenMsgCycleTime" BO_ 528 50;
BA_ "GenMsgCycleTime" BO_ 532 10;
BA_ "GenMsgCycleTime" BO_ 537 20;
BA_ "GenMsgCycleTime" BO_ 711 100;
BA_ "GenMsgCycleTime" BO_ 714 100;
BA_ "GenMsgCycleTime" BO_ 717 100;
BA_ "GenMsgCycleTime" BO_ 720 100;
BA_ "GenMsgCycleTime" BO_ 723 100;
BA_ "GenMsgCycleTime" BO_ 726 100;
BA_ "GenMsgCycleTime" BO_ 729 100;
BA_ "GenMsgCycleTime" BO_ 732 100;
BA_ "GenMsgCycleTime" BO_ 735 100;
BA_ "GenMsgCycleTime" BO_ 738 100;
BA_ "GenMsgCycleTime" BO_ 741 100;
BA_ "GenMsgCycleTime" BO_ 744 100;
BA_ "GenMsgCycleTime" BO_ 745 100;
BA_ "GenMsgCycleTime" BO_ 746 100;
BA_ "GenMsgCycleTime" BO_ 785 20;
BA_ "GenMsgCycleTime" BO_ 787 20;
BA_ "GenMsgCycleTime" BO_ 788 20;
BA_ "GenMsgCycleTime" BO_ 789 50;
BA_ "GenMsgCycleTime" BO_ 790 50;
BA_ "GenMsgCycleTime" BO_ 791 50;
BA_ "GenMsgCycleTime" BO_ 792 20;
BA_ "GenMsgCycleTime" BO_ 794 50;
BA_ "GenMsgCycleTime" BO_ 795 50;
BA_ "GenMsgCycleTime" BO_ 796 50;
BA_ "GenMsgCycleTime" BO_ 801 50;
BA_ "GenMsgCycleTime" BO_ 811 40;
BA_ "GenMsgCycleTime" BO_ 813 40;
BA_ "GenMsgCycleTime" BO_ 815 40;
BA_ "GenMsgCycleTime" BO_ 819 50;
VAL_ 258 VCU_DrvrFrntMotTqReqVld 0 "Initializing" 1 "Valid" 2 "Invalid" 3 "Reserved" ;
VAL_ 258 VCU_DrvrReMotTqReqVld 0 "Initializing" 1 "Valid" 2 "Invalid" 3 "Reserved" ;
VAL_ 258 VCU_CoastTqReqVld 0 "Initializing" 1 "Valid" 2 "Invalid" 3 "Reserved" ;
VAL_ 274 YRS_YawRateCalSts 0 "Sensor_Not_Calibrated" 1 "Sensor_Calibrated" ;
VAL_ 274 YRS_YawRateSnsrSts 0 "Initializing" 1 "Valid" 2 "Invalid" 3 "Reserved" ;
VAL_ 274 YRS_LatSnsrSts 0 "Initializing" 1 "Valid" 2 "Invalid" 3 "Reserved" ;
VAL_ 275 YRS_LgtSnsrSts 0 "Initializing" 1 "Valid" 2 "Invalid" 3 "Reserved" ;
VAL_ 276 ESP_OTARdy_Fb 0 "Initial" 1 "Ready" 2 "Not_Ready" 3 "Invalid" ;
VAL_ 276 ESP_FltIndcn_DTC 0 "No_Fault" 1 "Fault" ;
VAL_ 276 ESP_ActvSig_VDC 0 "ESP_Standby" 1 "ESP_Actually_Operating" ;
VAL_ 276 ESP_ActvSig_TCS 0 "TCS_Standby" 1 "TCS_Actually_Operating" ;
VAL_ 276 ESP_ActvSig_EBD 0 "EBD_Not_Active" 1 "EBD_Active" ;
VAL_ 276 ESP_ActvSig_DTC 0 "DTC_Not_Active" 1 "DTC_Active" ;
VAL_ 276 ESP_WarningOn 0 "No_Request" 1 "Yellow_Lamp_Request" 2 "Red_Lamp_Request" 3 "Reserved" ;
VAL_ 276 ESP_Actvndcn_CDD 0 "Not_Active" 1 "Active" ;
VAL_ 276 ESP_FltIndcn_CDD 0 "Available" 1 "Not_Available" ;
VAL_ 276 ESP_ActvIndcn_ABA 0 "Not_Active" 1 "Active" ;
VAL_ 276 ESP_FltIndcn_ABA 0 "Available" 1 "Not_Available" ;
VAL_ 276 ESP_ActvIndcn_ABP 0 "Not_Active" 1 "Active" ;
VAL_ 276 ESP_FltIndcn_ABP 0 "Available" 1 "Not_Available" ;
VAL_ 276 ESP_ActvIndcn_AEB 0 "Not_Active" 1 "Active" ;
VAL_ 276 ESP_FltIndcn_AEB 0 "Available" 1 "Not_Available" ;
VAL_ 276 ESP_ActvIndcn_AWB 0 "Not_Active" 1 "Active" ;
VAL_ 276 ESP_FltIndcn_AWB 0 "Available" 1 "Not_Available" ;
VAL_ 276 ESP_VehStandstillIndcn 0 "Not_Standstill" 1 "Standstill" 2 "Invalid" 3 "Reserved" ;
VAL_ 276 ESP_BrkOverTIndcn 0 "Not_High" 1 "Temp_Too_High" ;
VAL_ 276 ESP_FltIndcn_VDC 0 "No_Fault" 1 "Fault" ;
VAL_ 276 ESP_ActvIndcn_CDD_AP 0 "Not_Active" 1 "Active" ;
VAL_ 276 ESP_FltIndcn_CDD_AP 0 "No_Error" 1 "Error" ;
VAL_ 277 ESP_WhlSpdVld_RF 0 "Initializing" 1 "Valid" 2 "Invalid" 3 "Reserved" ;
VAL_ 277 ESP_WhlMovgDir_RF 0 "Init" 1 "Forward" 2 "Backward" 3 "Stop" 4 "Invalid" 5 "Reserved" 6 "Reserved" 7 "Reserved" ;
VAL_ 277 ESP_WhlMovgDir_LF 0 "Init" 1 "Forward" 2 "Backward" 3 "Stop" 4 "Invalid" 5 "Reserved" 6 "Reserved" 7 "Reserved" ;
VAL_ 277 ESP_WhlSpdVld_LF 0 "Initializing" 1 "Valid" 2 "Invalid" 3 "Reserved" ;
VAL_ 278 ESP_WhlSpdVld_RR 0 "Initializing" 1 "Valid" 2 "Invalid" 3 "Reserved" ;
VAL_ 278 ESP_WhlMovgDir_RR 0 "Init" 1 "Forward" 2 "Backward" 3 "Stop" 4 "Invalid" 5 "Reserved" 6 "Reserved" 7 "Reserved" ;
VAL_ 278 ESP_WhlMovgDir_RL 0 "Init" 1 "Forward" 2 "Backward" 3 "Stop" 4 "Invalid" 5 "Reserved" 6 "Reserved" 7 "Reserved" ;
VAL_ 278 ESP_WhlSpdVld_RL 0 "Initializing" 1 "Valid" 2 "Invalid" 3 "Reserved" ;
VAL_ 279 ADAS_OTARdy_Fb 0 "Initial" 1 "Ready" 2 "Not_Ready" 3 "Invalid" ;
VAL_ 279 ADAS_OTAInhbRdy 0 "Initial" 1 "Inhibit" 2 "Not_Inhibit" 3 "Invalid" ;
VAL_ 279 ADAS_LgtCtrl_Sts 0 "Off" 1 "Reserved" 2 "Standby" 3 "Active" 4 "Fault" 5 "Dyno_Mode_On_(controller_inactive)" 6 "Workshop_Mode_On_(controller_inactive)" 7 "Reserved" ;
VAL_ 279 ADAS_LgtCtrl_StsVld 0 "Initializing" 1 "Valid" 2 "Invalid" 3 "Reserved" ;
VAL_ 279 ADAS_LgtCtrl_DrvrOvrdSts 0 "No_driver_overide" 1 "Driver_override_request" ;
VAL_ 279 ADAS_LgtCtrl_DrvrOvrdVld 0 "Initializing" 1 "Valid" 2 "Invalid" 3 "Reserved" ;
VAL_ 279 ADAS_HAP_EmgyStandstillVld 0 "Initializing" 1 "Valid" 2 "Invalid" 3 "Reserved" ;
VAL_ 279 ADAS_HAP_EmgyEPBVld 0 "Initializing" 1 "Valid" 2 "Invalid" 3 "Reserved" ;
VAL_ 279 ADAS_HAP_EmgyStandstillReq 0 "No_standstill_request" 1 "Standstill_request" ;
VAL_ 279 ADAS_ParkStandstillReq 0 "No_standstill_request" 1 "Standstill_request" ;
VAL_ 279 ADAS_ParkStandstillVld 0 "Initializing" 1 "Valid" 2 "Invalid" 3 "Reserved" ;
VAL_ 279 ADAS_ParkGearReq 0 "No_request" 1 "P" 2 "N" 3 "R" 4 "D" 5 "Reserved" 6 "E" 7 "S" 8 "Reserved" 9 "Reserved" 10 "Reserved" 11 "Reserved" 12 "Reserved" 13 "Reserved" 14 "Reserved" 15 "Reserved" ;
VAL_ 279 ADAS_ParkGearReqVld 0 "Initializing" 1 "Valid" 2 "Invalid" 3 "Reserved" ;
VAL_ 279 ADAS_ISA_CutOffReqVld 0 "Initializing" 1 "Valid" 2 "Invalid" 3 "Reserved" ;
VAL_ 279 ADAS_LgtCtrl_Typ 0 "Not_Active" 1 "ACC" 2 "ACC_Stop_and_Go" 3 "Intelligent_Speed_Assist" 4 "DRA" 5 "Cruise_Control" 6 "Full_Automatic_Park_Assist_System(APA)" 7 "Trained_Parking" 8 "Remote_Automated_Parking" 9 "Wheel_Scratch_Prevention_Park_Assist" 10 "Reserved" 11 "Reserved" 12 "Reserved" 13 "Reserved" 14 "Reserved" 15 "Reserved" ;
VAL_ 279 ADAS_HAP_EmgyEPBReq 0 "No_EPB_request" 1 "EPB_request" ;
VAL_ 279 ADAS_ISA_CutOffReq 0 "No_ISA_CutOff_request" 1 "ISA_CutOff_request" ;
VAL_ 280 ADAS_LgtCtrl_ESP_Sts 0 "Off" 1 "Reserved" 2 "Standby" 3 "Active" 4 "Fault" 5 "Dyno_Mode_On_(controller_inactive)" 6 "Workshop_Mode_On_(controller_inactive)" 7 "Reserved" ;
VAL_ 280 ADAS_LgtCtrl_ESP_Vld 0 "Initializing" 1 "Valid" 2 "Invalid" 3 "Reserved" ;
VAL_ 280 ADAS_ESP_DrvrOvrdSts 0 "No_driver_overide_" 1 "Driver_override_request" ;
VAL_ 280 ADAS_ESP_DrvrOvrdVld 0 "Initializing" 1 "Valid" 2 "Invalid" 3 "Reserved" ;
VAL_ 280 ADAS_HBAReq 0 "No_HBA_request" 1 "HBA_type_1" 2 "HBA_type_2" 3 "HBA_type_3" 4 "Reserved" 5 "Reserved" 6 "Reserved" 7 "Reserved" ;
VAL_ 280 ADAS_HBAVld 0 "Initializing" 1 "Valid" 2 "Invalid" 3 "Reserved" ;
VAL_ 280 ADAS_ESP_StandstillReq 0 "No_standstill_request" 1 "Standstill_request" ;
VAL_ 280 ADAS_ESP_StandstillVld 0 "Initializing" 1 "Valid" 2 "Invalid" 3 "Reserved" ;
VAL_ 280 ADAS_JerkReq 0 "No_jerk" 1 "Jerk_request" 2 "Reserved" 3 "Reserved" ;
VAL_ 280 ADAS_JerkReqVld 0 "Initializing" 1 "Valid" 2 "Invalid" 3 "Reserved" ;
VAL_ 280 ADAS_BrkPrefillReq 0 "No_brake_prefill" 1 "Brake_prefill_request" 2 "Reserved" 3 "Reserved" ;
VAL_ 280 ADAS_BrkPrefillVld 0 "Initializing" 1 "Valid" 2 "Invalid" 3 "Reserved" ;
VAL_ 280 ADAS_AEB_ActvTyp 0 "Not_Active" 1 "AEB_standard" 2 "AEB_VRU" 3 "LTAP_AEB" 4 "SCP_AEB" 5 "Rear_AEB" 6 "RCTB" 7 "Reserved" 8 "Reserved" 9 "Reserved" 10 "Reserved" 11 "Reserved" 12 "Reserved" 13 "Reserved" 14 "Reserved" 15 "Reserved" ;
VAL_ 280 ADAS_AEB_DecelVld 0 "Initializing" 1 "Valid" 2 "Invalid" 3 "Reserved" ;
VAL_ 288 ESP_ActvSig_ABS 0 "ABS_Standby" 1 "ABS_Actually_Operating" ;
VAL_ 288 ESP_MstCylPVld 0 "Initializing" 1 "Valid" 2 "Invalid" 3 "Reserved" ;
VAL_ 288 ESP_MstCylPOffsVld 0 "Initializing" 1 "Valid" 2 "Invalid" 3 "Reserved" ;
VAL_ 289 ADAS_LgtCtrl_AccelVld 0 "Initializing" 1 "Valid" 2 "Invalid" 3 "Reserved" ;
VAL_ 336 MCU_F_CrtTqVld 0 "Initializing" 1 "Valid" 2 "Invalid" 3 "Reserved" ;
VAL_ 336 MCU_F_CrtRotDir 0 "Standstill" 1 "Forward_rotation_(forward_mode)" 2 "Reverse_(reverse_mode)" 3 "Invalid" ;
VAL_ 336 MCU_F_CrtSpd 65535 "Invalid" ;
VAL_ 336 MCU_F_CrtTq 2047 "Invalid" ;
VAL_ 336 MCU_F_CrtSpdSigVld 0 "Initializing" 1 "Valid" 2 "Invalid" 3 "Reserved" ;
VAL_ 336 MCU_F_CrtMod 0 "Initialization_(function)" 1 "LV_ready" 2 "Standby" 3 "reserved" 4 "Torque_mode" 5 "Speed_control" 6 "reserved" 7 "Internal_inverter_error" 8 "reserved" 9 "Service_job" 10 "Postrun:" 11 "Sleep_Ready" 12 "Reserved" 13 "Reserved" 14 "Init_(dbc_init_value)" 15 "Invalid" ;
VAL_ 336 MCU_F_HVActvDchaSts 0 "Not_discharged" 1 "Discharging" 2 "Discharge_complete" 3 "Discharge_failure" 4 "Reserved" 5 "Reserved" 6 "Init_(dbc_init_value)" 7 "Invalid" ;
VAL_ 336 MCU_F_SlipCtrlActMode 0 "Slip_control_deactivated" 1 "Slip_control_idling" 2 "Slip_control_working" 3 "Fault" ;
VAL_ 336 MCU_F_AlrmLamp_FS 0 "Disable" 1 "Enable" ;
VAL_ 336 MCU_F_HVChkEndFlg 0 "Not_completed" 1 "Completed" ;
VAL_ 337 MCU_R_CrtTqVld 0 "Initializing" 1 "Valid" 2 "Invalid" 3 "Reserved" ;
VAL_ 337 MCU_R_CrtRotDir 0 "Standstill" 1 "Forward_rotation_(forward_mode)" 2 "Reverse_(reverse_mode)" 3 "Invalid" ;
VAL_ 337 MCU_R_CrtSpd 65535 "Invalid" ;
VAL_ 337 MCU_R_CrtTq 2047 "Invalid" ;
VAL_ 337 MCU_R_CrtSpdSigVld 0 "Initializing" 1 "Valid" 2 "Invalid" 3 "Reserved" ;
VAL_ 337 MCU_R_CrtMod 0 "Initialization_(function)" 1 "LV_ready" 2 "Standby" 3 "reserved" 4 "Torque_mode" 5 "Speed_control" 6 "reserved" 7 "Internal_inverter_error" 8 "reserved" 9 "Service_job" 10 "Postrun:" 11 "Sleep_Ready" 12 "Reserved" 13 "Reserved" 14 "Init_(dbc_init_value)" 15 "Invalid" ;
VAL_ 337 MCU_R_Decoup_State 0 "Init" 1 "Disconnect" 2 "Connect_in_progress" 3 "Synchronized" 4 "Connected" 5 "Disconnect_in_progress" 6 "Fault_disconnected" 7 "Fault_connected" 8 "Fault_connect_state_unknown" 9 "Connect_conditions_not_fulfilled" ;
VAL_ 337 MCU_R_HVActvDchaSts 0 "Not_discharged" 1 "Discharging" 2 "Discharge_complete" 3 "Discharge_failure" 4 "Reserved" 5 "Reserved" 6 "Init_(dbc_init_value)" 7 "Invalid" ;
VAL_ 337 MCU_R_SlipCtrlActMode 0 "Slip_control_deactivated" 1 "Slip_control_idling" 2 "Slip_control_working" 3 "Fault" ;
VAL_ 337 MCU_R_AlrmLamp_FS 0 "Disable" 1 "Enable" ;
VAL_ 337 MCU_R_HVChkEndFlg 0 "Not_completed" 1 "Completed" ;
VAL_ 345 ACU_Pass_OCS_St 0 "Seat_not_occupied" 1 "Seat_occupied" 2 "Fault" 3 "Invalid" ;
VAL_ 345 ACU_AirBagSysAlrmLampSts 0 "Warning_lamp_off" 1 "Warning_lamp_on" 2 "Warning_lamp_blinking" 3 "Invalid" ;
VAL_ 345 ACU_Pass_Airbag_LED 0 "LED_1_2_OFF/OFF" 1 "LED_1_2_ON/OFF" 2 "LED_1_2_OFF/ON" 3 "LED_1_2_ON/ON" 4 "LED_1_2_Blinking" 5 "not_used" 6 "not_used" 7 "Invalid" ;
VAL_ 345 ACU_Drvr_Occpt_St 0 "Seat_not_occupied" 1 "Seat_occupied" 2 "Fault" 3 "invalid" ;
VAL_ 345 ACU_BucSwtStFrntDrvr 0 "Buckled" 1 "Not_Buckled" 2 "Fault" 3 "Invalid" ;
VAL_ 345 ACU_BucSwtStFrntPass 0 "Buckled" 1 "Not_Buckled" 2 "Fault" 3 "Invalid" ;
VAL_ 345 ACU_SeatTrkPosnSwtFrntDrvr 0 "Seat_not_formost_position" 1 "Seat_formost_position" 2 "Fault" 3 "Invalid" ;
VAL_ 345 ACU_SeatTrkPosnSwtFrntPass 0 "Seat_not_formost_position" 1 "Seat_formost_position" 2 "Fault" 3 "Invalid" ;
VAL_ 448 ADAS_LatCtrl_Sts 0 "Inactive" 1 "Active" 2 "Degraded" 3 "Failure" 4 "Severe_Failure" 5 "Dyno_Mode_On_(controller_inactive)" 6 "Workshop_Mode_On_(controller_inactive)" 7 "Reserved" ;
VAL_ 448 ADAS_LatCtrl_StsVld 0 "Initializing" 1 "Valid" 2 "Invalid" 3 "Reserved" ;
VAL_ 448 ADAS_LatCtrl_DrvrOvrd 0 "No_override" 1 "driver_override" ;
VAL_ 448 ADAS_LatCtrl_DrvrOvrdVld 0 "Initializing" 1 "Valid" 2 "Invalid" 3 "Reserved" ;
VAL_ 448 ADAS_LatCtrl_Typ 0 "Not_active" 1 "LKA_angle_request" 2 "ELKA_angle_request" 3 "LCA_or_TJA_angle_request" 4 "ESA_angle_request" 5 "FAP_angle_request" 6 "TP_angle_request" 7 "RAP_angle_request" 8 "Reserved" 9 "Reserved" 10 "Reserved" 11 "Reserved" 12 "Reserved" 13 "Reserved" 14 "Reserved" 15 "Reserved" ;
VAL_ 448 ADAS_LatCtrl_ReqVld 0 "Not_valid" 1 "Steering_angle_request_valid" 2 "Reserved" 3 "Reserved" ;
VAL_ 448 ADAS_LatCtrl_Req 0 "Not_active" 1 "Angle_request_active" 2 "Reserved" 3 "Reserved" ;
VAL_ 450 EPS_AbortFb 0 "No_Abort" 1 "Driver_Interference_StrWhl" 2 "Reserved" 3 "Reserved" 4 "Reserved" 5 "Reserved" 6 "EPS_Internal_Failure" 7 "Vehilce_Speed_Exceeds_Limits_When_In_Control" 8 "CAN_communication_issue" 9 "Other_Abort_Reasons" 10 "Reserved" 11 "Reserved" 12 "Reserved" 13 "Reserved" 14 "Reserved" 15 "Reserved" ;
VAL_ 450 EPS_SteerWhlAgSig 65535 "Invalid" ;
VAL_ 450 EPS_SteerAgSnsrCalSts 0 "Uncalibrated" 1 "Calibrated" ;
VAL_ 450 EPS_SteerWhlAgSigVld 0 "Initializing" 1 "Valid" 2 "Invalid" 3 "Reserved" ;
VAL_ 450 EPS_SteerWhlRotSpdDir 0 "Forward_rotation" 1 "Negative_rotation" 2 "No_rotation" 3 "Reserved" ;
VAL_ 450 EPS_SteerWhlRotSpdVld 0 "Initializing" 1 "Valid" 2 "Invalid" 3 "Reserved" ;
VAL_ 450 EPS_SteerWhlRotSpd 4095 "Invalid" ;
VAL_ 450 EPS_AdasLatCtrlSts 0 "Off" 1 "Available_For_Control" 2 "Active" 3 "Failure" ;
VAL_ 450 EPS_AdasLatCtrlStsVld 0 "Initializing" 1 "Valid" 2 "Active" 3 "Reserved" ;
VAL_ 450 EPS_AsscMotCrtTq 255 "Invalid" ;
VAL_ 452 EPS_DrvrSteerTqDir 0 "Postive_counterclockwise" 1 "Negative_clockwise" 2 "No_direction" 3 "Invalid" ;
VAL_ 452 EPS_DrvrSteerTqVld 0 "Initializing" 1 "Valid" 2 "Invalid" 3 "Reserved" ;
VAL_ 452 EPS_DrvrSteerTq 4095 "Invalid" ;
VAL_ 452 EPS_OTARdy_Fb 0 "Initial" 1 "Ready" 2 "Not_Ready" 3 "Invalid" ;
VAL_ 452 EPS_DrvrIntvSteerWhlDetd 0 "False_Unintervened" 1 "True_intervention" ;
VAL_ 452 EPS_DrvrIntvSteerWhlVld 0 "Initializing" 1 "Valid" 2 "Invalid" 3 "Reserved" ;
VAL_ 452 EPS_SteerSnsrSts 0 "Not_Failure" 1 "Failure" ;
VAL_ 452 EPS_PinionAg 65534 "Initializing" 65535 "Invalid" ;
VAL_ 522 ADAS_LeLine2LnTyp 0 "Unknown" 1 "SingleLine_Solid" 2 "SingleLine_dashed" 3 "SingleLine_BottsDots" 4 "DoubleLine_Solid_Dashed" 5 "DoubleLine_Dash_Dash" 6 "DoubleLine_Dash_Solid" 7 "DoubleLine_Solid_Solid" 8 "Road_Edge" 9 "Reserved" 10 "Reserved" 11 "Reserved" 12 "Reserved" 13 "Reserved" 14 "Reserved" 15 "Reserved" ;
VAL_ 522 ADAS_LeLine2LnColor 0 "Gray" 1 "White" 2 "Blue(ALC)" 3 "Invalid" ;
VAL_ 522 ADAS_LeLine2Crvt 63 "Straight_Lane" 127 "No_Display" ;
VAL_ 522 ADAS_LeLine2Conf 0 "12_5_percent" 1 "25_percent" 2 "37_5_percent" 3 "50_percent" 4 "62_5_percent" 5 "75_percent" 6 "87_5_percent" 7 "100_percent" ;
VAL_ 523 ADAS_LeLine3LnTyp 0 "Unknown" 1 "SingleLine_Solid" 2 "SingleLine_dashed" 3 "SingleLine_BottsDots" 4 "DoubleLine_Solid_Dashed" 5 "DoubleLine_Dash_Dash" 6 "DoubleLine_Dash_Solid" 7 "DoubleLine_Solid_Solid" 8 "Road_Edge" 9 "Reserved" 10 "Reserved" 11 "Reserved" 12 "Reserved" 13 "Reserved" 14 "Reserved" 15 "Reserved" ;
VAL_ 523 ADAS_LeLine3LnColor 0 "Gray" 1 "White" 2 "Blue(ALC)" 3 "Invalid" ;
VAL_ 523 ADAS_LeLine3Crvt 63 "Straight_Lane" 127 "No_Display" ;
VAL_ 523 ADAS_LeLine3Conf 0 "12_5_percent" 1 "25_percent" 2 "37_5_percent" 3 "50_percent" 4 "62_5_percent" 5 "75_percent" 6 "87_5_percent" 7 "100_percent" ;
VAL_ 524 ADAS_RiLine1LnTyp 0 "Unknown" 1 "SingleLine_Solid" 2 "SingleLine_dashed" 3 "SingleLine_BottsDots" 4 "DoubleLine_Solid_Dashed" 5 "DoubleLine_Dash_Dash" 6 "DoubleLine_Dash_Solid" 7 "DoubleLine_Solid_Solid" 8 "Road_Edge" 9 "Reserved" 10 "Reserved" 11 "Reserved" 12 "Reserved" 13 "Reserved" 14 "Reserved" 15 "Reserved" ;
VAL_ 524 ADAS_RiLine1LnColor 0 "Gray" 1 "White" 2 "Blue(ALC)" 3 "Invalid" ;
VAL_ 524 ADAS_RiLine1Crvt 63 "Straight_Lane" 127 "No_Display" ;
VAL_ 524 ADAS_RiLine1Conf 0 "12_5_percent" 1 "25_percent" 2 "37_5_percent" 3 "50_percent" 4 "62_5_percent" 5 "75_percent" 6 "87_5_percent" 7 "100_percent" ;
VAL_ 525 ADAS_RiLine2LnTyp 0 "Unknown" 1 "SingleLine_Solid" 2 "SingleLine_dashed" 3 "SingleLine_BottsDots" 4 "DoubleLine_Solid_Dashed" 5 "DoubleLine_Dash_Dash" 6 "DoubleLine_Dash_Solid" 7 "DoubleLine_Solid_Solid" 8 "Road_Edge" 9 "Reserved" 10 "Reserved" 11 "Reserved" 12 "Reserved" 13 "Reserved" 14 "Reserved" 15 "Reserved" ;
VAL_ 525 ADAS_RiLine2LnColor 0 "Gray" 1 "White" 2 "Blue(ALC)" 3 "Invalid" ;
VAL_ 525 ADAS_RiLine2Crvt 63 "Straight_Lane" 127 "No_Display" ;
VAL_ 525 ADAS_RiLine2Conf 0 "12_5_percent" 1 "25_percent" 2 "37_5_percent" 3 "50_percent" 4 "62_5_percent" 5 "75_percent" 6 "87_5_percent" 7 "100_percent" ;
VAL_ 526 ADAS_RiLine3LnTyp 0 "Unknown" 1 "SingleLine_Solid" 2 "SingleLine_dashed" 3 "SingleLine_BottsDots" 4 "DoubleLine_Solid_Dashed" 5 "DoubleLine_Dash_Dash" 6 "DoubleLine_Dash_Solid" 7 "DoubleLine_Solid_Solid" 8 "Road_Edge" 9 "Reserved" 10 "Reserved" 11 "Reserved" 12 "Reserved" 13 "Reserved" 14 "Reserved" 15 "Reserved" ;
VAL_ 526 ADAS_RiLine3LnColor 0 "Gray" 1 "White" 2 "Blue(ALC)" 3 "Invalid" ;
VAL_ 526 ADAS_RiLine3Crvt 63 "Straight_Lane" 127 "No_Display" ;
VAL_ 526 ADAS_RiLine3Conf 0 "12_5_percent" 1 "25_percent" 2 "37_5_percent" 3 "50_percent" 4 "62_5_percent" 5 "75_percent" 6 "87_5_percent" 7 "100_percent" ;
VAL_ 527 ADAS_RealLaneWidth 63 "Invalid" ;
VAL_ 527 ADAS_EgoDecelLane 0 "TRUE" 1 "FALSE" ;
VAL_ 527 ADAS_EgoCarpoolLane 0 "TRUE" 1 "FALSE" ;
VAL_ 527 ADAS_EgoLnTyp 0 "Through_Lane" 1 "Passing_Lane" 2 "Acceleration_Lane" 3 "Deceleration_Lane" 4 "Merging_Lane" 5 "Carpool_Lane" 6 "not_used" 7 "Bike_Lane" 8 "Left_Turn_Lane" 9 "Right_Turn_Lane" 10 "Fire_Lane" 11 "Road_edge" 12 "Barrier" 13 "Exit" 14 "Reserved" 15 "Reserved" ;
VAL_ 527 ADAS_LeLn1Typ 0 "Through_Lane" 1 "Passing_Lane" 2 "Acceleration_Lane" 3 "Deceleration_Lane" 4 "Merging_Lane" 5 "Carpool_Lane" 6 "Through_Lane" 7 "Bike_Lane" 8 "Left_Turn_Lane" 9 "Right_Turn_Lane" 10 "Fire_Lane" 11 "Road_edge" 12 "Barrier" 13 "Exit" 14 "Reserved" 15 "Reserved" ;
VAL_ 527 ADAS_LeLn2Typ 0 "Through_Lane" 1 "Passing_Lane" 2 "Acceleration_Lane" 3 "Deceleration_Lane" 4 "Merging_Lane" 5 "Carpool_Lane" 6 "Through_Lane" 7 "Bike_Lane" 8 "Left_Turn_Lane" 9 "Right_Turn_Lane" 10 "Fire_Lane" 11 "Road_edge" 12 "Barrier" 13 "Exit" 14 "Reserved" 15 "Reserved" ;
VAL_ 527 ADAS_RiLn1Typ 0 "Through_Lane" 1 "Passing_Lane" 2 "Acceleration_Lane" 3 "Deceleration_Lane" 4 "Merging_Lane" 5 "Carpool_Lane" 6 "Through_Lane" 7 "Bike_Lane" 8 "Left_Turn_Lane" 9 "Right_Turn_Lane" 10 "Fire_Lane" 11 "Road_edge" 12 "Barrier" 13 "Exit" 14 "Reserved" 15 "Reserved" ;
VAL_ 527 ADAS_RiLn2Typ 0 "Through_Lane" 1 "Passing_Lane" 2 "Acceleration_Lane" 3 "Deceleration_Lane" 4 "Merging_Lane" 5 "Carpool_Lane" 6 "Through_Lane" 7 "Bike_Lane" 8 "Left_Turn_Lane" 9 "Right_Turn_Lane" 10 "Fire_Lane" 11 "Road_edge" 12 "Barrier" 13 "Exit" 14 "Reserved" 15 "Reserved" ;
VAL_ 528 ADAS_TLR_EgoLaneTyp 0 "No_light_detected" 1 "Traffic_light_Circle_shape" 2 "Left_Arrow" 3 "Right_Arrow" 4 "Reserved" 5 "Reserved" 6 "Reserved" 7 "Unkown" ;
VAL_ 528 ADAS_TLR_EgoLaneSts 0 "No_light_detected" 1 "Off" 2 "On_or_Solid" 3 "Blinking" 4 "Reserved" 5 "Reserved" 6 "Reserved" 7 "Unkown" ;
VAL_ 528 ADAS_WSP_LeftCurb 0 "No_Detection" 1 "Front_Left_Curb_detection" 2 "Rear_Left_Curb_detection" 3 "Front/Rear_Left_Curb_detection" ;
VAL_ 528 ADAS_TLR_EgoLaneColor 0 "No_light_detected" 1 "Red" 2 "Amber" 3 "Green" 4 "Red_Orange" 5 "Red_With_Supp_green" 6 "Orange_with_Supp_green" 7 "Red_with_Supp_Orange" 8 "Unknown" 9 "Reserved" 10 "Reserved" 11 "Reserved" 12 "Reserved" 13 "Reserved" 14 "Reserved" 15 "Reserved" ;
VAL_ 528 ADAS_TrafficLightShape 0 "No_light_detected" 1 "Red" 2 "Amber" 3 "Green" 4 "Reserved" 5 "Reserved" 6 "Reserved" 7 "Unkown" ;
VAL_ 528 ADAS_TSRPassingCondition 0 "Overtaking_allowed" 1 "No_Overtaking_allowed" ;
VAL_ 528 ADAS_TLR_WarnReq 0 "No_TLR_Alert" 1 "TLR_Red_Light_Warning" 2 "TLR_Green_Light_Reminder" 3 "Reserved" 4 "Reserved" 5 "Reserved" 6 "Reserved" 7 "Reserved" ;
VAL_ 528 ADAS_WSP_RightCurb 0 "No_Detection" 1 "Front_Right_Curb_detection" 2 "Rear_Right_Curb_detection" 3 "Front/Rear_Right_Curb_detection" ;
VAL_ 528 ADAS_ISAWarnReq 0 "No_Warning" 1 "Visual_Warning" ;
VAL_ 528 ADAS_TLRStructOrient 0 "No_Structure_Detected" 1 "Vertical" 2 "Horizontal" 3 "Reserved" 4 "Reserved" 5 "Reserved" 6 "Reserved" 7 "Unknown" ;
VAL_ 528 ADAS_TLRNumSpots 0 "No_light_Detected" 1 "1_Light" 2 "2_lights" 3 "3_Lights" 4 "4_Lights" 5 "5_Lights" 6 "Reserved" 7 "Unknown" ;
VAL_ 528 ADAS_ISAOverSpeedWarning 0 "No_warning" 1 "Warning_stage_1" 2 "Warning_stage_2" 3 "Warning_stage_3" 4 "Warning_stage_4" 5 "Reserved" 6 "Reserved" 7 "Reserved" 8 "Reserved" 9 "Reserved" 10 "Reserved" 11 "Reserved" 12 "Reserved" 13 "Reserved" 14 "Reserved" 15 "Reserved" ;
VAL_ 528 ADAS_TSRSignCondition 0 "Unknown" 1 "None" 2 "Generic" 3 "Rain" 4 "Snow" 5 "Snow-Rain" 6 "Rain-Cloud" 7 "Fog" 8 "Time" 9 "Wet_conditions" 10 "Trailer" 11 "Arrow_Left" 12 "Arrow_Right" 13 "Distance_Arrow" 14 "School" 15 "Where_Workers_Present" 16 "End_of_Speed_Limit" 17 "School_when_flashing" 18 "Ice" 31 "Invalid" ;
VAL_ 528 ADAS_TSRSpdLimConfidenceLvl 0 "No_request" 1 "High_level_of_confidence" 2 "Medium_level_of_confidence" 3 "Low_level_of_confidence" ;
VAL_ 532 VCU_RdyLamp 0 "Not_ready" 1 "Ready" ;
VAL_ 532 VCU_BrkLampCtrlSts 0 "No_request" 1 "lighting_request" ;
VAL_ 532 VCU_RemWakeUpEndFlg 0 "remote_control_not_ended" 1 "remote_control_ended" ;
VAL_ 532 VCU_StgyGearSig 0 "Undefined_initial_value" 1 "gear_P" 2 "gear_N" 3 "R_gear" 4 "gear_D" 5 "Reserved" 6 "gear_E" 7 "gear_S" 8 "Reserved" 9 "Reserved" 10 "Reserved" 11 "Reserved" 12 "Reserved" 13 "Reserved" 14 "Reserved" 15 "Reserved" ;
VAL_ 532 VCU_ShiftMisoper 0 "Normal" 1 "Abnormal" ;
VAL_ 532 VCU_GearSigVld 0 "Initializing" 1 "Valid" 2 "Invalid" 3 "Reserved" ;
VAL_ 532 VCU_GearSig 0 "Undefined_initial_value" 1 "gear_P" 2 "gear_N" 3 "R_gear" 4 "D_gear" 5 "Reserved" 6 "gear_E" 7 "gear_S" 8 "Reserved" 9 "Reserved" 10 "Reserved" 11 "Reserved" 12 "Reserved" 13 "Reserved" 14 "Reserved" 15 "Reserved" ;
VAL_ 532 VCU_ACCRdy 0 "Not_ready" 1 "Ready" ;
VAL_ 532 VCU_ParkRdy 0 "Not_ready" 1 "Ready" ;
VAL_ 532 VCU_APSPercVld 0 "Initializing" 1 "Valid" 2 "Invalid" 3 "Reserved" ;
VAL_ 532 VCU_VehSt 0 "VCUSleep" 1 "WakeUp" 2 "Init/StartUp" 3 "Standby" 4 "Driving" 5 "Charging" 6 "PostConditioning" 7 "HV_Active_Discharge" 8 "Afterrun" 9 "EmgcyOff" 10 "EmgcyOff_ADisch" 11 "Safestate" 65535 "Invalid" ;
VAL_ 532 VCU_BrkSig 0 "brake_pedal_not_pressed" 1 "Brake_pedal_depressed" ;
VAL_ 532 VCU_BrkSigVld 0 "Initializing" 1 "Valid" 2 "Invalid" 3 "Reserved" ;
VAL_ 532 VCU_DrvModSigFb 0 "Eco" 1 "Normal" 2 "Sport" 3 "Custom" 4 "Snow" 5 "Offroad" 6 "Valet" 7 "Invalid" ;
VAL_ 532 VCU_DrvModShiftMisoper 0 "Normal" 1 "Abnormal" ;
VAL_ 532 VCU_SpclTerrainModEnaSig 0 "Not_enabled" 1 "Enable" ;
VAL_ 537 VCU_PreCdtFB 0 "No_request" 1 "In_progress" 2 "Successful" 3 "Failed" ;
VAL_ 537 VCU_IMMO_Sts 0 "Immo_Active" 1 "Immo_Inactive" 2 "Reserved" 3 "Invalid" ;
VAL_ 537 VCU_RemCtrlDrvgSts 0 "Standby" 1 "Moving_forward" 2 "Backward" 3 "Left_turn_in" 4 "Middle_right_turn" 5 "Invalid" 6 "Invalid" 7 "Invalid" ;
VAL_ 537 VCU_TioutPwrOffReq 0 "No_request" 1 "With_request" ;
VAL_ 537 VCU_RemCtrlDrvgEnaFlg 0 "Not_enabled" 1 "Enable" ;
VAL_ 537 VCU_RemCtrlDrvgEnaFlgVld 0 "Initializing" 1 "Valid" 2 "Invalid" 3 "Reserved" ;
VAL_ 537 VCU_RemCtrlDrvgPwrOnReq 0 "Initialization" 1 "No_demand" 2 "On_demand" 3 "Reversed" ;
VAL_ 537 VCU_RemCtrlDrvgExitFlg 0 "Valid" 1 "Invalid" ;
VAL_ 537 VCU_RemCtrlDrvgRelsReq 0 "No_Request_No_Request" 1 "Request_request" ;
VAL_ 537 VCU_RemCtrlDrvgExitDisp 0 "Initial_value" 1 "Please_check_vehicle_status" 2 "Key_in_the_vehicle" 3 "vehicle_is_operating" 4 "Poor_pavement" 5 "Too_large_slope" 6 "Maximum_driving_distance_reached" 7 "Maximum_remote_time_reached" 8 "Obstacle_detected" 9 "wait_timeout" 10 "System_fault" 11 "Reserved" 12 "Reserved" 13 "Reserved" 14 "Reserved" 15 "Reserved" ;
VAL_ 537 VCU_RemCtrlDrvgBrkReq 0 "No_Request_No_Request" 1 "Request_request" ;
VAL_ 537 VCU_RemCtrlDrvgEmgyBrkReq 0 "No_Request_No_Request" 1 "Request_request" ;
VAL_ 537 VCU_RemCtrlDrvgModClsReq_VLC 0 "No_Request" 1 "Soft_Off" 2 "Fast_Off" 3 "Immediate_Off" ;
VAL_ 537 VCU_DrvrIntvGearSigVld 0 "Initializing" 1 "Valid" 2 "Invalid" 3 "Reserved" ;
VAL_ 537 VCU_DrvrIntvGearSig 0 "False_Unintervened" 1 "True_intervention" ;
VAL_ 537 VCU_GearUnderCtrlSts 0 "Inhibit" 1 "Available_For_Control" 2 "Active_For_Control" 3 "Failed" 4 "Reserved" 5 "Reserved" 6 "Reserved" 7 "Reserved" ;
VAL_ 537 VCU_PrefillReq 0 "Idle" 1 "Prefill" ;
VAL_ 537 VCU_VehSecureHold 0 "None" 1 "Vehicle_Secure" ;
VAL_ 537 VCU_VehSecureRels 0 "None" 1 "Vehicle_Secure_Release" ;
VAL_ 537 VCU_AxReqActv 0 "No_Request" 1 "Request" 2 "Active" 3 "ACC_driver_override" ;
VAL_ 537 VCU_SpclTerrainModReq 0 "Initializing" 1 "Normal_request" 2 "Snow_request" 3 "Mud_request" 4 "Sand_request" 5 "Reserved" 6 "Reserved" 7 "Reserved" ;
VAL_ 711 ADAS_APASlot5Typ 0 "Parallel" 1 "Perpendicular" 2 "Fish_bone" 3 "Reserved" ;
VAL_ 711 ADAS_APASlot5Sid 0 "Left" 1 "Right" ;
VAL_ 711 ADAS_APASlot5Sts 0 "Open" 1 "Occupied" ;
VAL_ 717 ADAS_APASlotSelTyp 0 "Parallel" 1 "Perpendicular" 2 "Fish_bone" 3 "Reserved" ;
VAL_ 717 ADAS_APASlotSelSid 0 "Left" 1 "Right" ;
VAL_ 717 ADAS_APASlotSelSts 0 "Open" 1 "Occupied" ;
VAL_ 717 ADAS_APAAvailable 0 "Not_available" 1 "Park_in_available" 2 "Park_out_available" 3 "Reserved" ;
VAL_ 717 ADAS_APAScanngSde 0 "Not_scanning" 1 "Left" 2 "Right" 3 "Both" ;
VAL_ 717 ADAS_CurbPrtcRrLeWhl 0 "Not_warning" 1 "Warning" ;
VAL_ 717 ADAS_CurbPrtcRrRiWhl 0 "Not_warning" 1 "Warning" ;
VAL_ 717 ADAS_CurbPrtcFrLeWhl 0 "Not_warning" 1 "Warning" ;
VAL_ 717 ADAS_CurbPrtcFrRiWhl 0 "Not_warning" 1 "Warning" ;
VAL_ 717 ADAS_APASpdWarn 0 "Vehicle_speed_not_exceeded" 1 "Vehicle_speed_exceeded" ;
VAL_ 723 ADAS_APASlot1Typ 0 "Parallel" 1 "Perpendicular" 2 "Fish_bone" 3 "Reserved" ;
VAL_ 723 ADAS_APASlot1Sid 0 "Left" 1 "Right" ;
VAL_ 723 ADAS_APASlot1Sts 0 "Open" 1 "Occupied" ;
VAL_ 729 ADAS_APASlot2Typ 0 "Parallel" 1 "Perpendicular" 2 "Fish_bone" 3 "Reserved" ;
VAL_ 729 ADAS_APASlot2Sid 0 "Left" 1 "Right" ;
VAL_ 729 ADAS_APASlot2Sts 0 "Open" 1 "Occupied" ;
VAL_ 735 ADAS_APASlot3Typ 0 "Parallel" 1 "Perpendicular" 2 "Fish_bone" 3 "Reserved" ;
VAL_ 735 ADAS_APASlot3Sid 0 "Left" 1 "Right" ;
VAL_ 735 ADAS_APASlot3Sts 0 "Open" 1 "Occupied" ;
VAL_ 741 ADAS_APASlot4Typ 0 "Parallel" 1 "Perpendicular" 2 "Fish_bone" 3 "Reserved" ;
VAL_ 741 ADAS_APASlot4Sid 0 "Left" 1 "Right" ;
VAL_ 741 ADAS_APASlot4Sts 0 "Open" 1 "Occupied" ;
VAL_ 746 ADAS_APASlot6Sid 0 "Left" 1 "Right" ;
VAL_ 746 ADAS_APASlot6Sts 0 "Open" 1 "Occupied" ;
VAL_ 746 ADAS_APASlot6Typ 0 "Parallel" 1 "Perpendicular" 2 "Fish_bone" 3 "Reserved" ;
VAL_ 785 ADAS_HiPrioDegradationSts 0 "No_high_priority_popup_requested" 1 "All_ADAS_features_offline" 2 "ACC_is_being_disabled,_driver_take_control_" 3 "Driver_assist_(ACC_with_LCC)_being_disabled,_Driver_take_control" 4 "Traffic_Jam_Assist_being_disabled,_Driver_take_control" 5 "All_front_AEB_support_is_disabled" 6 "All_rear_AEB_support_is_disabled" 7 "Autopark_operations_being_disabled,_driver_take_control" 8 "Park_Assist_Support_disabled" 9 "Front_Cross_Path_Braking_disabled" 10 "Rear_Cross_Path_Braking_disabled" 11 "Emergency_Steering_Assist_is_disabled" 12 "Reserved" 13 "Reserved" 14 "Reserved" 15 "Reserved" 16 "Reserved" 17 "Reserved" 18 "Reserved" 19 "Reserved" 20 "Reserved" 21 "Reserved" 22 "Reserved" 23 "Reserved" 24 "Reserved" 25 "Reserved" 26 "Reserved" 27 "Reserved" 28 "Reserved" 29 "Reserved" 30 "Reserved" 31 "Reserved" 32 "Reserved" 33 "Reserved" 34 "Reserved" 35 "Reserved" 36 "Reserved" 37 "Reserved" 38 "Reserved" 39 "Reserved" 40 "Reserved" 41 "Reserved" 42 "Reserved" 43 "Reserved" 44 "Reserved" 45 "Reserved" 46 "Reserved" 47 "Reserved" 48 "Reserved" 49 "Reserved" 50 "Reserved" 51 "Reserved" 52 "Reserved" 53 "Reserved" 54 "Reserved" 55 "Reserved" 56 "Reserved" 57 "Reserved" 58 "Reserved" 59 "Reserved" 60 "Reserved" 61 "Reserved" 62 "Reserved" 63 "Reserved" ;
VAL_ 785 ADAS_ISA_PerSpdLim_req 0 "No_Percieved_Speed_Limit_change_notification_request" 1 "Percieved_Speed_Limit_change_notification_request" ;
VAL_ 785 ADAS_LoPrioDegradationSts 0 "No_low_priority_popup_requested" 1 "Blind_Spot_monitoring_is_offline" 2 "Collision_warning_disabled" 3 "Lane_departure_warning_disabled" 4 "Front_Cross_path_warning_disabled" 5 "Rear_Cross_Path_warning_disabled" 6 "Park_Assist_warnings_disabled" 7 "Door_Opening_Warning_disabled" 8 "Wheel_Scratch_Prevention_disabled" 9 "DCAA_disabled" 10 "Reserved" 11 "Reserved" 12 "Reserved" 13 "Reserved" 14 "Reserved" 15 "Reserved" 16 "Reserved" 17 "Reserved" 18 "Reserved" 19 "Reserved" 20 "Reserved" 21 "Reserved" 22 "Reserved" 23 "Reserved" 24 "Reserved" 25 "Reserved" 26 "Reserved" 27 "Reserved" 28 "Reserved" 29 "Reserved" 30 "Reserved" 31 "Reserved" 32 "Reserved" 33 "Reserved" 34 "Reserved" 35 "Reserved" 36 "Reserved" 37 "Reserved" 38 "Reserved" 39 "Reserved" 40 "Reserved" 41 "Reserved" 42 "Reserved" 43 "Reserved" 44 "Reserved" 45 "Reserved" 46 "Reserved" 47 "Reserved" 48 "Reserved" 49 "Reserved" 50 "Reserved" 51 "Reserved" 52 "Reserved" 53 "Reserved" 54 "Reserved" 55 "Reserved" 56 "Reserved" 57 "Reserved" 58 "Reserved" 59 "Reserved" 60 "Reserved" 61 "Reserved" 62 "Reserved" 63 "Reserved" ;
VAL_ 785 ADAS_SpeedLimitUnit 0 "KPH" 1 "MPH" ;
VAL_ 787 ADAS_FACM_Sts 0 "UaCMX" 1 "DsblCMX" 2 "StdbyCMX" 3 "StdbyDgrdCMX" 4 "ActvCMX" 5 "ActvDgrdCMX" 6 "ErrCMX" 7 "ActvDgrd1CMX" 8 "ActvDgrd2CMX" 9 "DsblDgrdCMX" 10 "Reserved" 11 "Reserved" 12 "Reserved" 13 "Reserved" 14 "Reserved" 15 "Reserved" ;
VAL_ 787 ADAS_BACM_Sts 0 "UaCMX" 1 "DsblCMX" 2 "StdbyCMX" 3 "StdbyDgrdCMX" 4 "ActvCMX" 5 "ActvDgrdCMX" 6 "ErrCMX" 7 "ActvDgrd1CMX" 8 "ActvDgrd2CMX" 9 "DsblDgrdCMX" 10 "Reserved" 11 "Reserved" 12 "Reserved" 13 "Reserved" 14 "Reserved" 15 "Reserved" ;
VAL_ 787 AEB_ReAEB_Sts 0 "UaCMX" 1 "DsblCMX" 2 "StdbyCMX" 3 "StdbyDgrdCMX" 4 "ActvCMX" 5 "ActvDgrdCMX" 6 "ErrCMX" 7 "ActvDgrd1CMX" 8 "ActvDgrd2CMX" 9 "DsblDgrdCMX" 10 "Reserved" 11 "Reserved" 12 "Reserved" 13 "Reserved" 14 "Reserved" 15 "Reserved" ;
VAL_ 787 ADAS_Sts_ACC_ICC 0 "ACC_Off" 1 "Initialization" 2 "Standby" 3 "Active" 4 "Override" 5 "Standstill_active" 6 "Standstill_wait" 7 "Deactivation_brake" 8 "Deactivation_other" 9 "Failure_reversible" 10 "Failure_irreversible" 11 "Standstill_GoNotification" 12 "Reserved" 13 "Reserved" 14 "Reserved" 15 "Reserved" ;
VAL_ 787 ADAS_TJA_AutoSteerSts 0 "Off_Unavailable" 1 "Off_Available" 2 "On_Standby" 3 "Active_lane_following" 4 "Active_object_following" 5 "Driver_override" 6 "Fault" 7 "Reserved" ;
VAL_ 787 ADAS_ISASts 0 "Off" 1 "Available" 2 "Active" 3 "Error" ;
VAL_ 787 ADAS_Sts_TLR 0 "Off" 1 "Available" 2 "Active" 3 "Error" ;
VAL_ 787 ADAS_TSRSts 0 "Reserved" 1 "Off" 2 "Fusion_Mode" 3 "Vision_Mode" 4 "Navigation_Mode" 5 "Error" 6 "Reserved" 7 "Reserved" ;
VAL_ 788 ADAS_ESAState 0 "ESA_OffCoded" 1 "ESA_Off" 2 "Inactve" 3 "ESA_Actv_RequestTpfLT" 4 "ESA_Actv_RequestTpfRT" 5 "Actv_SteeringLT" 6 "Actv_SteeringRT" 7 "ESA_RampoutLe" 8 "ESA_RampoutRi" 9 "ESA_Error" 10 "Unavailable" 11 "Reserved" 12 "Reserved" 13 "Reserved" 14 "Reserved" 15 "Reserved" ;
VAL_ 788 ADAS_LKASts 0 "LKA_OffCoded" 1 "LKA_Off" 2 "Inactve" 3 "ReadyToAssist" 4 "LKA_WarningLT" 5 "LKA_WarningRT" 6 "Actv_SteeringLT" 7 "Actv_SteeringRT" 8 "LKA_Error" 9 "Reserved" 10 "Reserved" 11 "Reserved" 12 "Reserved" 13 "Reserved" 14 "Reserved" 15 "Reserved" ;
VAL_ 788 ADAS_ELKASts 0 "ELKA_OffCoded" 1 "LKA_Off" 2 "Inactve" 3 "ReadyToAssist" 4 "ELKA_WarningLT" 5 "ELKA_WarningRT" 6 "Actv_SteeringLT" 7 "Actv_SteeringRT" 8 "ELKA_Error" 9 "Reserved" 10 "Reserved" 11 "Reserved" 12 "Reserved" 13 "Reserved" 14 "Reserved" 15 "Reserved" ;
VAL_ 788 ADAS_LCA_Sts 0 "Off" 1 "Standby" 2 "Prepare_to_left_lane" 3 "Prepare_to_right_lane" 4 "Active_to_left" 5 "Active_to_right" 6 "Return" 7 "Error" 8 "Reserved" 9 "Reserved" 10 "Reserved" 11 "Reserved" 12 "Reserved" 13 "Reserved" 14 "Reserved" 15 "Reserved" ;
VAL_ 788 ADAS_LCA_Maneuver_Status 0 "No_Suppressed" 1 "LCA_Suppressed" ;
VAL_ 788 ADAS_APASts 0 "Off" 1 "Initialize" 2 "Standby" 3 "Scanning" 4 "Slot_selected" 5 "Park_In" 6 "Park_Out" 7 "Aborted" 8 "Parking_complete" 9 "Fault" 10 "Park_Out_ready" 11 "Reserved" 12 "Reserved" 13 "Reserved" 14 "Reserved" 15 "Reserved" ;
VAL_ 788 ADAS_WSPPASts 0 "Off" 1 "On_standby" 2 "On_available" 3 "On_active" 4 "Off_fault" 5 "Reserved" 6 "Reserved" 7 "Reserved" ;
VAL_ 788 ADAS_DOW_Sts 0 "Off" 1 "On_standby" 2 "On_available" 3 "On_active" 4 "Off_fault" 5 "Reserved" 6 "Reserved" 7 "Reserved" ;
VAL_ 788 ADAS_BSDSts 0 "Off" 1 "On_standby" 2 "On_available" 3 "On_active" 4 "Error" 5 "Reserved" 6 "Reserved" 7 "Reserved" ;
VAL_ 788 ADAS_DCAASts 0 "Off" 1 "On_(Standby)" 2 "On_(available)" 3 "On_(active)" 4 "Off_(Fault)" 5 "Reserved" 6 "Reserved" 7 "Reserved" ;
VAL_ 788 ADAS_AHBA_Sts 0 "Off" 1 "On" 2 "Fault" 3 "Reserved" ;
VAL_ 788 ADAS_AHBA_BeamDecisRsn 0 "Default" 1 "Low_speed" 2 "Oncoming" 3 "Preceding" 4 "Reflector" 5 "Illuminated_area" 6 "Failsafe" 7 "LitNight" 8 "Guardrail" 9 "BlinkingTrffcLi" 10 "Junction" 11 "Reserved" 12 "EgoTurning" ;
VAL_ 789 ADAS_DOW_CID_LeDispReq 0 "Display_No_threat_both_door_closed" 1 "Display_threat_both_door_closed" 2 "Display_threat_front_door_open" 3 "Display_threat_rear_door_open" 4 "Display_threat_both_door_open" 5 "Display_no_threat_front_door_open" 6 "Display_no_threat_rear_door_open" 7 "Display_no_threat_both_door_open" ;
VAL_ 789 ADAS_DOW_CID_RiDispReq 0 "No_threat_both_door_closed" 1 "Display_threat_both_door_closed" 2 "Display_threat_front_door_open" 3 "Display_threat_rear_door_open" 4 "Display_threat_both_door_open" 5 "Display_no_threat_front_door_open" 6 "Display_no_threat_rear_door_open" 7 "Display_no_threat_both_door_open" ;
VAL_ 789 ADAS_BSD_CID_LeDispReq 0 "No_threat" 1 "Threat_present_on_left" 2 "Threat_present_on_left_and_turn_indicator_left_on" 3 "Critical_threat_present_on_left" 4 "Error" 5 "Reserved" 6 "Reserved" 7 "Reserved" ;
VAL_ 789 ADAS_BSD_CID_RiDispReq 0 "No_threat" 1 "Threat_present_on_right" 2 "Threat_present_on_right_and_turn_indicator_right_on" 3 "Critical_threat_present_on_right" 4 "Error" 5 "Reserved" 6 "Reserved" 7 "Reserved" ;
VAL_ 789 ADAS_DCAA_WarnLvlReq 0 "Off" 1 "On_Standby" 2 "Drowsy_level_1" 4 "Drowsy_level_2" 5 "Drowsy_level_3" 6 "Distraction_level_1" 7 "Distraction_level_2" 8 "Distraction_level_3" 9 "Reserved" 10 "Reserved" 11 "Reserved" 12 "Reserved" 13 "Reserved" 14 "Reserved" 15 "Reserved" ;
VAL_ 789 ADAS_DCAA_GazeOnWarnReq 0 "No_gaze_on_warning_request" 1 "Gaze_on_warning_request" ;
VAL_ 790 ADASDC_SVS_ViewSts 0 "None" 1 "Front_Normal_View" 2 "Left_Flank_3D_view" 3 "Right_Flank_3D_View" 4 "Rear_Normal_View" 5 "Curb_View" 6 "Front_Cross_Path_View" 7 "Rear_Cross_Path_View" 8 "360_Degree_Free_Floating_View" 9 "Reserved" 10 "Reserved" 11 "Reserved" 12 "Reserved" 13 "Reserved" 14 "Reserved" 15 "Reserved" ;
VAL_ 790 ADASDC_SVS_AvailableSts 0 "SVS_available" 1 "system_fault" 2 "Too_high_speed" 3 "message3" 4 "message4" 5 "message5" 6 "message6" 7 "message7" 8 "message8" 9 "message9" 10 "message10" 11 "message11" 12 "message12" 13 "message13" 14 "Reserved" 15 "Reserved" ;
VAL_ 790 ADASDC_SVS_RrCamBttnShw 0 "Do_not_show_rear_view_camera_button" 1 "Show_rear_view_camera_button" 2 "Show_rear_view_camera_button(fault,_not_Press-able)" 3 "Reserved" ;
VAL_ 790 ADASDC_SVS_WdAnglBttnShw 0 "Don't_show_wide_angle_camera_view_toggle_button" 1 "Show_wide_angle_camera_view_toggle_button" 2 "Show_wide_angle_camera_view_button(fault,_not_Press-able)" 3 "Reserved" ;
VAL_ 790 ADASDC_SVS_FrntWdAnglBttnShw 0 "Do_not_show_front_wide_angle_camera_view_button" 1 "Show_front_wide_angle_camera_view_button" 2 "Show_front_wide_angle_camera_view_button(fault,_not_Press-able)" 3 "Reserved" ;
VAL_ 790 ADASDC_SVS_3DCamBttnShw 0 "Do_not_show_3D_camera_view_button" 1 "Show_3D_camera_view_button" 2 "Show_3D_camera_view_button(fault,_not_Press-able)" 3 "Reserved" ;
VAL_ 790 ADASDC_SVS_AutoVwBttnShw 0 "Do_not_show_auto_camera_view_button" 1 "Show_auto_camera_view_button" 2 "Show_auto_camera_view_button(fault,_not_Press-able)" 3 "Reserved" ;
VAL_ 790 ADASDC_SVS_RearMidBttnShw 0 "Do_not_show_rear_mid_camera_view_button" 1 "Show_rear_mid_camera_view_button" 2 "Show_rear_mid_camera_view_button(fault,_not_Press-able)" 3 "Reserved" ;
VAL_ 790 ADASDC_SVS_FrntMidBttnShw 0 "Do_not_show_front_mid_camera_view_button" 1 "Show_front_mid_camera_view_button" 2 "Show_front_mid_camera_view_button(fault,_not_Press-able)" 3 "Reserved" ;
VAL_ 790 ADASDC_SVS_SplitBttnShw 0 "Do_not_show_split_camera_view_button" 1 "Show_split_camera_view_button" 2 "Show_split_camera_view_button(fault,_not_Press-able)" 3 "Reserved" ;
VAL_ 790 ADASDC_SVS_LeftFlnk3DBttnShw 0 "Do_not_show_left_flank_camera_view_button" 1 "Show_left_flank_camera_view_button" 2 "Show_left_flank_camera_view_button(fault,_not_Press-able)" 3 "Reserved" ;
VAL_ 790 ADASDC_SVS_RightFlnk3DBttnShw 0 "Do_not_show_right_flank_camera_view_button" 1 "Show_right_flank_camera_view_button" 2 "Show_right_flank_camera_view_button(fault,_not_Press-able)" 3 "Reserved" ;
VAL_ 790 ADASDC_SVS_ShowReq 0 "No_Request" 1 "Show_Request" ;
VAL_ 791 ADAS_LeMirrWarnSrc 0 "Not_Active" 1 "BSD" 2 "DOW" 3 "ELKA" 4 "Reserved" 5 "Reserved" 6 "Reserved" 7 "Reserved" ;
VAL_ 791 ADAS_LeMirrWarnReq 0 "Not_Active" 1 "Active_warning_1" 2 "Active_warning_2" 3 "Reserved" ;
VAL_ 791 ADAS_ChimeReq 0 "No_chime" 1 "Engagement" 2 "Disengagement" 3 "Fault_chime" 4 "Warning_light_amber" 5 "Warning_light_yellow" 6 "Warning_light_red" 7 "Overspeed" 8 "Cant_do_that" 9 "Parking_complete" 10 "Zone2" 11 "Zone3" 12 "Zone1" 13 "Reserved" 14 "Reserved" 15 "Reserved" ;
VAL_ 791 ADAS_IDS_WarnTxtReq 0 "No_request" 1 "Minor_fault_detected" 2 "Front_camera_fault" 3 "Radar_fault" 4 "Ultrasonic_sensor_fault" 5 "AEB_fault" 6 "Lane_keeping_system_fault" 7 "ACC_fault" 8 "Surround_view_system_fault" 9 "Driver_monitor_system_fault" 10 "TJA/ICA_fault" 11 "Other_critical_fault" 12 "Evasive_steering_assist_fault" 13 "BSM_ELKA_System_fault" 14 "Lane_Change_Assist_Fault" 15 "Reserved" 16 "Reserved" 17 "Reserved" 18 "Reserved" 19 "Reserved" 20 "Reserved" 21 "AEB_off_/_degraded" 22 "Lane_keeping_system_off_/_degraded" 23 "DCAA_warning_stage_1" 24 "DCAA_warning_stage_2" 25 "DCAA_warning_stage_3" 26 "Hands_on_reminder_/_urgent" 27 "Pay_attention_to_drive_/_gentle" 28 "Pay_attention_to_drive_/_firm" 29 "Pay_attention_to_drive_/_urgent" 30 "Door_opening_traffic_warning" 31 "Door_opening_collision_warning" 32 "AEB_pre-warning" 33 "AEB_acute_warning" 34 "AEB_intervene_(including_brake_jerk)" 35 "Reserved" 36 "Reserved" 37 "Reserved" 38 "Reserved" 39 "Reserved" 40 "Reserved" 41 "Reserved" 42 "Reserved" 43 "Reserved" 44 "Reserved" 45 "Reserved" 46 "Reserved" 47 "Reserved" 48 "Reserved" 49 "Reserved" 50 "Reserved" 51 "Reserved" 52 "Reserved" 53 "Reserved" 54 "Reserved" 55 "Reserved" 56 "Reserved" 57 "Reserved" 58 "Reserved" 59 "Reserved" 60 "Reserved" 61 "Reserved" 62 "Reserved" 63 "Reserved" ;
VAL_ 791 ADAS_RiMirrWarnReq 0 "Not_Active" 1 "Active_warning_1" 2 "Active_warning_2" 3 "Reserved" ;
VAL_ 791 ADAS_IDS_LeWarnReq 0 "Not_Active" 1 "Active_warning_1_Yellow" 2 "Active_warning_2_Yellow_Blinking" 3 "Active_warning_3_Red" 4 "Active_warning_4_Red_Blinking" 5 "Reserved" 6 "Reserved" 7 "Reserved" ;
VAL_ 791 ADAS_IDS_RiWarnReq 0 "Not_Active" 1 "Active_warning_1_Yellow" 2 "Active_warning_2_Yellow_Blinking" 3 "Active_warning_3_Red" 4 "Active_warning_4_Red_Blinking" 5 "Reserved" 6 "Reserved" 7 "Reserved" ;
VAL_ 791 ADAS_IDS_LeWarnSrc 0 "Not_Active" 1 "BSD" 2 "DOW" 3 "ELKA" 4 "Reserved" 5 "Reserved" 6 "Reserved" 7 "Reserved" ;
VAL_ 791 ADAS_IDS_RiWarnSrc 0 "Not_Active" 1 "BSD" 2 "DOW" 3 "ELKA" 4 "Reserved" 5 "Reserved" 6 "Reserved" 7 "Reserved" ;
VAL_ 791 ADAS_SysFltWarnReq 0 "ADAS_Normal" 1 "ADAS_Flt" 2 "ADAS_FltCrtcl" 3 "Reserved" ;
VAL_ 791 ADAS_SysFltTyp 0 "No_fault" 1 "Minor_fault_detected" 2 "Front_camera_fault" 3 "Radar_fault" 4 "Ultrasonic_sensor_fault" 5 "AEB_fault" 6 "Lane_keeping_system_fault" 7 "ACC_fault" 8 "Surround_view_system_fault" 9 "Driver_monitoring_system_fault" 10 "TJA_ICA_fault" 11 "Other_critical_fault" 12 "Blind_spot_monitor_fault" 13 "Evasive_steering_assist_fault" 14 "Reserved" 15 "Reserved" ;
VAL_ 791 ADAS_RiMirrWarnSrc 0 "Not_Active" 1 "BSD" 2 "DOW" 3 "ELKA" 4 "Reserved" 5 "Reserved" 6 "Reserved" 7 "Reserved" ;
VAL_ 791 ADAS_DrvrTakeOvrReq 0 "No_Request" 1 "Request_stage_1" 2 "Request_stage_2" 3 "Request_stage_3" 4 "Stopping" 5 "Vehicle_stopped_and_secured" 6 "Reserved" 7 "Reserved" ;
VAL_ 792 ESP_BrkPedlStsVld 0 "Initializing" 1 "Valid" 2 "Invalid" 3 "Reserved" ;
VAL_ 792 ESP_BrkPedlSts 0 "Brake_Pedal_Not_Pressed" 1 "Brake_Pedal_Pressed" ;
VAL_ 792 ESP_VehSpdVld 0 "Initializing" 1 "Valid" 2 "Invalid" 3 "Reserved" ;
VAL_ 792 ESP_SysActv 0 "No_Telltale_Requested" 1 "Telltale_Requested" ;
VAL_ 792 ESP_LampSwtOffIndcn 0 "No_Telltale_Requested" 1 "Telltale_Requested" ;
VAL_ 792 ESP_FltIndcn_EBD 0 "No_Telltale_Requested" 1 "Telltale_Requested" ;
VAL_ 792 ESP_FltIndcn_ABS 0 "No_Telltale_Requested" 1 "Telltale_Requested" ;
VAL_ 792 ESP_IninModSigIndcn 0 "Not_In_Initialization_Mode" 1 "In_Intialization_Mode" ;
VAL_ 792 ESP_FltIndcn_TCS 0 "No_Telltale_Requested" 1 "Telltale_Requested" ;
VAL_ 792 ESP_CtrlSts_HDC 0 "Off" 1 "On_Active_Braking" 2 "On_Not_Active_Braking" 3 "Reserved" ;
VAL_ 792 ESP_AvlIndcn_HDC 0 "Available" 1 "Not_Available" ;
VAL_ 792 ESP_NoBrkP 0 "Exist_Brk_Force" 1 "No_Brk_Force" ;
VAL_ 792 ESP_RDAEnaFlg 0 "Inactive_not_enabled" 1 "Active_enable" ;
VAL_ 794 ADAS_RAEBAvl 0 "Available" 1 "Not_Available" ;
VAL_ 794 ADAS_FACM_TelltaleReq 0 "FACM_Normal" 1 "FACM_Off" 2 "FACM_Fault_Degraded" 3 "FACM_Intervention" ;
VAL_ 794 ADAS_BACM_WarnSide 0 "None" 1 "WarnLeft" 2 "WarnRight" 3 "Bothsides" 4 "Center" 5 "Reserved" 6 "Reserved" 7 "Reserved" ;
VAL_ 794 ADAS_BrakeIntrvntnSt 0 "Inactive" 1 "Lvl1" 2 "Lvl2" 3 "Brake_Assist" ;
VAL_ 794 ADAS_AEB_Typ 0 "Not_Active" 1 "AEB_standard" 2 "AEB_VRU" 3 "LTAP_AEB" 4 "SCP_AEB" 5 "Rear_AEB" 6 "RCTB" 7 "Reserved" ;
VAL_ 794 ADAS_FACM_SenstvtyPrmpt 0 "No_prompt" 1 "Prompt" ;
VAL_ 794 ADAS_AEBWarnSts 0 "No_warning" 1 "Headway_warning" 2 "Pre-Warning" 3 "Acute_warning_stage_1" 4 "Acute_warning_stage_2" 5 "Reserved" 6 "Reserved" 7 "Reserved" ;
VAL_ 794 ADAS_AEB_RAEB_WarnReq 0 "No_warning" 1 "Warning" ;
VAL_ 794 ADAS_BSM_ELKA_TelltaleReq 0 "BSM_ELKA_Normal" 1 "BSM_ELKA_Off" 2 "BSM_ELKA_Inactive" 3 "BSM_ELKA_Fault_Degraded" 4 "BSM_ELKA_intervention" ;
VAL_ 794 ADAS_ESA_TelltaleReq 0 "ESA_Normal" 1 "ESA_Off" 2 "ESA_Fault_Degraded" 3 "ESA_Intervention" ;
VAL_ 794 ADAS_ELKA_TelltaleReq 0 "ELKA_LKA_Normal" 1 "ELKA_LKA_Off" 2 "ELKA_LKA_Fault_Degraded" 3 "ELKA_LKA_intervention" ;
VAL_ 795 ADAS_LaneCenteringHandsOnRew 0 "No_Request" 1 "First_HandsOn_Request" 2 "Second_HandsOn_Request" 3 "Reserved" 4 "Reserved" 5 "Reserved" 6 "Reserved" 7 "Reserved" ;
VAL_ 796 ADAS_AccTrgSpdDisp 0 "display" 1 "display" 2 "display" 3 "display" 4 "display" 5 "display" 6 "display" 7 "display" 8 "display" 9 "display" 10 "display" 11 "display" 12 "display" 13 "display" 14 "display" 15 "display" 16 "display" 17 "display" 18 "display" 19 "display" 20 "display" 21 "display" 22 "display" 23 "display" 24 "display" 25 "display" 26 "display" 27 "display" 28 "display" 29 "display" 30 "display" 31 "display" 32 "display" 33 "display" 34 "display" 35 "display" 36 "display" 37 "display" 38 "display" 39 "display" 40 "display" 41 "display" 42 "display" 43 "display" 44 "display" 45 "display" 46 "display" 47 "display" 48 "display" 49 "display" 50 "display" 51 "display" 52 "display" 53 "display" 54 "display" 55 "display" 56 "display" 57 "display" 58 "display" 59 "display" 60 "display" 61 "display" 62 "display" 63 "display" 64 "display" 65 "display" 66 "display" 67 "display" 68 "display" 69 "display" 70 "display" 71 "display" 72 "display" 73 "display" 74 "display" 75 "display" 76 "display" 77 "display" 78 "display" 79 "display" 80 "display" 81 "display" 82 "display" 83 "display" 84 "display" 85 "display" 86 "display" 87 "display" 88 "display" 89 "display" 90 "display" 91 "display" 92 "display" 93 "display" 94 "display" 95 "display" 96 "display" 97 "display" 98 "display" 99 "display" 100 "display" 101 "display" 102 "display" 103 "display" 104 "display" 105 "display" 106 "display" 107 "display" 108 "display" 109 "display" 110 "display" 111 "display" 112 "display" 113 "display" 114 "display" 115 "display" 116 "display" 117 "display" 118 "display" 119 "display" 120 "display" 121 "display" 122 "display" 123 "display" 124 "display" 125 "display" 126 "display" 127 "display" 128 "display" 129 "display" 130 "display" 131 "display" 132 "display" 133 "display" 134 "display" 135 "display" 136 "display" 137 "display" 138 "display" 139 "display" 140 "display" 141 "display" 142 "display" 143 "display" 144 "display" 145 "display" 146 "display" 147 "display" 148 "display" 149 "display" 150 "display" 151 "display" 152 "display" 153 "display" 154 "display" 155 "display" 156 "display" 157 "display" 158 "display" 159 "display" 160 "display" 161 "display" 162 "display" 163 "display" 164 "display" 165 "display" 166 "display" 167 "display" 168 "display" 169 "display" 170 "display" 171 "display" 172 "display" 173 "display" 174 "display" 175 "display" 176 "display" 177 "display" 178 "display" 179 "display" 180 "display" 181 "display" 182 "display" 183 "display" 184 "display" 185 "display" 186 "display" 187 "display" 188 "display" 189 "display" 190 "display" 191 "display" 192 "display" 193 "display" 194 "display" 195 "display" 196 "display" 197 "display" 198 "display" 199 "display" 200 "display" 201 "display" 202 "display" 203 "display" 204 "display" 205 "display" 206 "display" 207 "display" 208 "display" 209 "display" 210 "display" 211 "display" 212 "display" 213 "display" 214 "display" 215 "display" 216 "display" 217 "display" 218 "display" 219 "display" 220 "display" 221 "display" 222 "display" 223 "display" 224 "display" 225 "display" 226 "display" 227 "display" 228 "display" 229 "display" 230 "display" 231 "display" 232 "display" 233 "display" 234 "display" 235 "display" 236 "display" 237 "display" 238 "display" 239 "display" 240 "display" 241 "display" 242 "display" 243 "display" 244 "display" 245 "display" 246 "display" 247 "display" 248 "display" 249 "display" 250 "display" 251 "display" 252 "display" 253 "display" 254 "display" 255 "no_display" ;
VAL_ 796 ADAS_DispSpdUnit_ACC 0 "KMH" 1 "MPH" ;
VAL_ 796 ADAS_AccTrgSpdOvrLmt 0 "Target_speed_equal_or_less_than_limit" 1 "Target_speed_over_speed_limit" ;
VAL_ 796 ADAS_TiGapSet_ACC 0 "Invalid" 1 "Time_gap_1" 2 "Time_gap_2" 3 "Time_gap_3" 4 "Time_gap_4" 5 "Reserved" 6 "Reserved" 7 "Reserved" ;
VAL_ 796 ADAS_TiGapRecommendation_ACC 0 "No_recommendation" 1 "Timegap_1_shortest" 2 "Timegap_2" 3 "Timegap_3" 4 "Timegap_4_longest" 5 "Reserved" 6 "Reserved" 7 "Reserved" ;
VAL_ 796 ADAS_ACCIconDisp 0 "No_Display" 1 "White" 2 "Green" 3 "Fault" 4 "Reserved" 5 "Reserved" 6 "Reserved" 7 "Reserved" ;
VAL_ 796 ADAS_ACCDegrdReq 0 "No_request" 1 "Request_driver_to_acknowledge" ;
VAL_ 796 ADAS_ACCFuncTyp 0 "Default_no_function" 1 "Basic_CC" 2 "Advanced_ACC" 3 "ISA" 4 "Fault" 5 "Reserved" 6 "Reserved" 7 "Reserved" ;
VAL_ 801 BCM_ValueLightFrnt_RLS 255 "Invalid" ;
VAL_ 801 BCM_LightReqReason_RLS 0 "Day" 1 "Twilight_Drowning" 2 "Night/Night" 4 "Rainlight-light_switch" 5 "Twilight_and_rainlight" 6 "Night_and_rainlight_Night_and_rain" 8 "Tunnel/Tunnel" 9 "Tunnel_and_Twilight/Tunnel_and_Dawing" 12 "Tunnel_and_rainlight" 13 "Tunnel_and_rainlight_and_Twilight_Tunnel_and_Rainy_and_Dusk" 16 "Underground_car_park_Out_of_Underground_Garage" 20 "Underground_car_park_garage_and_rain_light_Pull_out_of_underground_garage_and_rain" ;
VAL_ 811 ADAS_SelfGlaring 0 "0~10%" 1 "10~20%" 2 "20~30%" 3 "30~40%" 4 "40~50%" 5 "50~60%" 7 "60~70%" 8 "70~80%" 9 "80~90%" 10 "90~100%" 11 "Reserved" 12 "Reserved" 13 "Reserved" 14 "Initating" 15 "Not_Available" ;
VAL_ 811 ADAS_Obj_TrfcStyle 0 "Unknow" 1 "Right_Hand_Traffic" 2 "Left_Hand_Traffic" 3 "Reserved" 4 "Reserved" 5 "Reserved" 6 "Reserved" 7 "Reserved" 8 "Reserved" 9 "Reserved" 10 "Reserved" 11 "Reserved" 12 "Reserved" 13 "Reserved" 14 "Initating" 15 "Not_Available" ;
VAL_ 811 ADAS_CamSts 0 "On_Passive" 1 "On_Active" 2 "On_Reduced_Sight" 3 "On_Faliure" 4 "Off" 5 "Reserved" 6 "Reserved" 7 "Reserved" 8 "Reserved" 9 "Reserved" 10 "Reserved" 11 "Reserved" 12 "Reserved" 13 "Reserved" 14 "Initating" 15 "Not_Available" ;
VAL_ 811 ADAS_ObjNr 0 "No_Object_Detected" 1 "1_Object_Detected" 2 "2_Object_Detected" 3 "3_Object_Detected" 4 "4_Object_Detected" 5 "5_Object_Detected" 6 "6_Object_Detected" 7 "7_Object_Detected" 8 "8_Object_Detected" 9 "Reserved" 10 "Reserved" 11 ">8_Object_Detected" 12 "Reserved" 13 "Reserved" 14 "Initating" 15 "Not_Available" ;
VAL_ 811 ADAS_AmbLi 0 "No_Object_Detected" 1 "Day" 2 "Night" 3 "Reserved" 4 "Reserved" 5 "Reserved" 6 "Reserved" 7 "Reserved" 8 "Reserved" 9 "Reserved" 10 "Reserved" 11 "Reserved" 12 "Reserved" 13 "Reserved" 14 "Initating" 15 "Not_Available" ;
VAL_ 811 ADAS_RoadIllmn 0 "No_Detected" 1 "Detected" 2 "Reserved" 3 "Reserved" 4 "Reserved" 5 "Reserved" 6 "Reserved" 7 "Reserved" 8 "Reserved" 9 "Reserved" 10 "Reserved" 11 "Reserved" 12 "Reserved" 13 "Reserved" 14 "Initating" 15 "Not_Available" ;
VAL_ 813 ADAS_Obj3_ID 0 "No_Object_Detected" ;
VAL_ 813 ADAS_Obj3_Conf 0 "Low" 1 "High" ;
VAL_ 813 ADAS_Obj3_Height 0 "Toward_Ego_Vehicle" 1 "Awat_from_Ego_Vehicle" ;
VAL_ 813 ADAS_Obj3_LongDistSign 0 "Positive_Right" 1 "Negative_Left" ;
VAL_ 813 ADAS_Obj3_LatDistSign 0 "Positive_Right" 1 "Negative_Left" ;
VAL_ 813 ADAS_Obj3_Classification 0 "Car" 1 "Truck" 2 "Motorcycle" 3 "Bicycle" 4 "Pedestrian" 5 "Animal_(Not_implemented)" 6 "General_Object_Unknown_size" 7 "General_Object_Small" 8 "General_Object_Large" 9 "Reserved" 10 "Reserved" 11 "Reserved" 12 "Reserved" 13 "Reserved" 14 "Reserved" 15 "Reserved" ;
VAL_ 813 ADAS_VVP_ICC_Obj3BrkLght 0 "Off" 1 "On" ;
VAL_ 813 ADAS_Obj3_ClassConf 0 "25_percent" 1 "50_percent" 2 "75_percent" 3 "100_percent" ;
VAL_ 815 ADAS_Obj6_ID 0 "No_Object_Detected" ;
VAL_ 815 ADAS_Obj6_Conf 0 "Low" 1 "High" ;
VAL_ 815 ADAS_Obj6_Height 0 "Toward_Ego_Vehicle" 1 "Awat_from_Ego_Vehicle" ;
VAL_ 815 ADAS_Obj6_LongDistSign 0 "Positive_Right" 1 "Negative_Left" ;
VAL_ 815 ADAS_Obj6_LatDistSign 0 "Positive_Right" 1 "Negative_Left" ;
VAL_ 815 ADAS_Obj6_Classification 0 "Car" 1 "Truck" 2 "Motorcycle" 3 "Bicycle" 4 "Pedestrian" 5 "Animal_(Not_implemented)" 6 "General_Object_Unknown_size" 7 "General_Object_Small" 8 "General_Object_Large" 9 "Reserved" 10 "Reserved" 11 "Reserved" 12 "Reserved" 13 "Reserved" 14 "Reserved" 15 "Reserved" ;
VAL_ 815 ADAS_VVP_ICC_Obj6BrkLght 0 "Off" 1 "On" ;
VAL_ 815 ADAS_Obj6_ClassConf 0 "25_percent" 1 "50_percent" 2 "75_percent" 3 "100_percent" ;
VAL_ 819 BCM_KL15_Off_Announcement 0 "NotAvailable" 1 "No_Announcement" 2 "KL15_shutdown_announced" 3 "Reserved" ;
VAL_ 819 BCM_IG1Sts 0 "NotAvailable" 1 "Inactive" 2 "Active" 3 "Reserved" ;
VAL_ 819 BCM_PwrMod 0 "Off" 1 "ACC_(Reserved)" 2 "IGN_On" 3 "Crank_Pending_(Power_Anti-theft_Certification_Process)" 4 "Run" 5 "Crank_Off_(Reserved)" 6 "Reserved" 7 "Reserved" ;
VAL_ 819 BCM_PwrModVld 0 "Initializing" 1 "Valid" 2 "Invalid" 3 "Reserved" ;
VAL_ 819 BCM_BrkSwtSts 0 "No_Pressed" 1 "Pressed" ;
VAL_ 819 BCM_IG1StsVld_CAPE 0 "Initializing" 1 "Valid" 2 "Invalid" 3 "Reserved" ;
VAL_ 819 BCM_IG2StsVld_CAPE 0 "Initializing" 1 "Valid" 2 "Invalid" 3 "Reserved" ;
VAL_ 819 BCM_KL30s_L 0 "Not_Available" 1 "Inactive" 2 "Active" 3 "Reserved" ;
VAL_ 819 BCM_IG2Sts 0 "Not_Available" 1 "Inactive" 2 "Active" 3 "Reserved" ;
VAL_ 819 BCM_InteriorSwtSt 0 "Inactive" 1 "pressed" 2 "reserved" 3 "reserved" ;
